VERSION ""

NS_ :

BS_:

BU_: SGW RFHM MPAD IPC GNMM EVCU2 ESL ECM DTCM DMSM BSM BCM AGSM ADCAM

BO_ 2654339199 PDC_INFO_FD_VRM: 12 SGW
 SG_ GenericFailSts_FD08_VRM : 5|1@0+ (1,0) [0|1] "" Vector__XXX
 SG_ EOL_FD08_VRM : 7|1@0+ (1,0) [0|1] "-"  Vector__XXX
 SG_ CurrentFailSts_FD08_VRM : 6|1@0+ (1,0) [0|1] "" Vector__XXX
 SG_ WakeupSource_FD08_VRM : 23|8@0+ (1,0) [0|255] "" Vector__XXX
 SG_ PreviousCanNMState_FD08_VRM : 11|4@0+ (1,0) [0|15] "" Vector__XXX
 SG_ DES_FD08_VRM : 4|2@0+ (1,0) [0|3] "" Vector__XXX
 SG_ CurrentCanNMState_FD08_VRM : 15|4@0+ (1,0) [0|15] "" Vector__XXX
 SG_ StayActiveSource_FD08_VRM : 31|64@0+ (1,0) [0|18446744073709600000] "" Vector__XXX

BO_ 2654339107 PDC_INFO_FD_TBM: 12 SGW
 SG_ GenericFailSts_FD08_TBM : 5|1@0+ (1,0) [0|1] "" BCM
 SG_ EOL_FD08_TBM : 7|1@0+ (1,0) [0|1] "-"  BCM
 SG_ CurrentFailSts_FD08_TBM : 6|1@0+ (1,0) [0|1] "" BCM
 SG_ WakeupSource_FD08_TBM : 23|8@0+ (1,0) [0|255] "" Vector__XXX
 SG_ PreviousCanNMState_FD08_TBM : 11|4@0+ (1,0) [0|15] "" Vector__XXX
 SG_ DES_FD08_TBM : 4|2@0+ (1,0) [0|3] "" Vector__XXX
 SG_ CurrentCanNMState_FD08_TBM : 15|4@0+ (1,0) [0|15] "" Vector__XXX
 SG_ StayActiveSource_FD08_TBM : 31|64@0+ (1,0) [0|18446744073709551615] "" Vector__XXX

BO_ 2654339075 PDC_INFO_FD_IPC: 12 IPC
 SG_ GenericFailSts_FD03_IPC : 5|1@0+ (1,0) [0|1] "" SGW,BCM
 SG_ EOL_FD03_IPC : 7|1@0+ (1,0) [0|1] "-"  SGW,BCM
 SG_ CurrentFailSts_FD03_IPC : 6|1@0+ (1,0) [0|1] "" SGW,BCM
 SG_ WakeupSource_FD03_IPC : 23|8@0+ (1,0) [0|255] "" SGW
 SG_ PreviousCanNMState_FD03_IPC : 11|4@0+ (1,0) [0|15] "" SGW
 SG_ DES_FD03_IPC : 4|2@0+ (1,0) [0|3] "" SGW
 SG_ CurrentCanNMState_FD03_IPC : 15|4@0+ (1,0) [0|15] "" SGW
 SG_ StayActiveSource_FD03_IPC : 31|64@0+ (1,0) [0|18446744073709600000] "" SGW

BO_ 2654339216 PDC_INFO_FD_GNMM: 12 GNMM
 SG_ GenericFailSts_FD03_GNMM : 5|1@0+ (1,0) [0|1] "" SGW,BCM
 SG_ EOL_FD03_GNMM : 7|1@0+ (1,0) [0|1] "-"  SGW,BCM
 SG_ CurrentFailSts_FD03_GNMM : 6|1@0+ (1,0) [0|1] "" SGW,BCM
 SG_ WakeupSource_FD03_GNMM : 23|8@0+ (1,0) [0|255] "" SGW
 SG_ PreviousCanNMState_FD03_GNMM : 11|4@0+ (1,0) [0|15] "" SGW
 SG_ DES_FD03_GNMM : 4|2@0+ (1,0) [0|3] "" SGW
 SG_ CurrentCanNMState_FD03_GNMM : 15|4@0+ (1,0) [0|3] "" SGW
 SG_ StayActiveSource_FD03_GNMM : 31|64@0+ (1,0) [0|18446744073709551615] "" SGW

BO_ 2654339108 PDC_INFO_FD_ETM: 12 SGW
 SG_ GenericFailSts_FD08_ETM : 5|1@0+ (1,0) [0|1] "" BCM
 SG_ EOL_FD08_ETM : 7|1@0+ (1,0) [0|1] "-"  BCM
 SG_ CurrentFailSts_FD08_ETM : 6|1@0+ (1,0) [0|1] "" BCM
 SG_ WakeupSource_FD08_ETM : 23|8@0+ (1,0) [0|255] "" Vector__XXX
 SG_ PreviousCanNMState_FD08_ETM : 11|4@0+ (1,0) [0|15] "" Vector__XXX
 SG_ DES_FD08_ETM : 4|2@0+ (1,0) [0|3] "" Vector__XXX
 SG_ CurrentCanNMState_FD08_ETM : 15|4@0+ (1,0) [0|15] "" Vector__XXX
 SG_ StayActiveSource_FD08_ETM : 31|64@0+ (1,0) [0|18446744073709551615] "" Vector__XXX

BO_ 2654339093 PDC_INFO_FD_ESL: 12 ESL
 SG_ GenericFailSts_FD03_ESL : 5|1@0+ (1,0) [0|1] "" SGW,BCM
 SG_ EOL_FD03_ESL : 7|1@0+ (1,0) [0|1] "-"  SGW,BCM
 SG_ CurrentFailSts_FD03_ESL : 6|1@0+ (1,0) [0|1] "" SGW,BCM
 SG_ WakeupSource_FD03_ESL : 23|8@0+ (1,0) [0|255] "" SGW
 SG_ PreviousCanNMState_FD03_ESL : 11|4@0+ (1,0) [0|15] "" SGW
 SG_ DES_FD03_ESL : 4|2@0+ (1,0) [0|3] "" SGW
 SG_ CurrentCanNMState_FD03_ESL : 15|4@0+ (1,0) [0|15] "" SGW
 SG_ StayActiveSource_FD03_ESL : 31|64@0+ (1,0) [0|18446744073709600000] "" SGW

BO_ 2654339172 PDC_INFO_FD_DTV: 12 SGW
 SG_ GenericFailSts_FD08_DTV : 5|1@0+ (1,0) [0|1] "" BCM
 SG_ EOL_FD08_DTV : 7|1@0+ (1,0) [0|1] "-"  BCM
 SG_ CurrentFailSts_FD08_DTV : 6|1@0+ (1,0) [0|1] "" BCM
 SG_ WakeupSource_FD08_DTV : 23|8@0+ (1,0) [0|255] "" Vector__XXX
 SG_ PreviousCanNMState_FD08_DTV : 11|4@0+ (1,0) [0|15] "" Vector__XXX
 SG_ DES_FD08_DTV : 4|2@0+ (1,0) [0|3] "" Vector__XXX
 SG_ CurrentCanNMState_FD08_DTV : 15|4@0+ (1,0) [0|15] "" Vector__XXX
 SG_ StayActiveSource_FD08_DTV : 31|64@0+ (1,0) [0|18446744073709551615] "" Vector__XXX

BO_ 2654339139 PDC_INFO_FD_DTCM: 12 DTCM
 SG_ GenericFailSts_FD03_DTCM : 5|1@0+ (1,0) [0|1] "" SGW,BCM
 SG_ EOL_FD03_DTCM : 7|1@0+ (1,0) [0|1] "-"  SGW,BCM
 SG_ CurrentFailSts_FD03_DTCM : 6|1@0+ (1,0) [0|1] "" SGW,BCM
 SG_ WakeupSource_FD03_DTCM : 23|8@0+ (1,0) [0|255] "" SGW
 SG_ PreviousCanNMState_FD03_DTCM : 11|4@0+ (1,0) [0|15] "" SGW
 SG_ DES_FD03_DTCM : 4|2@0+ (1,0) [0|3] "" SGW
 SG_ CurrentCanNMState_FD03_DTCM : 15|4@0+ (1,0) [0|15] "" SGW
 SG_ StayActiveSource_FD03_DTCM : 31|64@0+ (1,0) [0|18446744073709600000] "" SGW

BO_ 2654339225 PDC_INFO_FD_DMSM: 12 DMSM
 SG_ GenericFailSts_FD03_DMSM : 5|1@0+ (1,0) [0|1] "" SGW,BCM
 SG_ EOL_FD03_DMSM : 7|1@0+ (1,0) [0|1] "-"  SGW,BCM
 SG_ CurrentFailSts_FD03_DMSM : 6|1@0+ (1,0) [0|1] "" SGW,BCM
 SG_ WakeupSource_FD03_DMSM : 23|8@0+ (1,0) [0|255] "" SGW
 SG_ PreviousCanNMState_FD03_DMSM : 11|4@0+ (1,0) [0|15] "" SGW
 SG_ DES_FD03_DMSM : 4|2@0+ (1,0) [0|3] "" SGW
 SG_ CurrentCanNMState_FD03_DMSM : 15|4@0+ (1,0) [0|15] "" SGW
 SG_ StayActiveSource_FD03_DMSM : 31|64@0+ (1,0) [0|18446744073709600000] "" SGW

BO_ 2654339078 PDC_INFO_FD_BSM: 12 BSM
 SG_ GenericFailSts_FD03_BSM : 5|1@0+ (1,0) [0|1] "" SGW,BCM
 SG_ EOL_FD03_BSM : 7|1@0+ (1,0) [0|1] "-"  SGW,BCM
 SG_ DES_FD03_BSM : 4|2@0+ (1,0) [0|1] "" SGW
 SG_ CurrentFailSts_FD03_BSM : 6|1@0+ (1,0) [0|1] "" SGW,BCM
 SG_ WakeupSource_FD03_BSM : 23|8@0+ (1,0) [0|255] "" SGW
 SG_ PreviousCanNMState_FD03_BSM : 11|4@0+ (1,0) [0|15] "" SGW
 SG_ CurrentCanNMState_FD03_BSM : 15|4@0+ (1,0) [0|15] "" SGW
 SG_ StayActiveSource_FD03_BSM : 31|64@0+ (1,0) [0|18446744073709551615] "" SGW

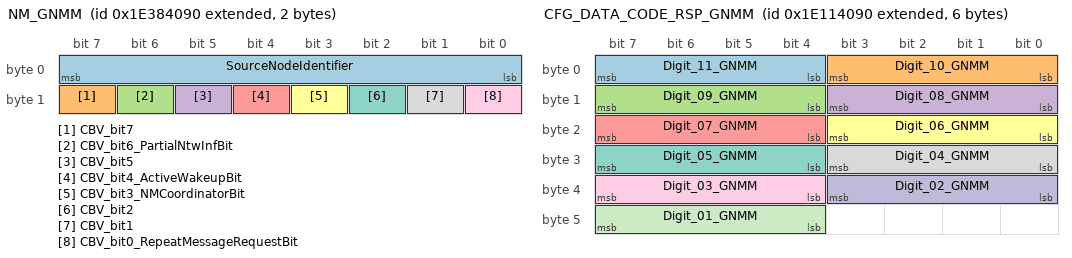
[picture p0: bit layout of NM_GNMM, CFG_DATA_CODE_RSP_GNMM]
BO_ 2654486672 NM_GNMM: 2 GNMM
 SG_ SourceNodeIdentifier : 7|8@0+ (1,0) [0|255] "-"  ADCAM,MPAD,EVCU2,SGW,AGSM,ESL,BCM,BSM,IPC,RFHM,ECM,DTCM
 SG_ CBV_bit7 : 15|1@0+ (1,0) [0|1] "" ADCAM,MPAD,EVCU2,SGW,AGSM,ESL,BCM,BSM,IPC,RFHM,ECM,DTCM
 SG_ CBV_bit6_PartialNtwInfBit : 14|1@0+ (1,0) [0|1] "" ADCAM,MPAD,EVCU2,SGW,AGSM,ESL,BCM,BSM,IPC,RFHM,ECM,DTCM
 SG_ CBV_bit5 : 13|1@0+ (1,0) [0|1] "" ADCAM,MPAD,EVCU2,SGW,AGSM,ESL,BCM,BSM,IPC,RFHM,ECM,DTCM
 SG_ CBV_bit4_ActiveWakeupBit : 12|1@0+ (1,0) [0|1] "" ADCAM,MPAD,EVCU2,SGW,AGSM,ESL,BCM,BSM,IPC,RFHM,ECM,DTCM
 SG_ CBV_bit3_NMCoordinatorBit : 11|1@0+ (1,0) [0|1] "" ADCAM,MPAD,EVCU2,SGW,AGSM,ESL,BCM,BSM,IPC,RFHM,ECM,DTCM
 SG_ CBV_bit2 : 10|1@0+ (1,0) [0|1] "" ADCAM,MPAD,EVCU2,SGW,AGSM,ESL,BCM,BSM,IPC,RFHM,ECM,DTCM
 SG_ CBV_bit1 : 9|1@0+ (1,0) [0|1] "" ADCAM,MPAD,EVCU2,SGW,AGSM,ESL,BCM,BSM,IPC,RFHM,ECM,DTCM
 SG_ CBV_bit0_RepeatMessageRequestBit : 8|1@0+ (1,0) [0|1] "" ADCAM,MPAD,EVCU2,SGW,AGSM,ESL,BCM,BSM,IPC,RFHM,ECM,DTCM

BO_ 754 IBS3_DATA_1_2: 32 BCM
 SG_ VoltBattFailStatus_2 : 102|1@0+ (1,0) [0|1] "" EVCU2
 SG_ RsErrIBS3_2 : 100|1@0+ (1,0) [0|1] "" EVCU2
 SG_ IBS3_Error_Internal_2 : 101|1@0+ (1,0) [0|1] "" EVCU2
 SG_ CurrBattFailStatus_2 : 103|1@0+ (1,0) [0|1] "" EVCU2
 SG_ MessageCounter_IBS3DATA1_2 : 179|4@0+ (1,0) [0|15] ""  EVCU2
 SG_ CRC_IBS3DATA1_2 : 191|8@0+ (1,0) [0|255] ""  EVCU2

BO_ 1460 FOTA_MASTER: 32 SGW
 SG_ Safe_State : 0|1@0+ (1,0) [0|1] "" ADCAM,MPAD
 SG_ FOTA_Status : 7|4@0+ (1,0) [0|15] "" ADCAM,MPAD,BCM,BSM,IPC,ECM
 SG_ FOTA_Purge : 13|1@0+ (1,0) [0|1] "" ADCAM,MPAD
 SG_ FOTA_Installation_Status : 23|2@0+ (1,0) [0|3] "" EVCU2,RFHM
 SG_ FOTA_Install_Type : 21|2@0+ (1,0) [0|3] "" EVCU2,ECM
 SG_ MPAD_Big_ECU_Package : 19|1@0+ (1,0) [0|1] "" MPAD
 SG_ ADCAM_Big_ECU_Package : 8|1@0+ (1,0) [0|1] "" ADCAM
 SG_ MessageCounter_FOTA_MASTER : 179|4@0+ (1,0) [0|15] "-"  ADCAM,MPAD,EVCU2,BCM,BSM,IPC,RFHM
 SG_ CRC_FOTA_MASTER : 191|8@0+ (1,0) [0|255] "-"  ADCAM,MPAD,EVCU2,BCM,BSM,IPC,RFHM
 SG_ MPFC_Big_ECU_Package : 32|1@0+ (1,0) [0|1] "" MPAD

BO_ 1438 DRV_MONITOR1_FD: 32 DMSM
 SG_ MessageCounter_DRV_MONITOR1 : 179|4@0+ (1,0) [0|15] "-"  MPAD,BCM
 SG_ Driver_Presence : 15|1@0+ (1,0) [0|1] "" MPAD,SGW,BCM
 SG_ DMSM_System_Stat : 29|2@0+ (1,0) [0|3] "" MPAD,BCM
 SG_ DM_Zone_Track_Conf : 27|4@0+ (10,0) [0|150] "%"  MPAD,BCM
 SG_ DM_Zone_Track : 35|3@0+ (1,0) [0|7] "" MPAD,BCM
 SG_ DM_Drowsy_State : 37|2@0+ (1,0) [0|3] "" MPAD,SGW,BCM
 SG_ DM_Drowsy_Micro : 7|1@0+ (1,0) [0|1] "" MPAD,BCM
 SG_ DM_Drowsy_Instant : 14|7@0+ (1,0) [0|127] "%"  MPAD,BCM
 SG_ DM_Drowsy_Conf : 23|4@0+ (10,0) [0|150] "%"  MPAD,BCM
 SG_ DM_Distract_State : 39|2@0+ (1,0) [0|3] "" MPAD,SGW,BCM
 SG_ DM_Distract_Instant : 6|7@0+ (1,0) [0|127] "%"  MPAD,BCM
 SG_ DM_Distract_Conf : 19|4@0+ (10,0) [0|150] "%"  MPAD,BCM
 SG_ DM_Camera_Blind : 31|2@0+ (1,0) [0|3] "" MPAD,BCM
 SG_ CRC_DRV_MONITOR1 : 191|8@0+ (1,0) [0|255] "-"  MPAD,BCM
 SG_ DM_Eyes_Tracked : 32|1@0+ (1,0) [0|1] "" MPAD,BCM
 SG_ DM_Steering_Angle_Blockage : 47|1@0+ (1,0) [0|1] "" MPAD,BCM
 SG_ MAC_DRV_MONITOR1 : 215|48@0+ (1,0) [0|0] "-"  MPAD,BCM
 SG_ Cntr_DRV_MONITOR1 : 199|16@0+ (1,0) [0|0] "-"  MPAD,BCM
 SG_ DM_Unresponsive : 42|2@0+ (1,0) [0|3] "-"  MPAD,BCM
 SG_ DM_Drowsy_Level : 46|4@0+ (1,0) [0|15] "-"  MPAD,BCM
 SG_ DM_Distracted_Level : 55|4@0+ (1,0) [0|15] "-"  MPAD,BCM
 SG_ DM_Drowsy_Instant_Seconds : 70|7@0+ (1,0) [0|127] "s"  MPAD
 SG_ DM_Distract_Instant_Seconds : 62|7@0+ (1,0) [0|127] "s"  MPAD

BO_ 2564485428 DIAGNOSTIC_RESPONSE_GNMM: 8 GNMM
 SG_ N_PDU : 7|64@0+ (1,0) [0|0] "" SGW

BO_ 2564486464 DIAGNOSTIC_RESPONSE_FOTA_BCM: 64 BCM
 SG_ N_PDU : 7|64@0+ (1,0) [0|0] "" SGW

BO_ 2564485684 DIAGNOSTIC_RESPONSE_FD_GNMM: 64 GNMM
 SG_ N_PDU : 7|64@0+ (1,0) [0|0] "" SGW

BO_ 2564485783 DIAGNOSTIC_RESPONSE_FD_DMSM: 64 DMSM
 SG_ N_PDU : 7|64@0+ (1,0) [0|0] "" SGW

BO_ 2564485527 DIAGNOSTIC_RESPONSE_DMSM: 8 DMSM
 SG_ N_PDU : 7|64@0+ (1,0) [0|0] "" SGW

BO_ 2564437233 DIAGNOSTIC_REQUEST_GNMM: 8 SGW
 SG_ N_PDU : 7|64@0+ (1,0) [0|0] "" GNMM

BO_ 2564440309 DIAGNOSTIC_REQUEST_FOTA_BCM: 64 SGW
 SG_ N_PDU : 7|64@0+ (1,0) [0|0] "" BCM

BO_ 2564437234 DIAGNOSTIC_REQUEST_FD_GNMM: 64 SGW
 SG_ N_PDU : 7|64@0+ (1,0) [0|0] "" GNMM

BO_ 2564462578 DIAGNOSTIC_REQUEST_FD_DMSM: 64 SGW
 SG_ N_PDU : 7|64@0+ (1,0) [0|0] "" DMSM

BO_ 2564462577 DIAGNOSTIC_REQUEST_DMSM: 8 SGW
 SG_ N_PDU : 7|64@0+ (1,0) [0|0] "" DMSM

BO_ 2651930768 CFG_DATA_CODE_RSP_GNMM: 6 GNMM
 SG_ Digit_11_GNMM : 7|4@0+ (1,0) [0|15] "-"  BCM
 SG_ Digit_10_GNMM : 3|4@0+ (1,0) [0|15] "-"  BCM
 SG_ Digit_09_GNMM : 15|4@0+ (1,0) [0|15] "-"  BCM
 SG_ Digit_08_GNMM : 11|4@0+ (1,0) [0|15] "-"  BCM
 SG_ Digit_07_GNMM : 23|4@0+ (1,0) [0|15] "-"  BCM
 SG_ Digit_06_GNMM : 19|4@0+ (1,0) [0|15] "-"  BCM
 SG_ Digit_05_GNMM : 31|4@0+ (1,0) [0|15] "-"  BCM
 SG_ Digit_04_GNMM : 27|4@0+ (1,0) [0|15] "-"  BCM
 SG_ Digit_03_GNMM : 39|4@0+ (1,0) [0|15] "-"  BCM
 SG_ Digit_02_GNMM : 35|4@0+ (1,0) [0|15] "-"  BCM
 SG_ Digit_01_GNMM : 47|4@0+ (1,0) [0|15] "-"  BCM

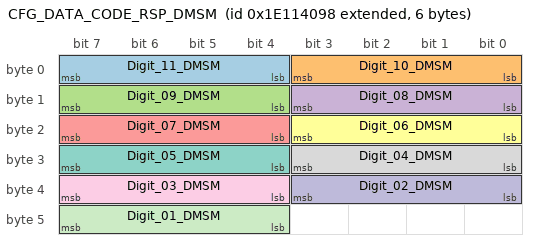
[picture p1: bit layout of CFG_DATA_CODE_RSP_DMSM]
BO_ 2651930776 CFG_DATA_CODE_RSP_DMSM: 6 DMSM
 SG_ Digit_11_DMSM : 7|4@0+ (1,0) [0|15] "-"  BCM
 SG_ Digit_10_DMSM : 3|4@0+ (1,0) [0|15] "-"  BCM
 SG_ Digit_09_DMSM : 15|4@0+ (1,0) [0|15] "-"  BCM
 SG_ Digit_08_DMSM : 11|4@0+ (1,0) [0|15] "-"  BCM
 SG_ Digit_07_DMSM : 23|4@0+ (1,0) [0|15] "-"  BCM
 SG_ Digit_06_DMSM : 19|4@0+ (1,0) [0|15] "-"  BCM
 SG_ Digit_05_DMSM : 31|4@0+ (1,0) [0|15] "-"  BCM
 SG_ Digit_04_DMSM : 27|4@0+ (1,0) [0|15] "-"  BCM
 SG_ Digit_03_DMSM : 39|4@0+ (1,0) [0|15] "-"  BCM
 SG_ Digit_02_DMSM : 35|4@0+ (1,0) [0|15] "-"  BCM
 SG_ Digit_01_DMSM : 47|4@0+ (1,0) [0|15] "-"  BCM

BO_ 524 BRAKE2_FD_2: 32 BCM
 SG_ VehicleStandStillSts_B2 : 47|2@0+ (1,0) [0|2] "" MPAD
 SG_ BSM2_OpStat : 50|3@0+ (1,0) [0|5] "" MPAD,BSM
 SG_ Brake_OpStat_Sec : 53|3@0+ (1,0) [0|5] "" MPAD
 SG_ MessageCounter_BRAKE2_2 : 179|4@0+ (1,0) [0|15] "-"  BSM
 SG_ CRC_BRAKE2_2 : 191|8@0+ (1,0) [0|255] "-"  BSM

BO_ 257 BRAKE2_FD_1: 64 BCM
 SG_ Ft_RrTrqCoupling_ModeRq_B2 : 158|2@0+ (1,0) [0|3] "-"  DTCM
 SG_ Ft_RrAxleCoupling_TrqRq_B2 : 143|8@0+ (12,0) [0|3060] "Nm"  DTCM

CM_ SG_ 2654339199 CurrentCanNMState_FD08_VRM "Indicates that CanNM state the ECU is currently executing";
CM_ SG_ 2654339199 CurrentFailSts_FD08_VRM "Indicates the presence/absence of at least one DTC with DTCStatus = present in the System Memory";
CM_ SG_ 2654339199 DES_FD08_VRM "Indicates whether the ECU?s CAN cell is in either ErrorActive, or ErrorPassive state OR has just now recovered from a BusOff condition";
CM_ SG_ 2654339199 EOL_FD08_VRM "Indicates if the ECU requires configuration data at the assembly plant End Of Line";
CM_ SG_ 2654339199 GenericFailSts_FD08_VRM "Indicates the presence/absent of at least one DTC in the System Memory";
CM_ SG_ 2654339199 PreviousCanNMState_FD08_VRM "Indicates the last CanNM state that the ECU existed in";
CM_ SG_ 2654339199 StayActiveSource_FD08_VRM "Indicates the source that requests the ECU to stay active";
CM_ SG_ 2654339199 WakeupSource_FD08_VRM "Indicates the reason the ECU was most recently awakened";
CM_ SG_ 2654339107 CurrentCanNMState_FD08_TBM "Indicates that CanNM state the ECU is currently executing";
CM_ SG_ 2654339107 CurrentFailSts_FD08_TBM "Indicates the presence/absence of at least one DTC with DTCStatus = present in the System Memory";
CM_ SG_ 2654339107 DES_FD08_TBM "Indicates whether the ECU?s CAN cell is in either ErrorActive, or ErrorPassive state OR has just now recovered from a BusOff condition";
CM_ SG_ 2654339107 EOL_FD08_TBM "Indicates if the ECU requires configuration data at the assembly plant End Of Line";
CM_ SG_ 2654339107 GenericFailSts_FD08_TBM "Indicates the presence/absent of at least one DTC in the System Memory";
CM_ SG_ 2654339107 PreviousCanNMState_FD08_TBM "Indicates the last CanNM state that the ECU existed in";
CM_ SG_ 2654339107 StayActiveSource_FD08_TBM "Indicates the source that requests the ECU to stay active";
CM_ SG_ 2654339107 WakeupSource_FD08_TBM "Indicates the reason the ECU was most recently awakened";
CM_ SG_ 2654339075 CurrentCanNMState_FD03_IPC "Indicates that CanNM state the ECU is currently executing";
CM_ SG_ 2654339075 CurrentFailSts_FD03_IPC "Indicates the presence/absence of at least one DTC with DTCStatus = present in the System Memory";
CM_ SG_ 2654339075 DES_FD03_IPC "Indicates whether the ECU?s CAN cell is in either ErrorActive, or ErrorPassive state OR has just now recovered from a BusOff condition";
CM_ SG_ 2654339075 EOL_FD03_IPC "Indicates if the ECU requires configuration data at the assembly plant End Of Line";
CM_ SG_ 2654339075 GenericFailSts_FD03_IPC "Indicates the presence/absent of at least one DTC in the System Memory";
CM_ SG_ 2654339075 PreviousCanNMState_FD03_IPC "Indicates the last CanNM state that the ECU existed in";
CM_ SG_ 2654339075 StayActiveSource_FD03_IPC "Indicates the source that requests the ECU to stay active";
CM_ SG_ 2654339075 WakeupSource_FD03_IPC "Indicates the reason the ECU was most recently awakened";
CM_ SG_ 2654339216 CurrentCanNMState_FD03_GNMM "Indicates that CanNM state the ECU is currently executing";
CM_ SG_ 2654339216 DES_FD03_GNMM "Indicates whether the ECU?s CAN cell is in either ErrorActive, or ErrorPassive state OR has just now recovered from a BusOff condition";
CM_ SG_ 2654339216 EOL_FD03_GNMM "Indicates if the ECU requires configuration data at the assembly plant End Of Line";
CM_ SG_ 2654339216 GenericFailSts_FD03_GNMM "Indicates the presence/absent of at least one DTC in the System Memory";
CM_ SG_ 2654339216 WakeupSource_FD03_GNMM "Indicates the reason the ECU was most recently awakened";
CM_ SG_ 2654339216 StayActiveSource_FD03_GNMM "Indicates the source that requests the ECU to stay active";
CM_ SG_ 2654339216 PreviousCanNMState_FD03_GNMM "Indicates the last CanNM state that the ECU existed in";
CM_ SG_ 2654339216 CurrentFailSts_FD03_GNMM "Indicates the presence/absence of at least one DTC with DTCStatus = present in the System Memory";
CM_ SG_ 2654339108 PreviousCanNMState_FD08_ETM "Indicates the last CanNM state that the ECU existed in";
CM_ SG_ 2654339108 StayActiveSource_FD08_ETM "Indicates the source that requests the ECU to stay active";
CM_ SG_ 2654339108 WakeupSource_FD08_ETM "Indicates the reason the ECU was most recently awakened";
CM_ SG_ 2654339108 GenericFailSts_FD08_ETM "Indicates the presence/absent of at least one DTC in the System Memory";
CM_ SG_ 2654339108 EOL_FD08_ETM "Indicates if the ECU requires configuration data at the assembly plant End Of Line";
CM_ SG_ 2654339108 DES_FD08_ETM "Indicates whether the ECU?s CAN cell is in either ErrorActive, or ErrorPassive state OR has just now recovered from a BusOff condition";
CM_ SG_ 2654339108 CurrentCanNMState_FD08_ETM "Indicates that CanNM state the ECU is currently executing";
CM_ SG_ 2654339108 CurrentFailSts_FD08_ETM "Indicates the presence/absence of at least one DTC with DTCStatus = present in the System Memory";
CM_ SG_ 2654339093 StayActiveSource_FD03_ESL "Indicates the source that requests the ECU to stay active";
CM_ SG_ 2654339093 GenericFailSts_FD03_ESL "Indicates the presence/absent of at least one DTC in the System Memory";
CM_ SG_ 2654339093 PreviousCanNMState_FD03_ESL "Indicates the last CanNM state that the ECU existed in";
CM_ SG_ 2654339093 WakeupSource_FD03_ESL "Indicates the reason the ECU was most recently awakened";
CM_ SG_ 2654339093 CurrentCanNMState_FD03_ESL "Indicates that CanNM state the ECU is currently executing";
CM_ SG_ 2654339093 CurrentFailSts_FD03_ESL "Indicates the presence/absence of at least one DTC with DTCStatus = present in the System Memory";
CM_ SG_ 2654339093 DES_FD03_ESL "Indicates whether the ECU?s CAN cell is in either ErrorActive, or ErrorPassive state OR has just now recovered from a BusOff condition";
CM_ SG_ 2654339093 EOL_FD03_ESL "Indicates if the ECU requires configuration data at the assembly plant End Of Line";
CM_ SG_ 2654339172 EOL_FD08_DTV "Indicates if the ECU requires configuration data at the assembly plant End Of Line";
CM_ SG_ 2654339172 GenericFailSts_FD08_DTV "Indicates the presence/absent of at least one DTC in the System Memory";
CM_ SG_ 2654339172 PreviousCanNMState_FD08_DTV "Indicates the last CanNM state that the ECU existed in";
CM_ SG_ 2654339172 StayActiveSource_FD08_DTV "Indicates the source that requests the ECU to stay active";
CM_ SG_ 2654339172 WakeupSource_FD08_DTV "Indicates the reason the ECU was most recently awakened";
CM_ SG_ 2654339172 CurrentCanNMState_FD08_DTV "Indicates that CanNM state the ECU is currently executing";
CM_ SG_ 2654339172 CurrentFailSts_FD08_DTV "Indicates the presence/absence of at least one DTC with DTCStatus = present in the System Memory";
CM_ SG_ 2654339172 DES_FD08_DTV "Indicates whether the ECU?s CAN cell is in either ErrorActive, or ErrorPassive state OR has just now recovered from a BusOff condition";
CM_ SG_ 2654339139 StayActiveSource_FD03_DTCM "Indicates the source that requests the ECU to stay active";
CM_ SG_ 2654339139 PreviousCanNMState_FD03_DTCM "Indicates the last CanNM state that the ECU existed in";
CM_ SG_ 2654339139 EOL_FD03_DTCM "Indicates if the ECU requires configuration data at the assembly plant End Of Line";
CM_ SG_ 2654339139 GenericFailSts_FD03_DTCM "Indicates the presence/absent of at least one DTC in the System Memory";
CM_ SG_ 2654339139 CurrentCanNMState_FD03_DTCM "Indicates that CanNM state the ECU is currently executing";
CM_ SG_ 2654339139 CurrentFailSts_FD03_DTCM "Indicates the presence/absence of at least one DTC with DTCStatus = present in the System Memory";
CM_ SG_ 2654339139 DES_FD03_DTCM "Indicates whether the ECU?s CAN cell is in either ErrorActive, or ErrorPassive state OR has just now recovered from a BusOff condition";
CM_ SG_ 2654339139 WakeupSource_FD03_DTCM "Indicates the reason the ECU was most recently awakened";
CM_ SG_ 2654339225 CurrentCanNMState_FD03_DMSM "Indicates that CanNM state the ECU is currently executing";
CM_ SG_ 2654339225 CurrentFailSts_FD03_DMSM "Indicates the presence/absence of at least one DTC with DTCStatus = present in the System Memory";
CM_ SG_ 2654339225 DES_FD03_DMSM "Indicates whether the ECU?s CAN cell is in either ErrorActive, or ErrorPassive state OR has just now recovered from a BusOff condition";
CM_ SG_ 2654339225 EOL_FD03_DMSM "Indicates if the ECU requires configuration data at the assembly plant End Of Line";
CM_ SG_ 2654339225 GenericFailSts_FD03_DMSM "Indicates the presence/absent of at least one DTC in the System Memory";
CM_ SG_ 2654339225 PreviousCanNMState_FD03_DMSM "Indicates the last CanNM state that the ECU existed in";
CM_ SG_ 2654339225 StayActiveSource_FD03_DMSM "Indicates the source that requests the ECU to stay active";
CM_ SG_ 2654339225 WakeupSource_FD03_DMSM "Indicates the reason the ECU was most recently awakened";
CM_ SG_ 2654339078 CurrentCanNMState_FD03_BSM "Indicates that CanNM state the ECU is currently executing";
CM_ SG_ 2654339078 CurrentFailSts_FD03_BSM "Indicates the presence/absence of at least one DTC with DTCStatus = present in the System Memory";
CM_ SG_ 2654339078 DES_FD03_BSM "Indicates whether the ECU?s CAN cell is in either ErrorActive, or ErrorPassive state OR has just now recovered from a BusOff condition";
CM_ SG_ 2654339078 EOL_FD03_BSM "Indicates if the ECU requires configuration data at the assembly plant End Of Line";
CM_ SG_ 2654339078 GenericFailSts_FD03_BSM "Indicates the presence/absent of at least one DTC in the System Memory";
CM_ SG_ 2654339078 PreviousCanNMState_FD03_BSM "Indicates the last CanNM state that the ECU existed in";
CM_ SG_ 2654339078 StayActiveSource_FD03_BSM "Indicates the source that requests the ECU to stay active";
CM_ SG_ 2654339078 WakeupSource_FD03_BSM "Indicates the reason the ECU was most recently awakened";
CM_ SG_ 2654486672 CBV_bit0_RepeatMessageRequestBit "Repeat Message Request Bit";
CM_ SG_ 2654486672 CBV_bit3_NMCoordinatorBit "NM Coordinator Sleep Bit";
CM_ SG_ 2654486672 CBV_bit4_ActiveWakeupBit "Active Wakeup Bit";
CM_ SG_ 2654486672 CBV_bit6_PartialNtwInfBit "Partial Network Information Bit (PNI)";
CM_ SG_ 2654486672 SourceNodeIdentifier "Source Node Identifier";
CM_ SG_ 754 CurrBattFailStatus_2 "Failure Status of Current meas. (internal defect)";
CM_ SG_ 754 CRC_IBS3DATA1_2 "CRC according to SAE J1850 standard at each frame transmission.";
CM_ SG_ 754 VoltBattFailStatus_2 "Failure Status of Voltage meas. (internal defect)";
CM_ SG_ 754 RsErrIBS3_2 "Response Error IBS; Error=[1]";
CM_ SG_ 754 MessageCounter_IBS3DATA1_2 "This signal is a counter used for safety checks strategies. This counter is incremented of 1 (one) unit at each frame transmission.";
CM_ SG_ 754 IBS3_Error_Internal_2 "Error in IBS calibration data; No Error = [0], Error = [1]";
CM_ SG_ 1460 MPAD_Big_ECU_Package "CADM_Big_ECU_Package";
CM_ SG_ 1460 MPFC_Big_ECU_Package "MPFC_Big_ECU_Package";
CM_ SG_ 1460 Safe_State "Safe_State";
CM_ SG_ 1460 ADCAM_Big_ECU_Package "CADM_Big_ECU_Package";
CM_ SG_ 1460 CRC_FOTA_MASTER "CRC according to SAE J1850 standard at each frame transmission.";
CM_ SG_ 1460 FOTA_Status "FOTA_Status";
CM_ SG_ 1460 FOTA_Install_Type "Type of FOTA Installation";
CM_ SG_ 1460 FOTA_Installation_Status "FOTA Installation Status";
CM_ SG_ 1460 FOTA_Purge "Target ECUs to Purge Downloaded FOTA Images";
CM_ SG_ 1460 MessageCounter_FOTA_MASTER "This signal is a counter used for safety checks strategies. This counter is incremented of 1 (one) unit at each frame transmission.";
CM_ SG_ 1438 DM_Drowsy_Micro "Microsleep detected";
CM_ SG_ 1438 DM_Drowsy_Level "Measurement of Drowsiness Level based on Karolinska Sleepiness Scale";
CM_ SG_ 1438 DM_Drowsy_Instant_Seconds "Instantaneous measurement of driver drowsiness level";
CM_ SG_ 1438 DM_Drowsy_Instant "Instantaneous measurement of driver drowsiness level";
CM_ SG_ 1438 DM_Distracted_Level "Measurement Level of distraction of driver";
CM_ SG_ 1438 DM_Drowsy_Conf "Confidence in driver DM_Drowsy_State value";
CM_ SG_ 1438 MAC_DRV_MONITOR1 "-";
CM_ SG_ 1438 MessageCounter_DRV_MONITOR1 "This signal is a counter used for safety checks strategies. This counter is incremented of 1 (one) unit at each frame transmission.";
CM_ SG_ 1438 DM_Unresponsive "State of driver responsiveness";
CM_ SG_ 1438 DM_Steering_Angle_Blockage "Driver monitoring camera blocked by steering wheel";
CM_ SG_ 1438 DM_Eyes_Tracked "DM_Eyes_Tracked";
CM_ SG_ 1438 DM_Drowsy_State "Classification of driver drowsiness after debounce and filtering";
CM_ SG_ 1438 DM_Zone_Track "Estimate of where driver is looking";
CM_ SG_ 1438 DM_Zone_Track_Conf "Confidence in DM_Zone_Track value";
CM_ SG_ 1438 Driver_Presence "Indication of whether driver is detected by the monitoring system";
CM_ SG_ 1438 DMSM_System_Stat "Reported capability of DMSM to provide monitoring information";
CM_ SG_ 1438 Cntr_DRV_MONITOR1 "-";
CM_ SG_ 1438 CRC_DRV_MONITOR1 "CRC according to SAE J1850 standard at each frame transmission.";
CM_ SG_ 1438 DM_Camera_Blind "Degree of driver monitoring camera blindness";
CM_ SG_ 1438 DM_Distract_Conf "Confidence in driver DM_Distract_State value";
CM_ SG_ 1438 DM_Distract_Instant "Instantaneous measurement of driver distraction level";
CM_ SG_ 1438 DM_Distract_Instant_Seconds "Instantaneous measurement of driver distraction level";
CM_ SG_ 1438 DM_Distract_State "Classification of driver distraction after debounce and filtering";
CM_ SG_ 2564485428 N_PDU "This signal is used for diagnostic purposes";
CM_ SG_ 2564486464 N_PDU "This signal is used for diagnostic purposes";
CM_ SG_ 2564485684 N_PDU "This signal is used for diagnostic purposes";
CM_ SG_ 2564485783 N_PDU "This signal is used for diagnostic purposes";
CM_ SG_ 2564485527 N_PDU "This signal is used for diagnostic purposes";
CM_ SG_ 2564437233 N_PDU "This signal is used for diagnostic purposes";
CM_ SG_ 2564440309 N_PDU "This signal is used for diagnostic purposes";
CM_ SG_ 2564437234 N_PDU "This signal is used for diagnostic purposes";
CM_ SG_ 2564462578 N_PDU "This signal is used for diagnostic purposes";
CM_ SG_ 2564462577 N_PDU "This signal is used for diagnostic purposes";
CM_ SG_ 524 VehicleStandStillSts_B2 "VehicleStandStillSts_B2";
CM_ SG_ 524 MessageCounter_BRAKE2_2 "This signal is a counter used for safety checks strategies. This counter is incremented of 1 (one) unit at each frame transmission.";
CM_ SG_ 524 CRC_BRAKE2_2 "CRC according to SAE J1850 standard at each frame transmission.";
CM_ SG_ 524 BSM2_OpStat "Capability of the secondary brake control module to provide deceleration and/or stability control";
CM_ SG_ 524 Brake_OpStat_Sec "Capability of the Braking system to perform deceleration and/or stability control as reported by the secondary actuator.";
CM_ SG_ 257 Ft_RrTrqCoupling_ModeRq_B2 "ESP Requested Center Differential State";
CM_ SG_ 257 Ft_RrAxleCoupling_TrqRq_B2 "Desired Torque for Center Diff";
BA_DEF_ BO_ "CANFD_BRS" ENUM "0","1";
BA_DEF_ BO_ "VFrameFormat" ENUM "StandardCAN","ExtendedCAN","reserved","reserved","reserved","reserved","reserved","reserved","reserved","reserved","reserved","reserved","reserved","reserved","StandardCAN_FD","ExtendedCAN_FD";
BA_DEF_ BO_ "DiagConnection" HEX 0 65535;
BA_DEF_ BO_ "DiagState" ENUM "No","Yes";
BA_DEF_ BO_ "NmAsrMessage" ENUM "No","Yes";
BA_DEF_ BO_ "GenMsgDelayTime" INT 0 65535;
BA_DEF_ BO_ "GenMsgCycleTime" INT 0 65535;
BA_DEF_ BO_ "GenMsgCycleTimeFast" INT 0 65535;
BA_DEF_ BO_ "GenMsgStartDelayTime" INT 0 65535;
BA_DEF_ BO_ "GenMsgILSupport" ENUM "No","Yes";
BA_DEF_ BO_ "GenMsgNrOfRepetition" INT 0 255;
BA_DEF_ BO_ "GenMsgSendType" ENUM "Cyclic","NotUsed","NotUsed","NotUsed","NotUsed","NotUsed","NotUsed","NotUsed","NoMsgSendType";
BA_DEF_ BO_ "NmMessage" ENUM "No","Yes";
BA_DEF_ BO_ "DiagResponse" ENUM "No","Yes";
BA_DEF_ BO_ "Type" ENUM "P","C","PE","COC","PE_Cntrl","E","E_Cntrl","OC","S","BAF","DC","EM","MM","ISO-TP","-";
BA_DEF_ BO_ "DiagRequest" ENUM "No","Yes";
BA_DEF_ SG_ "GenSigTimeoutTime_SGW" INT 0 65535;
BA_DEF_ SG_ "GenSigTimeoutTime_RFHM" INT 0 65535;
BA_DEF_ SG_ "GenSigTimeoutTime_MPAD" INT 0 65535;
BA_DEF_ SG_ "GenSigTimeoutTime_IPC" INT 0 65535;
BA_DEF_ SG_ "GenSigTimeoutTime_GNMM" INT 0 65535;
BA_DEF_ SG_ "GenSigTimeoutTime_EVCU2" INT 0 65535;
BA_DEF_ SG_ "GenSigTimeoutTime_ESL" INT 0 65535;
BA_DEF_ SG_ "GenSigTimeoutTime_ECM" INT 0 65535;
BA_DEF_ SG_ "GenSigTimeoutTime_DTCM" INT 0 65535;
BA_DEF_ SG_ "GenSigTimeoutTime_DMSM" INT 0 65535;
BA_DEF_ SG_ "GenSigTimeoutTime_BSM" INT 0 65535;
BA_DEF_ SG_ "GenSigTimeoutTime_BCM" INT 0 65535;
BA_DEF_ SG_ "GenSigTimeoutTime_AGSM" INT 0 65535;
BA_DEF_ SG_ "GenSigTimeoutTime_ADCAM" INT 0 65535;
BA_DEF_ SG_ "SystemSignalLongSymbol" STRING ;
BA_DEF_ SG_ "GenSigSendType" ENUM "NotUsed","OnWrite","OnWriteWithRepetition","OnChange","OnChangeWithRepetition","IfActive","IfActiveWithRepetition","NoSigSendType";
BA_DEF_ SG_ "GenSigInactiveValue" INT 0 2147483647;
BA_DEF_ SG_ "GenSigStartValue" INT 0 2147483647;
BA_DEF_DEF_ "CANFD_BRS" "0";
BA_DEF_DEF_ "VFrameFormat" "StandardCAN_FD";
BA_DEF_DEF_ "DiagConnection" 0;
BA_DEF_DEF_ "DiagState" "No";
BA_DEF_DEF_ "NmAsrMessage" "No";
BA_DEF_DEF_ "GenMsgDelayTime" 0;
BA_DEF_DEF_ "GenMsgCycleTime" 0;
BA_DEF_DEF_ "GenMsgCycleTimeFast" 0;
BA_DEF_DEF_ "GenMsgStartDelayTime" 0;
BA_DEF_DEF_ "GenMsgILSupport" "No";
BA_DEF_DEF_ "GenMsgNrOfRepetition" 0;
BA_DEF_DEF_ "GenMsgSendType" "NoMsgSendType";
BA_DEF_DEF_ "NmMessage" "No";
BA_DEF_DEF_ "DiagResponse" "No";
BA_DEF_DEF_ "Type" "-";
BA_DEF_DEF_ "DiagRequest" "No";
BA_DEF_DEF_ "GenSigTimeoutTime_SGW" 2500;
BA_DEF_DEF_ "GenSigTimeoutTime_RFHM" 2500;
BA_DEF_DEF_ "GenSigTimeoutTime_MPAD" 2500;
BA_DEF_DEF_ "GenSigTimeoutTime_IPC" 2500;
BA_DEF_DEF_ "GenSigTimeoutTime_GNMM" 2500;
BA_DEF_DEF_ "GenSigTimeoutTime_EVCU2" 2500;
BA_DEF_DEF_ "GenSigTimeoutTime_ESL" 2500;
BA_DEF_DEF_ "GenSigTimeoutTime_ECM" 2500;
BA_DEF_DEF_ "GenSigTimeoutTime_DTCM" 2500;
BA_DEF_DEF_ "GenSigTimeoutTime_DMSM" 2500;
BA_DEF_DEF_ "GenSigTimeoutTime_BSM" 2500;
BA_DEF_DEF_ "GenSigTimeoutTime_BCM" 2500;
BA_DEF_DEF_ "GenSigTimeoutTime_AGSM" 2500;
BA_DEF_DEF_ "GenSigTimeoutTime_ADCAM" 2500;
BA_DEF_DEF_ "SystemSignalLongSymbol" "";
BA_DEF_DEF_ "GenSigSendType" "NoSigSendType";
BA_DEF_DEF_ "GenSigInactiveValue" 0;
BA_DEF_DEF_ "GenSigStartValue" 0;
BA_ "CANFD_BRS" BO_ 2654339199 1;
BA_ "VFrameFormat" BO_ 2654339199 15;
BA_ "GenMsgCycleTime" BO_ 2654339199 1000;
BA_ "GenMsgILSupport" BO_ 2654339199 1;
BA_ "GenMsgSendType" BO_ 2654339199 0;
BA_ "Type" BO_ 2654339199 1;
BA_ "CANFD_BRS" BO_ 2654339107 1;
BA_ "VFrameFormat" BO_ 2654339107 15;
BA_ "GenMsgCycleTime" BO_ 2654339107 1000;
BA_ "GenMsgILSupport" BO_ 2654339107 1;
BA_ "GenMsgSendType" BO_ 2654339107 0;
BA_ "Type" BO_ 2654339107 1;
BA_ "CANFD_BRS" BO_ 2654339075 1;
BA_ "VFrameFormat" BO_ 2654339075 15;
BA_ "GenMsgCycleTime" BO_ 2654339075 1000;
BA_ "GenMsgILSupport" BO_ 2654339075 1;
BA_ "GenMsgSendType" BO_ 2654339075 0;
BA_ "Type" BO_ 2654339075 1;
BA_ "CANFD_BRS" BO_ 2654339216 1;
BA_ "VFrameFormat" BO_ 2654339216 15;
BA_ "GenMsgCycleTime" BO_ 2654339216 1000;
BA_ "GenMsgILSupport" BO_ 2654339216 1;
BA_ "GenMsgSendType" BO_ 2654339216 0;
BA_ "Type" BO_ 2654339216 1;
BA_ "CANFD_BRS" BO_ 2654339108 1;
BA_ "VFrameFormat" BO_ 2654339108 15;
BA_ "GenMsgCycleTime" BO_ 2654339108 1000;
BA_ "GenMsgILSupport" BO_ 2654339108 1;
BA_ "GenMsgSendType" BO_ 2654339108 0;
BA_ "Type" BO_ 2654339108 1;
BA_ "CANFD_BRS" BO_ 2654339093 1;
BA_ "VFrameFormat" BO_ 2654339093 15;
BA_ "GenMsgCycleTime" BO_ 2654339093 1000;
BA_ "GenMsgILSupport" BO_ 2654339093 1;
BA_ "GenMsgSendType" BO_ 2654339093 0;
BA_ "Type" BO_ 2654339093 1;
BA_ "CANFD_BRS" BO_ 2654339172 1;
BA_ "VFrameFormat" BO_ 2654339172 15;
BA_ "GenMsgCycleTime" BO_ 2654339172 1000;
BA_ "GenMsgILSupport" BO_ 2654339172 1;
BA_ "GenMsgSendType" BO_ 2654339172 0;
BA_ "Type" BO_ 2654339172 1;
BA_ "CANFD_BRS" BO_ 2654339139 1;
BA_ "VFrameFormat" BO_ 2654339139 15;
BA_ "GenMsgCycleTime" BO_ 2654339139 1000;
BA_ "GenMsgILSupport" BO_ 2654339139 1;
BA_ "GenMsgSendType" BO_ 2654339139 0;
BA_ "Type" BO_ 2654339139 1;
BA_ "CANFD_BRS" BO_ 2654339225 1;
BA_ "VFrameFormat" BO_ 2654339225 15;
BA_ "GenMsgCycleTime" BO_ 2654339225 1000;
BA_ "GenMsgILSupport" BO_ 2654339225 1;
BA_ "GenMsgSendType" BO_ 2654339225 0;
BA_ "Type" BO_ 2654339225 1;
BA_ "CANFD_BRS" BO_ 2654339078 1;
BA_ "VFrameFormat" BO_ 2654339078 15;
BA_ "GenMsgCycleTime" BO_ 2654339078 1000;
BA_ "GenMsgILSupport" BO_ 2654339078 1;
BA_ "GenMsgSendType" BO_ 2654339078 0;
BA_ "Type" BO_ 2654339078 1;
BA_ "CANFD_BRS" BO_ 2654486672 1;
BA_ "VFrameFormat" BO_ 2654486672 15;
BA_ "NmAsrMessage" BO_ 2654486672 1;
BA_ "NmMessage" BO_ 2654486672 1;
BA_ "Type" BO_ 2654486672 8;
BA_ "CANFD_BRS" BO_ 754 1;
BA_ "GenMsgCycleTime" BO_ 754 50;
BA_ "GenMsgStartDelayTime" BO_ 754 45;
BA_ "GenMsgILSupport" BO_ 754 1;
BA_ "GenMsgSendType" BO_ 754 0;
BA_ "Type" BO_ 754 1;
BA_ "CANFD_BRS" BO_ 1460 1;
BA_ "GenMsgDelayTime" BO_ 1460 20;
BA_ "GenMsgCycleTime" BO_ 1460 1000;
BA_ "GenMsgILSupport" BO_ 1460 1;
BA_ "GenMsgSendType" BO_ 1460 0;
BA_ "Type" BO_ 1460 3;
BA_ "CANFD_BRS" BO_ 1438 1;
BA_ "GenMsgDelayTime" BO_ 1438 20;
BA_ "GenMsgCycleTime" BO_ 1438 1000;
BA_ "GenMsgCycleTimeFast" BO_ 1438 20;
BA_ "GenMsgILSupport" BO_ 1438 1;
BA_ "GenMsgNrOfRepetition" BO_ 1438 2;
BA_ "GenMsgSendType" BO_ 1438 0;
BA_ "Type" BO_ 1438 3;
BA_ "VFrameFormat" BO_ 2564485428 1;
BA_ "DiagConnection" BO_ 2564485428 61748;
BA_ "DiagResponse" BO_ 2564485428 1;
BA_ "Type" BO_ 2564485428 8;
BA_ "CANFD_BRS" BO_ 2564486464 1;
BA_ "VFrameFormat" BO_ 2564486464 15;
BA_ "DiagConnection" BO_ 2564486464 62784;
BA_ "DiagResponse" BO_ 2564486464 1;
BA_ "Type" BO_ 2564486464 8;
BA_ "CANFD_BRS" BO_ 2564485684 1;
BA_ "VFrameFormat" BO_ 2564485684 15;
BA_ "DiagConnection" BO_ 2564485684 62004;
BA_ "DiagResponse" BO_ 2564485684 1;
BA_ "Type" BO_ 2564485684 8;
BA_ "CANFD_BRS" BO_ 2564485783 1;
BA_ "VFrameFormat" BO_ 2564485783 15;
BA_ "DiagConnection" BO_ 2564485783 62103;
BA_ "DiagResponse" BO_ 2564485783 1;
BA_ "Type" BO_ 2564485783 8;
BA_ "VFrameFormat" BO_ 2564485527 1;
BA_ "DiagConnection" BO_ 2564485527 61847;
BA_ "DiagResponse" BO_ 2564485527 1;
BA_ "Type" BO_ 2564485527 8;
BA_ "VFrameFormat" BO_ 2564437233 1;
BA_ "DiagConnection" BO_ 2564437233 61748;
BA_ "Type" BO_ 2564437233 8;
BA_ "DiagRequest" BO_ 2564437233 1;
BA_ "Type" BO_ 2564440309 8;
BA_ "DiagRequest" BO_ 2564440309 1;
BA_ "CANFD_BRS" BO_ 2564440309 1;
BA_ "VFrameFormat" BO_ 2564440309 15;
BA_ "DiagConnection" BO_ 2564440309 62784;
BA_ "CANFD_BRS" BO_ 2564437234 1;
BA_ "VFrameFormat" BO_ 2564437234 15;
BA_ "DiagConnection" BO_ 2564437234 62004;
BA_ "Type" BO_ 2564437234 8;
BA_ "DiagRequest" BO_ 2564437234 1;
BA_ "CANFD_BRS" BO_ 2564462578 1;
BA_ "VFrameFormat" BO_ 2564462578 15;
BA_ "DiagConnection" BO_ 2564462578 62103;
BA_ "Type" BO_ 2564462578 8;
BA_ "DiagRequest" BO_ 2564462578 1;
BA_ "VFrameFormat" BO_ 2564462577 1;
BA_ "DiagConnection" BO_ 2564462577 61847;
BA_ "Type" BO_ 2564462577 8;
BA_ "DiagRequest" BO_ 2564462577 1;
BA_ "CANFD_BRS" BO_ 2651930768 1;
BA_ "VFrameFormat" BO_ 2651930768 15;
BA_ "GenMsgILSupport" BO_ 2651930768 1;
BA_ "Type" BO_ 2651930768 11;
BA_ "CANFD_BRS" BO_ 2651930776 1;
BA_ "VFrameFormat" BO_ 2651930776 15;
BA_ "GenMsgILSupport" BO_ 2651930776 1;
BA_ "Type" BO_ 2651930776 11;
BA_ "CANFD_BRS" BO_ 524 1;
BA_ "GenMsgCycleTime" BO_ 524 20;
BA_ "GenMsgILSupport" BO_ 524 1;
BA_ "GenMsgSendType" BO_ 524 0;
BA_ "Type" BO_ 524 1;
BA_ "CANFD_BRS" BO_ 257 1;
BA_ "GenMsgCycleTime" BO_ 257 10;
BA_ "GenMsgILSupport" BO_ 257 1;
BA_ "GenMsgSendType" BO_ 257 0;
BA_ "Type" BO_ 257 1;
BA_ "GenSigTimeoutTime_SGW" SG_ 2564486464 N_PDU 0;
BA_ "GenSigTimeoutTime_RFHM" SG_ 2564486464 N_PDU 0;
BA_ "GenSigTimeoutTime_MPAD" SG_ 2564486464 N_PDU 0;
BA_ "GenSigTimeoutTime_IPC" SG_ 2564486464 N_PDU 0;
BA_ "GenSigTimeoutTime_GNMM" SG_ 2564486464 N_PDU 0;
BA_ "GenSigTimeoutTime_EVCU2" SG_ 2564486464 N_PDU 0;
BA_ "GenSigTimeoutTime_ESL" SG_ 2564486464 N_PDU 0;
BA_ "GenSigTimeoutTime_ECM" SG_ 2564486464 N_PDU 0;
BA_ "GenSigTimeoutTime_DTCM" SG_ 2564486464 N_PDU 0;
BA_ "GenSigTimeoutTime_DMSM" SG_ 2564486464 N_PDU 0;
BA_ "GenSigTimeoutTime_BSM" SG_ 2564486464 N_PDU 0;
BA_ "GenSigTimeoutTime_BCM" SG_ 2564486464 N_PDU 0;
BA_ "GenSigTimeoutTime_AGSM" SG_ 2564486464 N_PDU 0;
BA_ "GenSigTimeoutTime_ADCAM" SG_ 2564486464 N_PDU 0;
BA_ "GenSigTimeoutTime_RFHM" SG_ 2654339078 CurrentCanNMState_FD03_BSM 0;
BA_ "GenSigTimeoutTime_MPAD" SG_ 2654339078 CurrentCanNMState_FD03_BSM 0;
BA_ "GenSigTimeoutTime_IPC" SG_ 2654339078 CurrentCanNMState_FD03_BSM 0;
BA_ "GenSigTimeoutTime_GNMM" SG_ 2654339078 CurrentCanNMState_FD03_BSM 0;
BA_ "GenSigTimeoutTime_EVCU2" SG_ 2654339078 CurrentCanNMState_FD03_BSM 0;
BA_ "GenSigTimeoutTime_ESL" SG_ 2654339078 CurrentCanNMState_FD03_BSM 0;
BA_ "GenSigTimeoutTime_ECM" SG_ 2654339078 CurrentCanNMState_FD03_BSM 0;
BA_ "GenSigTimeoutTime_DTCM" SG_ 2654339078 CurrentCanNMState_FD03_BSM 0;
BA_ "GenSigTimeoutTime_DMSM" SG_ 2654339078 CurrentCanNMState_FD03_BSM 0;
BA_ "GenSigTimeoutTime_BSM" SG_ 2654339078 CurrentCanNMState_FD03_BSM 0;
BA_ "GenSigTimeoutTime_BCM" SG_ 2654339078 CurrentCanNMState_FD03_BSM 0;
BA_ "GenSigTimeoutTime_AGSM" SG_ 2654339078 CurrentCanNMState_FD03_BSM 0;
BA_ "GenSigTimeoutTime_ADCAM" SG_ 2654339078 CurrentCanNMState_FD03_BSM 0;
BA_ "GenSigTimeoutTime_SGW" SG_ 2654339108 WakeupSource_FD08_ETM 0;
BA_ "GenSigTimeoutTime_RFHM" SG_ 2654339108 WakeupSource_FD08_ETM 0;
BA_ "GenSigTimeoutTime_MPAD" SG_ 2654339108 WakeupSource_FD08_ETM 0;
BA_ "GenSigTimeoutTime_IPC" SG_ 2654339108 WakeupSource_FD08_ETM 0;
BA_ "GenSigTimeoutTime_GNMM" SG_ 2654339108 WakeupSource_FD08_ETM 0;
BA_ "GenSigTimeoutTime_EVCU2" SG_ 2654339108 WakeupSource_FD08_ETM 0;
BA_ "GenSigTimeoutTime_ESL" SG_ 2654339108 WakeupSource_FD08_ETM 0;
BA_ "GenSigTimeoutTime_SGW" SG_ 2564485428 N_PDU 0;
BA_ "GenSigTimeoutTime_RFHM" SG_ 2564485428 N_PDU 0;
BA_ "GenSigTimeoutTime_MPAD" SG_ 2564485428 N_PDU 0;
BA_ "GenSigTimeoutTime_IPC" SG_ 2564485428 N_PDU 0;
BA_ "GenSigTimeoutTime_GNMM" SG_ 2564485428 N_PDU 0;
BA_ "GenSigTimeoutTime_EVCU2" SG_ 2564485428 N_PDU 0;
BA_ "GenSigTimeoutTime_ESL" SG_ 2564485428 N_PDU 0;
BA_ "GenSigTimeoutTime_ECM" SG_ 2564485428 N_PDU 0;
BA_ "GenSigTimeoutTime_DTCM" SG_ 2564485428 N_PDU 0;
BA_ "GenSigTimeoutTime_DMSM" SG_ 2564485428 N_PDU 0;
BA_ "GenSigTimeoutTime_BSM" SG_ 2564485428 N_PDU 0;
BA_ "GenSigTimeoutTime_BCM" SG_ 2564485428 N_PDU 0;
BA_ "GenSigTimeoutTime_AGSM" SG_ 2564485428 N_PDU 0;
BA_ "GenSigTimeoutTime_ADCAM" SG_ 2564485428 N_PDU 0;
BA_ "GenSigTimeoutTime_BCM" SG_ 2564485527 N_PDU 0;
BA_ "GenSigTimeoutTime_AGSM" SG_ 2564485527 N_PDU 0;
BA_ "GenSigTimeoutTime_ADCAM" SG_ 2564485527 N_PDU 0;
BA_ "GenSigTimeoutTime_SGW" SG_ 2564437233 N_PDU 0;
BA_ "GenSigTimeoutTime_RFHM" SG_ 2564437233 N_PDU 0;
BA_ "GenSigTimeoutTime_MPAD" SG_ 2564437233 N_PDU 0;
BA_ "GenSigTimeoutTime_IPC" SG_ 2564437233 N_PDU 0;
BA_ "GenSigTimeoutTime_GNMM" SG_ 2564437233 N_PDU 0;
BA_ "GenSigTimeoutTime_EVCU2" SG_ 2564437233 N_PDU 0;
BA_ "GenSigTimeoutTime_ESL" SG_ 2564437233 N_PDU 0;
BA_ "GenSigTimeoutTime_ECM" SG_ 2564437233 N_PDU 0;
BA_ "GenSigTimeoutTime_DTCM" SG_ 2564437233 N_PDU 0;
BA_ "GenSigTimeoutTime_DMSM" SG_ 2564437233 N_PDU 0;
BA_ "GenSigTimeoutTime_BSM" SG_ 2564437233 N_PDU 0;
BA_ "GenSigTimeoutTime_BCM" SG_ 2564437233 N_PDU 0;
BA_ "GenSigTimeoutTime_AGSM" SG_ 2564437233 N_PDU 0;
BA_ "GenSigTimeoutTime_ADCAM" SG_ 2564437233 N_PDU 0;
BA_ "GenSigTimeoutTime_SGW" SG_ 2564437234 N_PDU 0;
BA_ "GenSigTimeoutTime_RFHM" SG_ 2564437234 N_PDU 0;
BA_ "GenSigTimeoutTime_MPAD" SG_ 2564437234 N_PDU 0;
BA_ "GenSigTimeoutTime_IPC" SG_ 2564437234 N_PDU 0;
BA_ "GenSigTimeoutTime_GNMM" SG_ 2564437234 N_PDU 0;
BA_ "GenSigTimeoutTime_EVCU2" SG_ 2564437234 N_PDU 0;
BA_ "GenSigTimeoutTime_ESL" SG_ 2564437234 N_PDU 0;
BA_ "GenSigTimeoutTime_ECM" SG_ 2564437234 N_PDU 0;
BA_ "GenSigTimeoutTime_DTCM" SG_ 2564437234 N_PDU 0;
BA_ "GenSigTimeoutTime_DMSM" SG_ 2564437234 N_PDU 0;
BA_ "GenSigTimeoutTime_BSM" SG_ 2564437234 N_PDU 0;
BA_ "GenSigTimeoutTime_BCM" SG_ 2564437234 N_PDU 0;
BA_ "GenSigTimeoutTime_AGSM" SG_ 2564437234 N_PDU 0;
BA_ "GenSigTimeoutTime_ADCAM" SG_ 2564437234 N_PDU 0;
BA_ "GenSigTimeoutTime_SGW" SG_ 2564440309 N_PDU 0;
BA_ "GenSigTimeoutTime_RFHM" SG_ 2564440309 N_PDU 0;
BA_ "GenSigTimeoutTime_MPAD" SG_ 2564440309 N_PDU 0;
BA_ "GenSigTimeoutTime_IPC" SG_ 2564440309 N_PDU 0;
BA_ "GenSigTimeoutTime_GNMM" SG_ 2564440309 N_PDU 0;
BA_ "GenSigTimeoutTime_EVCU2" SG_ 2564440309 N_PDU 0;
BA_ "GenSigTimeoutTime_ESL" SG_ 2564440309 N_PDU 0;
BA_ "GenSigTimeoutTime_ECM" SG_ 2564440309 N_PDU 0;
BA_ "GenSigTimeoutTime_DTCM" SG_ 2564440309 N_PDU 0;
BA_ "GenSigTimeoutTime_DMSM" SG_ 2564440309 N_PDU 0;
BA_ "GenSigTimeoutTime_BSM" SG_ 2564440309 N_PDU 0;
BA_ "GenSigTimeoutTime_BCM" SG_ 2564440309 N_PDU 0;
BA_ "GenSigTimeoutTime_AGSM" SG_ 2564440309 N_PDU 0;
BA_ "GenSigTimeoutTime_ADCAM" SG_ 2564440309 N_PDU 0;
BA_ "GenSigTimeoutTime_ECM" SG_ 2654339108 WakeupSource_FD08_ETM 0;
BA_ "GenSigTimeoutTime_DTCM" SG_ 2654339108 WakeupSource_FD08_ETM 0;
BA_ "GenSigTimeoutTime_DMSM" SG_ 2654339108 WakeupSource_FD08_ETM 0;
BA_ "GenSigTimeoutTime_BSM" SG_ 2654339108 WakeupSource_FD08_ETM 0;
BA_ "GenSigTimeoutTime_BCM" SG_ 2654339108 WakeupSource_FD08_ETM 0;
BA_ "GenSigTimeoutTime_AGSM" SG_ 2654339108 WakeupSource_FD08_ETM 0;
BA_ "GenSigTimeoutTime_ADCAM" SG_ 2654339108 WakeupSource_FD08_ETM 0;
BA_ "GenSigTimeoutTime_SGW" SG_ 2654339108 StayActiveSource_FD08_ETM 0;
BA_ "GenSigTimeoutTime_RFHM" SG_ 2654339108 StayActiveSource_FD08_ETM 0;
BA_ "GenSigTimeoutTime_MPAD" SG_ 2654339108 StayActiveSource_FD08_ETM 0;
BA_ "GenSigTimeoutTime_IPC" SG_ 2654339108 StayActiveSource_FD08_ETM 0;
BA_ "GenSigTimeoutTime_GNMM" SG_ 2654339108 StayActiveSource_FD08_ETM 0;
BA_ "GenSigTimeoutTime_EVCU2" SG_ 2654339108 StayActiveSource_FD08_ETM 0;
BA_ "GenSigTimeoutTime_ESL" SG_ 2654339108 StayActiveSource_FD08_ETM 0;
BA_ "GenSigTimeoutTime_ECM" SG_ 2654339108 StayActiveSource_FD08_ETM 0;
BA_ "GenSigTimeoutTime_DTCM" SG_ 2654339108 StayActiveSource_FD08_ETM 0;
BA_ "GenSigTimeoutTime_DMSM" SG_ 2654339108 StayActiveSource_FD08_ETM 0;
BA_ "GenSigTimeoutTime_BSM" SG_ 2654339108 StayActiveSource_FD08_ETM 0;
BA_ "GenSigTimeoutTime_BCM" SG_ 2654339108 StayActiveSource_FD08_ETM 0;
BA_ "GenSigTimeoutTime_AGSM" SG_ 2654339108 StayActiveSource_FD08_ETM 0;
BA_ "GenSigTimeoutTime_ADCAM" SG_ 2654339108 StayActiveSource_FD08_ETM 0;
BA_ "GenSigTimeoutTime_IPC" SG_ 2654486672 CBV_bit6_PartialNtwInfBit 0;
BA_ "GenSigTimeoutTime_GNMM" SG_ 2654486672 CBV_bit6_PartialNtwInfBit 0;
BA_ "GenSigTimeoutTime_EVCU2" SG_ 2654486672 CBV_bit6_PartialNtwInfBit 0;
BA_ "GenSigTimeoutTime_ESL" SG_ 2654486672 CBV_bit6_PartialNtwInfBit 0;
BA_ "GenSigTimeoutTime_ECM" SG_ 2654486672 CBV_bit6_PartialNtwInfBit 0;
BA_ "GenSigTimeoutTime_DTCM" SG_ 2654486672 CBV_bit6_PartialNtwInfBit 0;
BA_ "GenSigTimeoutTime_DMSM" SG_ 2654486672 CBV_bit6_PartialNtwInfBit 0;
BA_ "GenSigTimeoutTime_BSM" SG_ 2654486672 CBV_bit6_PartialNtwInfBit 0;
BA_ "GenSigTimeoutTime_BCM" SG_ 2654486672 CBV_bit6_PartialNtwInfBit 0;
BA_ "GenSigTimeoutTime_AGSM" SG_ 2654486672 CBV_bit6_PartialNtwInfBit 0;
BA_ "GenSigTimeoutTime_ADCAM" SG_ 2654486672 CBV_bit6_PartialNtwInfBit 0;
BA_ "GenSigTimeoutTime_SGW" SG_ 2654486672 CBV_bit5 0;
BA_ "GenSigTimeoutTime_RFHM" SG_ 2654486672 CBV_bit5 0;
BA_ "GenSigTimeoutTime_MPAD" SG_ 2654486672 CBV_bit5 0;
BA_ "GenSigTimeoutTime_IPC" SG_ 2654486672 CBV_bit5 0;
BA_ "GenSigTimeoutTime_GNMM" SG_ 2654486672 CBV_bit5 0;
BA_ "GenSigTimeoutTime_EVCU2" SG_ 2654486672 CBV_bit5 0;
BA_ "GenSigTimeoutTime_ESL" SG_ 2654486672 CBV_bit5 0;
BA_ "GenSigTimeoutTime_ECM" SG_ 2654486672 CBV_bit5 0;
BA_ "GenSigTimeoutTime_DTCM" SG_ 2654486672 CBV_bit5 0;
BA_ "GenSigTimeoutTime_DMSM" SG_ 2654486672 CBV_bit5 0;
BA_ "GenSigTimeoutTime_BSM" SG_ 2654486672 CBV_bit5 0;
BA_ "GenSigTimeoutTime_BCM" SG_ 2654486672 CBV_bit5 0;
BA_ "GenSigTimeoutTime_AGSM" SG_ 2654486672 CBV_bit5 0;
BA_ "GenSigTimeoutTime_ADCAM" SG_ 2654486672 CBV_bit5 0;
BA_ "GenSigTimeoutTime_SGW" SG_ 2654486672 CBV_bit4_ActiveWakeupBit 0;
BA_ "GenSigTimeoutTime_RFHM" SG_ 2654486672 CBV_bit4_ActiveWakeupBit 0;
BA_ "GenSigTimeoutTime_MPAD" SG_ 2654486672 CBV_bit4_ActiveWakeupBit 0;
BA_ "GenSigTimeoutTime_IPC" SG_ 2654486672 CBV_bit4_ActiveWakeupBit 0;
BA_ "GenSigTimeoutTime_GNMM" SG_ 2654486672 CBV_bit4_ActiveWakeupBit 0;
BA_ "GenSigTimeoutTime_EVCU2" SG_ 2654486672 CBV_bit4_ActiveWakeupBit 0;
BA_ "GenSigTimeoutTime_ESL" SG_ 2654486672 CBV_bit4_ActiveWakeupBit 0;
BA_ "GenSigTimeoutTime_ECM" SG_ 2654486672 CBV_bit4_ActiveWakeupBit 0;
BA_ "GenSigTimeoutTime_DTCM" SG_ 2654486672 CBV_bit4_ActiveWakeupBit 0;
BA_ "GenSigTimeoutTime_DMSM" SG_ 2654486672 CBV_bit4_ActiveWakeupBit 0;
BA_ "GenSigTimeoutTime_BSM" SG_ 2654486672 CBV_bit4_ActiveWakeupBit 0;
BA_ "GenSigTimeoutTime_BCM" SG_ 2654486672 CBV_bit4_ActiveWakeupBit 0;
BA_ "GenSigTimeoutTime_AGSM" SG_ 2654486672 CBV_bit4_ActiveWakeupBit 0;
BA_ "GenSigTimeoutTime_ADCAM" SG_ 2654486672 CBV_bit4_ActiveWakeupBit 0;
BA_ "GenSigTimeoutTime_SGW" SG_ 2654486672 CBV_bit3_NMCoordinatorBit 0;
BA_ "GenSigTimeoutTime_RFHM" SG_ 2654486672 CBV_bit3_NMCoordinatorBit 0;
BA_ "GenSigTimeoutTime_MPAD" SG_ 2654486672 CBV_bit3_NMCoordinatorBit 0;
BA_ "GenSigTimeoutTime_IPC" SG_ 2654486672 CBV_bit3_NMCoordinatorBit 0;
BA_ "GenSigTimeoutTime_GNMM" SG_ 2654486672 CBV_bit3_NMCoordinatorBit 0;
BA_ "GenSigTimeoutTime_EVCU2" SG_ 2654486672 CBV_bit3_NMCoordinatorBit 0;
BA_ "GenSigTimeoutTime_ESL" SG_ 2654486672 CBV_bit3_NMCoordinatorBit 0;
BA_ "GenSigTimeoutTime_ECM" SG_ 2654486672 CBV_bit3_NMCoordinatorBit 0;
BA_ "GenSigTimeoutTime_DTCM" SG_ 2654486672 CBV_bit3_NMCoordinatorBit 0;
BA_ "GenSigTimeoutTime_DMSM" SG_ 2654486672 CBV_bit3_NMCoordinatorBit 0;
BA_ "GenSigTimeoutTime_BSM" SG_ 2654486672 CBV_bit3_NMCoordinatorBit 0;
BA_ "GenSigTimeoutTime_BCM" SG_ 2654486672 CBV_bit3_NMCoordinatorBit 0;
BA_ "GenSigTimeoutTime_AGSM" SG_ 2654486672 CBV_bit3_NMCoordinatorBit 0;
BA_ "GenSigTimeoutTime_ADCAM" SG_ 2654486672 CBV_bit3_NMCoordinatorBit 0;
BA_ "GenSigTimeoutTime_SGW" SG_ 2654486672 CBV_bit2 0;
BA_ "GenSigTimeoutTime_RFHM" SG_ 2654486672 CBV_bit2 0;
BA_ "GenSigTimeoutTime_MPAD" SG_ 2654486672 CBV_bit2 0;
BA_ "GenSigTimeoutTime_IPC" SG_ 2654486672 CBV_bit2 0;
BA_ "GenSigTimeoutTime_GNMM" SG_ 2654486672 CBV_bit2 0;
BA_ "GenSigTimeoutTime_EVCU2" SG_ 2654486672 CBV_bit2 0;
BA_ "GenSigTimeoutTime_ESL" SG_ 2654486672 CBV_bit2 0;
BA_ "GenSigTimeoutTime_ECM" SG_ 2654486672 CBV_bit2 0;
BA_ "GenSigTimeoutTime_DTCM" SG_ 2654486672 CBV_bit2 0;
BA_ "GenSigTimeoutTime_DMSM" SG_ 2654486672 CBV_bit2 0;
BA_ "GenSigTimeoutTime_BSM" SG_ 2654486672 CBV_bit2 0;
BA_ "GenSigTimeoutTime_BCM" SG_ 2654486672 CBV_bit2 0;
BA_ "GenSigTimeoutTime_AGSM" SG_ 2654486672 CBV_bit2 0;
BA_ "GenSigTimeoutTime_ADCAM" SG_ 2654486672 CBV_bit2 0;
BA_ "GenSigTimeoutTime_SGW" SG_ 2654339199 GenericFailSts_FD08_VRM 0;
BA_ "GenSigTimeoutTime_RFHM" SG_ 2654339199 GenericFailSts_FD08_VRM 0;
BA_ "GenSigTimeoutTime_MPAD" SG_ 2654339199 GenericFailSts_FD08_VRM 0;
BA_ "GenSigTimeoutTime_IPC" SG_ 2654339199 GenericFailSts_FD08_VRM 0;
BA_ "GenSigTimeoutTime_GNMM" SG_ 2654339199 GenericFailSts_FD08_VRM 0;
BA_ "GenSigTimeoutTime_EVCU2" SG_ 2654339199 GenericFailSts_FD08_VRM 0;
BA_ "GenSigTimeoutTime_ESL" SG_ 2654339199 GenericFailSts_FD08_VRM 0;
BA_ "GenSigTimeoutTime_ECM" SG_ 2654339199 GenericFailSts_FD08_VRM 0;
BA_ "GenSigTimeoutTime_DTCM" SG_ 2654339199 GenericFailSts_FD08_VRM 0;
BA_ "GenSigTimeoutTime_DMSM" SG_ 2654339199 GenericFailSts_FD08_VRM 0;
BA_ "GenSigTimeoutTime_BSM" SG_ 2654339199 GenericFailSts_FD08_VRM 0;
BA_ "GenSigTimeoutTime_BCM" SG_ 2654339199 GenericFailSts_FD08_VRM 0;
BA_ "GenSigTimeoutTime_AGSM" SG_ 2654339199 GenericFailSts_FD08_VRM 0;
BA_ "GenSigTimeoutTime_ADCAM" SG_ 2654339199 GenericFailSts_FD08_VRM 0;
BA_ "GenSigTimeoutTime_SGW" SG_ 2654339199 EOL_FD08_VRM 0;
BA_ "GenSigTimeoutTime_RFHM" SG_ 2654339199 EOL_FD08_VRM 0;
BA_ "GenSigTimeoutTime_MPAD" SG_ 2654339199 EOL_FD08_VRM 0;
BA_ "GenSigTimeoutTime_IPC" SG_ 2654339199 EOL_FD08_VRM 0;
BA_ "GenSigTimeoutTime_GNMM" SG_ 2654339199 EOL_FD08_VRM 0;
BA_ "GenSigTimeoutTime_EVCU2" SG_ 2654339199 EOL_FD08_VRM 0;
BA_ "GenSigTimeoutTime_ESL" SG_ 2654339199 EOL_FD08_VRM 0;
BA_ "GenSigTimeoutTime_ECM" SG_ 2654339199 EOL_FD08_VRM 0;
BA_ "GenSigTimeoutTime_DTCM" SG_ 2654339199 EOL_FD08_VRM 0;
BA_ "GenSigTimeoutTime_DMSM" SG_ 2654339199 EOL_FD08_VRM 0;
BA_ "GenSigTimeoutTime_BSM" SG_ 2654339199 EOL_FD08_VRM 0;
BA_ "GenSigTimeoutTime_BCM" SG_ 2654339199 EOL_FD08_VRM 0;
BA_ "GenSigTimeoutTime_AGSM" SG_ 2654339199 EOL_FD08_VRM 0;
BA_ "GenSigTimeoutTime_ADCAM" SG_ 2654339199 EOL_FD08_VRM 0;
BA_ "GenSigTimeoutTime_SGW" SG_ 2654339199 CurrentFailSts_FD08_VRM 0;
BA_ "GenSigTimeoutTime_RFHM" SG_ 2654339199 CurrentFailSts_FD08_VRM 0;
BA_ "GenSigTimeoutTime_MPAD" SG_ 2654339199 CurrentFailSts_FD08_VRM 0;
BA_ "GenSigTimeoutTime_IPC" SG_ 2654339199 CurrentFailSts_FD08_VRM 0;
BA_ "GenSigTimeoutTime_GNMM" SG_ 2654339199 CurrentFailSts_FD08_VRM 0;
BA_ "GenSigTimeoutTime_EVCU2" SG_ 2654339199 CurrentFailSts_FD08_VRM 0;
BA_ "GenSigTimeoutTime_ESL" SG_ 2654339199 CurrentFailSts_FD08_VRM 0;
BA_ "GenSigTimeoutTime_ECM" SG_ 2654339199 CurrentFailSts_FD08_VRM 0;
BA_ "GenSigTimeoutTime_DTCM" SG_ 2654339199 CurrentFailSts_FD08_VRM 0;
BA_ "GenSigTimeoutTime_DMSM" SG_ 2654339199 CurrentFailSts_FD08_VRM 0;
BA_ "GenSigTimeoutTime_BSM" SG_ 2654339199 CurrentFailSts_FD08_VRM 0;
BA_ "GenSigTimeoutTime_BCM" SG_ 2654339199 CurrentFailSts_FD08_VRM 0;
BA_ "GenSigTimeoutTime_AGSM" SG_ 2654339199 CurrentFailSts_FD08_VRM 0;
BA_ "GenSigTimeoutTime_ADCAM" SG_ 2654339199 CurrentFailSts_FD08_VRM 0;
BA_ "GenSigTimeoutTime_SGW" SG_ 2654339107 GenericFailSts_FD08_TBM 0;
BA_ "GenSigTimeoutTime_RFHM" SG_ 2654339107 GenericFailSts_FD08_TBM 0;
BA_ "GenSigTimeoutTime_MPAD" SG_ 2654339107 GenericFailSts_FD08_TBM 0;
BA_ "GenSigTimeoutTime_IPC" SG_ 2654339107 GenericFailSts_FD08_TBM 0;
BA_ "GenSigTimeoutTime_GNMM" SG_ 2654339107 GenericFailSts_FD08_TBM 0;
BA_ "GenSigTimeoutTime_EVCU2" SG_ 2654339107 GenericFailSts_FD08_TBM 0;
BA_ "GenSigTimeoutTime_ESL" SG_ 2654339107 GenericFailSts_FD08_TBM 0;
BA_ "GenSigTimeoutTime_ECM" SG_ 2654339107 GenericFailSts_FD08_TBM 0;
BA_ "GenSigTimeoutTime_DTCM" SG_ 2654339107 GenericFailSts_FD08_TBM 0;
BA_ "GenSigTimeoutTime_DMSM" SG_ 2654339107 GenericFailSts_FD08_TBM 0;
BA_ "GenSigTimeoutTime_BSM" SG_ 2654339107 GenericFailSts_FD08_TBM 0;
BA_ "GenSigTimeoutTime_AGSM" SG_ 2654339107 GenericFailSts_FD08_TBM 0;
BA_ "GenSigTimeoutTime_ADCAM" SG_ 2654339107 GenericFailSts_FD08_TBM 0;
BA_ "GenSigTimeoutTime_SGW" SG_ 2654339107 EOL_FD08_TBM 0;
BA_ "GenSigTimeoutTime_RFHM" SG_ 2654339107 EOL_FD08_TBM 0;
BA_ "GenSigTimeoutTime_MPAD" SG_ 2654339107 EOL_FD08_TBM 0;
BA_ "GenSigTimeoutTime_IPC" SG_ 2654339107 EOL_FD08_TBM 0;
BA_ "GenSigTimeoutTime_GNMM" SG_ 2654339107 EOL_FD08_TBM 0;
BA_ "GenSigTimeoutTime_EVCU2" SG_ 2654339107 EOL_FD08_TBM 0;
BA_ "GenSigTimeoutTime_ESL" SG_ 2654339107 EOL_FD08_TBM 0;
BA_ "GenSigTimeoutTime_ECM" SG_ 2654339107 EOL_FD08_TBM 0;
BA_ "GenSigTimeoutTime_DTCM" SG_ 2654339107 EOL_FD08_TBM 0;
BA_ "GenSigTimeoutTime_DMSM" SG_ 2654339107 EOL_FD08_TBM 0;
BA_ "GenSigTimeoutTime_BSM" SG_ 2654339107 EOL_FD08_TBM 0;
BA_ "GenSigTimeoutTime_AGSM" SG_ 2654339107 EOL_FD08_TBM 0;
BA_ "GenSigTimeoutTime_ADCAM" SG_ 2654339107 EOL_FD08_TBM 0;
BA_ "GenSigTimeoutTime_SGW" SG_ 2654339107 CurrentFailSts_FD08_TBM 0;
BA_ "GenSigTimeoutTime_RFHM" SG_ 2654339107 CurrentFailSts_FD08_TBM 0;
BA_ "GenSigTimeoutTime_MPAD" SG_ 2654339107 CurrentFailSts_FD08_TBM 0;
BA_ "GenSigTimeoutTime_IPC" SG_ 2654339107 CurrentFailSts_FD08_TBM 0;
BA_ "GenSigTimeoutTime_GNMM" SG_ 2654339107 CurrentFailSts_FD08_TBM 0;
BA_ "GenSigTimeoutTime_EVCU2" SG_ 2654339107 CurrentFailSts_FD08_TBM 0;
BA_ "GenSigTimeoutTime_ESL" SG_ 2654339107 CurrentFailSts_FD08_TBM 0;
BA_ "GenSigTimeoutTime_ECM" SG_ 2654339107 CurrentFailSts_FD08_TBM 0;
BA_ "GenSigTimeoutTime_DTCM" SG_ 2654339107 CurrentFailSts_FD08_TBM 0;
BA_ "GenSigTimeoutTime_DMSM" SG_ 2654339107 CurrentFailSts_FD08_TBM 0;
BA_ "GenSigTimeoutTime_BSM" SG_ 2654339107 CurrentFailSts_FD08_TBM 0;
BA_ "GenSigTimeoutTime_AGSM" SG_ 2654339107 CurrentFailSts_FD08_TBM 0;
BA_ "GenSigTimeoutTime_ADCAM" SG_ 2654339107 CurrentFailSts_FD08_TBM 0;
BA_ "GenSigTimeoutTime_SGW" SG_ 1438 DM_Eyes_Tracked 0;
BA_ "GenSigTimeoutTime_RFHM" SG_ 1438 DM_Eyes_Tracked 0;
BA_ "GenSigTimeoutTime_IPC" SG_ 1438 DM_Eyes_Tracked 0;
BA_ "GenSigTimeoutTime_GNMM" SG_ 1438 DM_Eyes_Tracked 0;
BA_ "GenSigTimeoutTime_EVCU2" SG_ 1438 DM_Eyes_Tracked 0;
BA_ "GenSigTimeoutTime_ESL" SG_ 1438 DM_Eyes_Tracked 0;
BA_ "GenSigTimeoutTime_ECM" SG_ 1438 DM_Eyes_Tracked 0;
BA_ "GenSigTimeoutTime_DTCM" SG_ 1438 DM_Eyes_Tracked 0;
BA_ "GenSigTimeoutTime_DMSM" SG_ 1438 DM_Eyes_Tracked 0;
BA_ "GenSigTimeoutTime_BSM" SG_ 1438 DM_Eyes_Tracked 0;
BA_ "GenSigTimeoutTime_AGSM" SG_ 1438 DM_Eyes_Tracked 0;
BA_ "GenSigTimeoutTime_ADCAM" SG_ 1438 DM_Eyes_Tracked 0;
BA_ "GenSigSendType" SG_ 1438 DM_Eyes_Tracked 3;
BA_ "GenSigTimeoutTime_BSM" SG_ 1438 DM_Zone_Track 0;
BA_ "GenSigTimeoutTime_AGSM" SG_ 1438 DM_Zone_Track 0;
BA_ "GenSigTimeoutTime_ADCAM" SG_ 1438 DM_Zone_Track 0;
BA_ "GenSigSendType" SG_ 1438 DM_Zone_Track 3;
BA_ "GenSigTimeoutTime_RFHM" SG_ 1438 DM_Distract_State 0;
BA_ "GenSigTimeoutTime_IPC" SG_ 1438 DM_Distract_State 0;
BA_ "GenSigTimeoutTime_GNMM" SG_ 1438 DM_Distract_State 0;
BA_ "GenSigTimeoutTime_EVCU2" SG_ 1438 DM_Distract_State 0;
BA_ "GenSigTimeoutTime_ESL" SG_ 1438 DM_Distract_State 0;
BA_ "GenSigTimeoutTime_ECM" SG_ 1438 DM_Distract_State 0;
BA_ "GenSigTimeoutTime_DTCM" SG_ 1438 DM_Distract_State 0;
BA_ "GenSigTimeoutTime_DMSM" SG_ 1438 DM_Distract_State 0;
BA_ "GenSigTimeoutTime_BSM" SG_ 1438 DM_Distract_State 0;
BA_ "GenSigTimeoutTime_AGSM" SG_ 1438 DM_Distract_State 0;
BA_ "GenSigTimeoutTime_ADCAM" SG_ 1438 DM_Distract_State 0;
BA_ "GenSigSendType" SG_ 1438 DM_Distract_State 3;
BA_ "GenSigTimeoutTime_SGW" SG_ 1438 DM_Distract_Instant 0;
BA_ "GenSigTimeoutTime_RFHM" SG_ 1438 DM_Distract_Instant 0;
BA_ "GenSigTimeoutTime_IPC" SG_ 1438 DM_Distract_Instant 0;
BA_ "GenSigTimeoutTime_GNMM" SG_ 1438 DM_Distract_Instant 0;
BA_ "GenSigTimeoutTime_EVCU2" SG_ 1438 DM_Distract_Instant 0;
BA_ "GenSigTimeoutTime_ESL" SG_ 1438 DM_Distract_Instant 0;
BA_ "GenSigTimeoutTime_ECM" SG_ 1438 DM_Distract_Instant 0;
BA_ "GenSigTimeoutTime_DTCM" SG_ 1438 DM_Distract_Instant 0;
BA_ "GenSigTimeoutTime_DMSM" SG_ 1438 DM_Distract_Instant 0;
BA_ "GenSigTimeoutTime_BSM" SG_ 1438 DM_Distract_Instant 0;
BA_ "GenSigTimeoutTime_AGSM" SG_ 1438 DM_Distract_Instant 0;
BA_ "GenSigTimeoutTime_ADCAM" SG_ 1438 DM_Distract_Instant 0;
BA_ "GenSigTimeoutTime_SGW" SG_ 1438 DM_Distract_Conf 0;
BA_ "GenSigTimeoutTime_RFHM" SG_ 1438 DM_Distract_Conf 0;
BA_ "GenSigTimeoutTime_IPC" SG_ 1438 DM_Distract_Conf 0;
BA_ "GenSigTimeoutTime_GNMM" SG_ 1438 DM_Distract_Conf 0;
BA_ "GenSigTimeoutTime_EVCU2" SG_ 1438 DM_Distract_Conf 0;
BA_ "GenSigTimeoutTime_ESL" SG_ 1438 DM_Distract_Conf 0;
BA_ "GenSigTimeoutTime_ECM" SG_ 1438 DM_Distract_Conf 0;
BA_ "GenSigTimeoutTime_DTCM" SG_ 1438 DM_Distract_Conf 0;
BA_ "GenSigTimeoutTime_DMSM" SG_ 1438 DM_Distract_Conf 0;
BA_ "GenSigTimeoutTime_BSM" SG_ 1438 DM_Distract_Conf 0;
BA_ "GenSigTimeoutTime_AGSM" SG_ 1438 DM_Distract_Conf 0;
BA_ "GenSigTimeoutTime_ADCAM" SG_ 1438 DM_Distract_Conf 0;
BA_ "GenSigSendType" SG_ 1438 DM_Distract_Conf 3;
BA_ "GenSigTimeoutTime_SGW" SG_ 1438 DM_Camera_Blind 0;
BA_ "GenSigTimeoutTime_RFHM" SG_ 1438 DM_Camera_Blind 0;
BA_ "GenSigTimeoutTime_IPC" SG_ 1438 DM_Camera_Blind 0;
BA_ "GenSigTimeoutTime_GNMM" SG_ 1438 DM_Camera_Blind 0;
BA_ "GenSigTimeoutTime_EVCU2" SG_ 1438 DM_Camera_Blind 0;
BA_ "GenSigTimeoutTime_ESL" SG_ 1438 DM_Camera_Blind 0;
BA_ "GenSigTimeoutTime_ECM" SG_ 1438 DM_Camera_Blind 0;
BA_ "GenSigTimeoutTime_DTCM" SG_ 1438 DM_Camera_Blind 0;
BA_ "GenSigTimeoutTime_DMSM" SG_ 1438 DM_Camera_Blind 0;
BA_ "GenSigTimeoutTime_BSM" SG_ 1438 DM_Camera_Blind 0;
BA_ "GenSigTimeoutTime_AGSM" SG_ 1438 DM_Camera_Blind 0;
BA_ "GenSigTimeoutTime_ADCAM" SG_ 1438 DM_Camera_Blind 0;
BA_ "GenSigSendType" SG_ 1438 DM_Camera_Blind 3;
BA_ "GenSigTimeoutTime_RFHM" SG_ 1438 DM_Drowsy_State 0;
BA_ "GenSigTimeoutTime_IPC" SG_ 1438 DM_Drowsy_State 0;
BA_ "GenSigTimeoutTime_GNMM" SG_ 1438 DM_Drowsy_State 0;
BA_ "GenSigTimeoutTime_EVCU2" SG_ 1438 DM_Drowsy_State 0;
BA_ "GenSigTimeoutTime_ESL" SG_ 1438 DM_Drowsy_State 0;
BA_ "GenSigTimeoutTime_ECM" SG_ 1438 DM_Drowsy_State 0;
BA_ "GenSigTimeoutTime_DTCM" SG_ 1438 DM_Drowsy_State 0;
BA_ "GenSigTimeoutTime_DMSM" SG_ 1438 DM_Drowsy_State 0;
BA_ "GenSigTimeoutTime_BSM" SG_ 1438 DM_Drowsy_State 0;
BA_ "GenSigTimeoutTime_AGSM" SG_ 1438 DM_Drowsy_State 0;
BA_ "GenSigTimeoutTime_ADCAM" SG_ 1438 DM_Drowsy_State 0;
BA_ "GenSigSendType" SG_ 1438 DM_Drowsy_State 3;
BA_ "GenSigTimeoutTime_SGW" SG_ 1438 DM_Drowsy_Micro 0;
BA_ "GenSigTimeoutTime_RFHM" SG_ 1438 DM_Drowsy_Micro 0;
BA_ "GenSigTimeoutTime_IPC" SG_ 1438 DM_Drowsy_Micro 0;
BA_ "GenSigTimeoutTime_GNMM" SG_ 1438 DM_Drowsy_Micro 0;
BA_ "GenSigTimeoutTime_EVCU2" SG_ 1438 DM_Drowsy_Micro 0;
BA_ "GenSigTimeoutTime_ESL" SG_ 1438 DM_Drowsy_Micro 0;
BA_ "GenSigTimeoutTime_ECM" SG_ 1438 DM_Drowsy_Micro 0;
BA_ "GenSigTimeoutTime_DTCM" SG_ 1438 DM_Drowsy_Micro 0;
BA_ "GenSigTimeoutTime_DMSM" SG_ 1438 DM_Drowsy_Micro 0;
BA_ "GenSigTimeoutTime_BSM" SG_ 1438 DM_Drowsy_Micro 0;
BA_ "GenSigTimeoutTime_AGSM" SG_ 1438 DM_Drowsy_Micro 0;
BA_ "GenSigTimeoutTime_ADCAM" SG_ 1438 DM_Drowsy_Micro 0;
BA_ "GenSigSendType" SG_ 1438 DM_Drowsy_Micro 3;
BA_ "GenSigTimeoutTime_SGW" SG_ 1438 DM_Drowsy_Conf 0;
BA_ "GenSigTimeoutTime_RFHM" SG_ 1438 DM_Drowsy_Conf 0;
BA_ "GenSigTimeoutTime_IPC" SG_ 1438 DM_Drowsy_Conf 0;
BA_ "GenSigTimeoutTime_GNMM" SG_ 1438 DM_Drowsy_Conf 0;
BA_ "GenSigTimeoutTime_EVCU2" SG_ 1438 DM_Drowsy_Conf 0;
BA_ "GenSigTimeoutTime_ESL" SG_ 1438 DM_Drowsy_Conf 0;
BA_ "GenSigTimeoutTime_ECM" SG_ 1438 DM_Drowsy_Conf 0;
BA_ "GenSigTimeoutTime_DTCM" SG_ 1438 DM_Drowsy_Conf 0;
BA_ "GenSigTimeoutTime_DMSM" SG_ 1438 DM_Drowsy_Conf 0;
BA_ "GenSigTimeoutTime_BSM" SG_ 1438 DM_Drowsy_Conf 0;
BA_ "GenSigTimeoutTime_AGSM" SG_ 1438 DM_Drowsy_Conf 0;
BA_ "GenSigTimeoutTime_ADCAM" SG_ 1438 DM_Drowsy_Conf 0;
BA_ "GenSigSendType" SG_ 1438 DM_Drowsy_Conf 3;
BA_ "GenSigTimeoutTime_SGW" SG_ 1438 DM_Drowsy_Instant 0;
BA_ "GenSigTimeoutTime_RFHM" SG_ 1438 DM_Drowsy_Instant 0;
BA_ "GenSigTimeoutTime_IPC" SG_ 1438 DM_Drowsy_Instant 0;
BA_ "GenSigTimeoutTime_GNMM" SG_ 1438 DM_Drowsy_Instant 0;
BA_ "GenSigTimeoutTime_EVCU2" SG_ 1438 DM_Drowsy_Instant 0;
BA_ "GenSigTimeoutTime_ESL" SG_ 1438 DM_Drowsy_Instant 0;
BA_ "GenSigTimeoutTime_ECM" SG_ 1438 DM_Drowsy_Instant 0;
BA_ "GenSigTimeoutTime_DTCM" SG_ 1438 DM_Drowsy_Instant 0;
BA_ "GenSigTimeoutTime_DMSM" SG_ 1438 DM_Drowsy_Instant 0;
BA_ "GenSigTimeoutTime_BSM" SG_ 1438 DM_Drowsy_Instant 0;
BA_ "GenSigTimeoutTime_AGSM" SG_ 1438 DM_Drowsy_Instant 0;
BA_ "GenSigTimeoutTime_ADCAM" SG_ 1438 DM_Drowsy_Instant 0;
BA_ "GenSigTimeoutTime_SGW" SG_ 1438 CRC_DRV_MONITOR1 0;
BA_ "GenSigTimeoutTime_RFHM" SG_ 1438 CRC_DRV_MONITOR1 0;
BA_ "GenSigTimeoutTime_IPC" SG_ 1438 CRC_DRV_MONITOR1 0;
BA_ "GenSigTimeoutTime_GNMM" SG_ 1438 CRC_DRV_MONITOR1 0;
BA_ "GenSigTimeoutTime_EVCU2" SG_ 1438 CRC_DRV_MONITOR1 0;
BA_ "GenSigTimeoutTime_ESL" SG_ 1438 CRC_DRV_MONITOR1 0;
BA_ "GenSigTimeoutTime_ECM" SG_ 1438 CRC_DRV_MONITOR1 0;
BA_ "GenSigTimeoutTime_DTCM" SG_ 1438 CRC_DRV_MONITOR1 0;
BA_ "GenSigTimeoutTime_DMSM" SG_ 1438 CRC_DRV_MONITOR1 0;
BA_ "GenSigTimeoutTime_BSM" SG_ 1438 CRC_DRV_MONITOR1 0;
BA_ "GenSigTimeoutTime_AGSM" SG_ 1438 CRC_DRV_MONITOR1 0;
BA_ "GenSigTimeoutTime_SGW" SG_ 2654339172 GenericFailSts_FD08_DTV 0;
BA_ "GenSigTimeoutTime_RFHM" SG_ 2654339172 GenericFailSts_FD08_DTV 0;
BA_ "GenSigTimeoutTime_MPAD" SG_ 2654339172 GenericFailSts_FD08_DTV 0;
BA_ "GenSigTimeoutTime_IPC" SG_ 2654339172 GenericFailSts_FD08_DTV 0;
BA_ "GenSigTimeoutTime_GNMM" SG_ 2654339172 GenericFailSts_FD08_DTV 0;
BA_ "GenSigTimeoutTime_EVCU2" SG_ 2654339172 GenericFailSts_FD08_DTV 0;
BA_ "GenSigTimeoutTime_ESL" SG_ 2654339172 GenericFailSts_FD08_DTV 0;
BA_ "GenSigTimeoutTime_ECM" SG_ 2654339172 GenericFailSts_FD08_DTV 0;
BA_ "GenSigTimeoutTime_DTCM" SG_ 2654339172 GenericFailSts_FD08_DTV 0;
BA_ "GenSigTimeoutTime_DMSM" SG_ 2654339172 GenericFailSts_FD08_DTV 0;
BA_ "GenSigTimeoutTime_BSM" SG_ 2654339172 GenericFailSts_FD08_DTV 0;
BA_ "GenSigTimeoutTime_AGSM" SG_ 2654339172 GenericFailSts_FD08_DTV 0;
BA_ "GenSigTimeoutTime_ADCAM" SG_ 2654339172 GenericFailSts_FD08_DTV 0;
BA_ "GenSigTimeoutTime_SGW" SG_ 2654339172 EOL_FD08_DTV 0;
BA_ "GenSigTimeoutTime_RFHM" SG_ 2654339172 EOL_FD08_DTV 0;
BA_ "GenSigTimeoutTime_MPAD" SG_ 2654339172 EOL_FD08_DTV 0;
BA_ "GenSigTimeoutTime_IPC" SG_ 2654339172 EOL_FD08_DTV 0;
BA_ "GenSigTimeoutTime_GNMM" SG_ 2654339172 EOL_FD08_DTV 0;
BA_ "GenSigTimeoutTime_EVCU2" SG_ 2654339172 EOL_FD08_DTV 0;
BA_ "GenSigTimeoutTime_ESL" SG_ 2654339172 EOL_FD08_DTV 0;
BA_ "GenSigTimeoutTime_ECM" SG_ 2654339172 EOL_FD08_DTV 0;
BA_ "GenSigTimeoutTime_DTCM" SG_ 2654339172 EOL_FD08_DTV 0;
BA_ "GenSigTimeoutTime_DMSM" SG_ 2654339172 EOL_FD08_DTV 0;
BA_ "GenSigTimeoutTime_BSM" SG_ 2654339172 EOL_FD08_DTV 0;
BA_ "GenSigTimeoutTime_AGSM" SG_ 2654339172 EOL_FD08_DTV 0;
BA_ "GenSigTimeoutTime_ADCAM" SG_ 2654339172 EOL_FD08_DTV 0;
BA_ "GenSigTimeoutTime_DTCM" SG_ 2654339172 CurrentFailSts_FD08_DTV 0;
BA_ "GenSigTimeoutTime_DMSM" SG_ 2654339172 CurrentFailSts_FD08_DTV 0;
BA_ "GenSigTimeoutTime_BSM" SG_ 2654339172 CurrentFailSts_FD08_DTV 0;
BA_ "GenSigTimeoutTime_AGSM" SG_ 2654339172 CurrentFailSts_FD08_DTV 0;
BA_ "GenSigTimeoutTime_ADCAM" SG_ 2654339172 CurrentFailSts_FD08_DTV 0;
BA_ "GenSigTimeoutTime_SGW" SG_ 2654339172 CurrentFailSts_FD08_DTV 0;
BA_ "GenSigTimeoutTime_RFHM" SG_ 2654339172 CurrentFailSts_FD08_DTV 0;
BA_ "GenSigTimeoutTime_MPAD" SG_ 2654339172 CurrentFailSts_FD08_DTV 0;
BA_ "GenSigTimeoutTime_IPC" SG_ 2654339172 CurrentFailSts_FD08_DTV 0;
BA_ "GenSigTimeoutTime_GNMM" SG_ 2654339172 CurrentFailSts_FD08_DTV 0;
BA_ "GenSigTimeoutTime_EVCU2" SG_ 2654339172 CurrentFailSts_FD08_DTV 0;
BA_ "GenSigTimeoutTime_ESL" SG_ 2654339172 CurrentFailSts_FD08_DTV 0;
BA_ "GenSigTimeoutTime_ECM" SG_ 2654339172 CurrentFailSts_FD08_DTV 0;
BA_ "GenSigTimeoutTime_SGW" SG_ 2654339108 GenericFailSts_FD08_ETM 0;
BA_ "GenSigTimeoutTime_RFHM" SG_ 2654339108 GenericFailSts_FD08_ETM 0;
BA_ "GenSigTimeoutTime_MPAD" SG_ 2654339108 GenericFailSts_FD08_ETM 0;
BA_ "GenSigTimeoutTime_IPC" SG_ 2654339108 GenericFailSts_FD08_ETM 0;
BA_ "GenSigTimeoutTime_GNMM" SG_ 2654339108 GenericFailSts_FD08_ETM 0;
BA_ "GenSigTimeoutTime_EVCU2" SG_ 2654339108 GenericFailSts_FD08_ETM 0;
BA_ "GenSigTimeoutTime_ESL" SG_ 2654339108 GenericFailSts_FD08_ETM 0;
BA_ "GenSigTimeoutTime_ECM" SG_ 2654339108 GenericFailSts_FD08_ETM 0;
BA_ "GenSigTimeoutTime_DTCM" SG_ 2654339108 GenericFailSts_FD08_ETM 0;
BA_ "GenSigTimeoutTime_DMSM" SG_ 2654339108 GenericFailSts_FD08_ETM 0;
BA_ "GenSigTimeoutTime_BSM" SG_ 2654339108 GenericFailSts_FD08_ETM 0;
BA_ "GenSigTimeoutTime_AGSM" SG_ 2654339108 GenericFailSts_FD08_ETM 0;
BA_ "GenSigTimeoutTime_ADCAM" SG_ 2654339108 GenericFailSts_FD08_ETM 0;
BA_ "GenSigTimeoutTime_SGW" SG_ 2654339108 EOL_FD08_ETM 0;
BA_ "GenSigTimeoutTime_RFHM" SG_ 2654339108 EOL_FD08_ETM 0;
BA_ "GenSigTimeoutTime_MPAD" SG_ 2654339108 EOL_FD08_ETM 0;
BA_ "GenSigTimeoutTime_IPC" SG_ 2654339108 EOL_FD08_ETM 0;
BA_ "GenSigTimeoutTime_GNMM" SG_ 2654339108 EOL_FD08_ETM 0;
BA_ "GenSigTimeoutTime_EVCU2" SG_ 2654339108 EOL_FD08_ETM 0;
BA_ "GenSigTimeoutTime_ESL" SG_ 2654339108 EOL_FD08_ETM 0;
BA_ "GenSigTimeoutTime_ECM" SG_ 2654339108 EOL_FD08_ETM 0;
BA_ "GenSigTimeoutTime_DTCM" SG_ 2654339108 EOL_FD08_ETM 0;
BA_ "GenSigTimeoutTime_ECM" SG_ 2654339075 CurrentFailSts_FD03_IPC 0;
BA_ "GenSigTimeoutTime_SGW" SG_ 2564462577 N_PDU 0;
BA_ "GenSigTimeoutTime_RFHM" SG_ 2564462577 N_PDU 0;
BA_ "GenSigTimeoutTime_MPAD" SG_ 2564462577 N_PDU 0;
BA_ "GenSigTimeoutTime_IPC" SG_ 2564462577 N_PDU 0;
BA_ "GenSigTimeoutTime_GNMM" SG_ 2564462577 N_PDU 0;
BA_ "GenSigTimeoutTime_EVCU2" SG_ 2564462577 N_PDU 0;
BA_ "GenSigTimeoutTime_ESL" SG_ 2564462577 N_PDU 0;
BA_ "GenSigTimeoutTime_ECM" SG_ 2564462577 N_PDU 0;
BA_ "GenSigTimeoutTime_DTCM" SG_ 2564462577 N_PDU 0;
BA_ "GenSigTimeoutTime_DMSM" SG_ 2564462577 N_PDU 0;
BA_ "GenSigTimeoutTime_BSM" SG_ 2564462577 N_PDU 0;
BA_ "GenSigTimeoutTime_BCM" SG_ 2564462577 N_PDU 0;
BA_ "GenSigTimeoutTime_AGSM" SG_ 2564462577 N_PDU 0;
BA_ "GenSigTimeoutTime_ADCAM" SG_ 2564462577 N_PDU 0;
BA_ "GenSigTimeoutTime_SGW" SG_ 2564462578 N_PDU 0;
BA_ "GenSigTimeoutTime_RFHM" SG_ 2564462578 N_PDU 0;
BA_ "GenSigTimeoutTime_MPAD" SG_ 2564462578 N_PDU 0;
BA_ "GenSigTimeoutTime_IPC" SG_ 2564462578 N_PDU 0;
BA_ "GenSigTimeoutTime_GNMM" SG_ 2564462578 N_PDU 0;
BA_ "GenSigTimeoutTime_EVCU2" SG_ 2564462578 N_PDU 0;
BA_ "GenSigTimeoutTime_ESL" SG_ 2564462578 N_PDU 0;
BA_ "GenSigTimeoutTime_ECM" SG_ 2564462578 N_PDU 0;
BA_ "GenSigTimeoutTime_DTCM" SG_ 2564462578 N_PDU 0;
BA_ "GenSigTimeoutTime_DMSM" SG_ 2564462578 N_PDU 0;
BA_ "GenSigTimeoutTime_BSM" SG_ 2564462578 N_PDU 0;
BA_ "GenSigTimeoutTime_BCM" SG_ 2564462578 N_PDU 0;
BA_ "GenSigTimeoutTime_AGSM" SG_ 2564462578 N_PDU 0;
BA_ "GenSigTimeoutTime_ADCAM" SG_ 2564462578 N_PDU 0;
BA_ "GenSigTimeoutTime_SGW" SG_ 2651930776 Digit_05_DMSM 0;
BA_ "GenSigTimeoutTime_RFHM" SG_ 2651930776 Digit_05_DMSM 0;
BA_ "GenSigTimeoutTime_MPAD" SG_ 2651930776 Digit_05_DMSM 0;
BA_ "GenSigTimeoutTime_IPC" SG_ 2651930776 Digit_05_DMSM 0;
BA_ "GenSigTimeoutTime_GNMM" SG_ 2651930776 Digit_05_DMSM 0;
BA_ "GenSigTimeoutTime_EVCU2" SG_ 2651930776 Digit_05_DMSM 0;
BA_ "GenSigTimeoutTime_ESL" SG_ 2651930776 Digit_05_DMSM 0;
BA_ "GenSigTimeoutTime_ECM" SG_ 2651930776 Digit_05_DMSM 0;
BA_ "GenSigTimeoutTime_DTCM" SG_ 2651930776 Digit_05_DMSM 0;
BA_ "GenSigTimeoutTime_DMSM" SG_ 2651930776 Digit_05_DMSM 0;
BA_ "GenSigTimeoutTime_BSM" SG_ 2651930776 Digit_05_DMSM 0;
BA_ "GenSigTimeoutTime_AGSM" SG_ 2651930776 Digit_05_DMSM 0;
BA_ "GenSigTimeoutTime_ADCAM" SG_ 2651930776 Digit_05_DMSM 0;
BA_ "GenSigTimeoutTime_SGW" SG_ 2651930776 Digit_06_DMSM 0;
BA_ "GenSigTimeoutTime_RFHM" SG_ 2651930776 Digit_06_DMSM 0;
BA_ "GenSigTimeoutTime_MPAD" SG_ 2651930776 Digit_06_DMSM 0;
BA_ "GenSigTimeoutTime_IPC" SG_ 2651930776 Digit_06_DMSM 0;
BA_ "GenSigTimeoutTime_GNMM" SG_ 2651930776 Digit_06_DMSM 0;
BA_ "GenSigTimeoutTime_EVCU2" SG_ 2651930776 Digit_06_DMSM 0;
BA_ "GenSigTimeoutTime_ESL" SG_ 2651930776 Digit_06_DMSM 0;
BA_ "GenSigTimeoutTime_ECM" SG_ 2651930776 Digit_06_DMSM 0;
BA_ "GenSigTimeoutTime_DTCM" SG_ 2651930776 Digit_06_DMSM 0;
BA_ "GenSigTimeoutTime_DMSM" SG_ 2651930776 Digit_06_DMSM 0;
BA_ "GenSigTimeoutTime_BSM" SG_ 2651930776 Digit_06_DMSM 0;
BA_ "GenSigTimeoutTime_AGSM" SG_ 2651930776 Digit_06_DMSM 0;
BA_ "GenSigTimeoutTime_ADCAM" SG_ 2651930776 Digit_06_DMSM 0;
BA_ "GenSigTimeoutTime_SGW" SG_ 2651930776 Digit_07_DMSM 0;
BA_ "GenSigTimeoutTime_RFHM" SG_ 2651930776 Digit_07_DMSM 0;
BA_ "GenSigTimeoutTime_MPAD" SG_ 2651930776 Digit_07_DMSM 0;
BA_ "GenSigTimeoutTime_IPC" SG_ 2651930776 Digit_07_DMSM 0;
BA_ "GenSigTimeoutTime_GNMM" SG_ 2651930776 Digit_07_DMSM 0;
BA_ "GenSigTimeoutTime_EVCU2" SG_ 2651930776 Digit_07_DMSM 0;
BA_ "GenSigTimeoutTime_ESL" SG_ 2651930776 Digit_07_DMSM 0;
BA_ "GenSigTimeoutTime_ECM" SG_ 2651930776 Digit_07_DMSM 0;
BA_ "GenSigTimeoutTime_DTCM" SG_ 2651930776 Digit_07_DMSM 0;
BA_ "GenSigTimeoutTime_DMSM" SG_ 2651930776 Digit_07_DMSM 0;
BA_ "GenSigTimeoutTime_BSM" SG_ 2651930776 Digit_07_DMSM 0;
BA_ "GenSigTimeoutTime_AGSM" SG_ 2651930776 Digit_07_DMSM 0;
BA_ "GenSigTimeoutTime_ADCAM" SG_ 2651930776 Digit_07_DMSM 0;
BA_ "GenSigTimeoutTime_SGW" SG_ 2651930776 Digit_08_DMSM 0;
BA_ "GenSigTimeoutTime_RFHM" SG_ 2651930776 Digit_08_DMSM 0;
BA_ "GenSigTimeoutTime_MPAD" SG_ 2651930776 Digit_08_DMSM 0;
BA_ "GenSigTimeoutTime_IPC" SG_ 2651930776 Digit_08_DMSM 0;
BA_ "GenSigTimeoutTime_GNMM" SG_ 2651930776 Digit_08_DMSM 0;
BA_ "GenSigTimeoutTime_EVCU2" SG_ 2651930776 Digit_08_DMSM 0;
BA_ "GenSigTimeoutTime_ESL" SG_ 2651930776 Digit_08_DMSM 0;
BA_ "GenSigTimeoutTime_ECM" SG_ 2651930776 Digit_08_DMSM 0;
BA_ "GenSigTimeoutTime_DTCM" SG_ 2651930776 Digit_08_DMSM 0;
BA_ "GenSigTimeoutTime_DMSM" SG_ 2651930776 Digit_08_DMSM 0;
BA_ "GenSigTimeoutTime_BSM" SG_ 2651930776 Digit_08_DMSM 0;
BA_ "GenSigTimeoutTime_AGSM" SG_ 2651930776 Digit_08_DMSM 0;
BA_ "GenSigTimeoutTime_ADCAM" SG_ 2651930776 Digit_08_DMSM 0;
BA_ "GenSigTimeoutTime_SGW" SG_ 2651930776 Digit_09_DMSM 0;
BA_ "GenSigTimeoutTime_RFHM" SG_ 2651930776 Digit_09_DMSM 0;
BA_ "GenSigTimeoutTime_MPAD" SG_ 2651930776 Digit_09_DMSM 0;
BA_ "GenSigTimeoutTime_IPC" SG_ 2651930776 Digit_09_DMSM 0;
BA_ "GenSigTimeoutTime_GNMM" SG_ 2651930776 Digit_09_DMSM 0;
BA_ "GenSigTimeoutTime_EVCU2" SG_ 2651930776 Digit_09_DMSM 0;
BA_ "GenSigTimeoutTime_ESL" SG_ 2651930776 Digit_09_DMSM 0;
BA_ "GenSigTimeoutTime_ECM" SG_ 2651930776 Digit_09_DMSM 0;
BA_ "GenSigTimeoutTime_DTCM" SG_ 2651930776 Digit_09_DMSM 0;
BA_ "GenSigTimeoutTime_DMSM" SG_ 2651930776 Digit_09_DMSM 0;
BA_ "GenSigTimeoutTime_BSM" SG_ 2651930776 Digit_09_DMSM 0;
BA_ "GenSigTimeoutTime_AGSM" SG_ 2651930776 Digit_09_DMSM 0;
BA_ "GenSigTimeoutTime_ADCAM" SG_ 2651930776 Digit_09_DMSM 0;
BA_ "GenSigTimeoutTime_SGW" SG_ 2651930776 Digit_10_DMSM 0;
BA_ "GenSigTimeoutTime_RFHM" SG_ 2651930776 Digit_10_DMSM 0;
BA_ "GenSigTimeoutTime_MPAD" SG_ 2651930776 Digit_10_DMSM 0;
BA_ "GenSigTimeoutTime_IPC" SG_ 2651930776 Digit_10_DMSM 0;
BA_ "GenSigTimeoutTime_GNMM" SG_ 2651930776 Digit_10_DMSM 0;
BA_ "GenSigTimeoutTime_EVCU2" SG_ 2651930776 Digit_10_DMSM 0;
BA_ "GenSigTimeoutTime_ESL" SG_ 2651930776 Digit_10_DMSM 0;
BA_ "GenSigTimeoutTime_ECM" SG_ 2651930776 Digit_10_DMSM 0;
BA_ "GenSigTimeoutTime_DTCM" SG_ 2651930776 Digit_10_DMSM 0;
BA_ "GenSigTimeoutTime_DMSM" SG_ 2651930776 Digit_10_DMSM 0;
BA_ "GenSigTimeoutTime_BSM" SG_ 2651930776 Digit_10_DMSM 0;
BA_ "GenSigTimeoutTime_AGSM" SG_ 2651930776 Digit_10_DMSM 0;
BA_ "GenSigTimeoutTime_ADCAM" SG_ 2651930776 Digit_10_DMSM 0;
BA_ "GenSigTimeoutTime_SGW" SG_ 2651930776 Digit_11_DMSM 0;
BA_ "GenSigTimeoutTime_RFHM" SG_ 2651930776 Digit_11_DMSM 0;
BA_ "GenSigTimeoutTime_MPAD" SG_ 2651930776 Digit_11_DMSM 0;
BA_ "GenSigTimeoutTime_IPC" SG_ 2651930776 Digit_11_DMSM 0;
BA_ "GenSigTimeoutTime_GNMM" SG_ 2651930776 Digit_11_DMSM 0;
BA_ "GenSigTimeoutTime_EVCU2" SG_ 2651930776 Digit_11_DMSM 0;
BA_ "GenSigTimeoutTime_ESL" SG_ 2651930776 Digit_11_DMSM 0;
BA_ "GenSigTimeoutTime_ECM" SG_ 2651930776 Digit_11_DMSM 0;
BA_ "GenSigTimeoutTime_DTCM" SG_ 2651930776 Digit_11_DMSM 0;
BA_ "GenSigTimeoutTime_DMSM" SG_ 2651930776 Digit_11_DMSM 0;
BA_ "GenSigTimeoutTime_BSM" SG_ 2651930776 Digit_11_DMSM 0;
BA_ "GenSigTimeoutTime_AGSM" SG_ 2651930776 Digit_11_DMSM 0;
BA_ "GenSigTimeoutTime_ADCAM" SG_ 2651930776 Digit_11_DMSM 0;
BA_ "GenSigTimeoutTime_SGW" SG_ 2651930776 Digit_01_DMSM 0;
BA_ "GenSigTimeoutTime_RFHM" SG_ 2651930776 Digit_01_DMSM 0;
BA_ "GenSigTimeoutTime_MPAD" SG_ 2651930776 Digit_01_DMSM 0;
BA_ "GenSigTimeoutTime_IPC" SG_ 2651930776 Digit_01_DMSM 0;
BA_ "GenSigTimeoutTime_GNMM" SG_ 2651930776 Digit_01_DMSM 0;
BA_ "GenSigTimeoutTime_EVCU2" SG_ 2651930776 Digit_01_DMSM 0;
BA_ "GenSigTimeoutTime_ESL" SG_ 2651930776 Digit_01_DMSM 0;
BA_ "GenSigTimeoutTime_ECM" SG_ 2651930776 Digit_01_DMSM 0;
BA_ "GenSigTimeoutTime_DTCM" SG_ 2651930776 Digit_01_DMSM 0;
BA_ "GenSigTimeoutTime_DMSM" SG_ 2651930776 Digit_01_DMSM 0;
BA_ "GenSigTimeoutTime_BSM" SG_ 2651930776 Digit_01_DMSM 0;
BA_ "GenSigTimeoutTime_AGSM" SG_ 2651930776 Digit_01_DMSM 0;
BA_ "GenSigTimeoutTime_ADCAM" SG_ 2651930776 Digit_01_DMSM 0;
BA_ "GenSigSendType" SG_ 2651930776 Digit_01_DMSM 1;
BA_ "GenSigTimeoutTime_GNMM" SG_ 2651930776 Digit_02_DMSM 0;
BA_ "GenSigTimeoutTime_EVCU2" SG_ 2651930776 Digit_02_DMSM 0;
BA_ "GenSigTimeoutTime_ESL" SG_ 2651930776 Digit_02_DMSM 0;
BA_ "GenSigTimeoutTime_ECM" SG_ 2651930776 Digit_02_DMSM 0;
BA_ "GenSigTimeoutTime_DTCM" SG_ 2651930776 Digit_02_DMSM 0;
BA_ "GenSigTimeoutTime_DMSM" SG_ 2651930776 Digit_02_DMSM 0;
BA_ "GenSigTimeoutTime_BSM" SG_ 2651930776 Digit_02_DMSM 0;
BA_ "GenSigTimeoutTime_AGSM" SG_ 2651930776 Digit_02_DMSM 0;
BA_ "GenSigTimeoutTime_ADCAM" SG_ 2651930776 Digit_02_DMSM 0;
BA_ "GenSigTimeoutTime_SGW" SG_ 2651930776 Digit_02_DMSM 0;
BA_ "GenSigTimeoutTime_RFHM" SG_ 2651930776 Digit_02_DMSM 0;
BA_ "GenSigTimeoutTime_MPAD" SG_ 2651930776 Digit_02_DMSM 0;
BA_ "GenSigTimeoutTime_IPC" SG_ 2651930776 Digit_02_DMSM 0;
BA_ "GenSigTimeoutTime_SGW" SG_ 2651930776 Digit_03_DMSM 0;
BA_ "GenSigTimeoutTime_RFHM" SG_ 2651930776 Digit_03_DMSM 0;
BA_ "GenSigTimeoutTime_MPAD" SG_ 2651930776 Digit_03_DMSM 0;
BA_ "GenSigTimeoutTime_IPC" SG_ 2651930776 Digit_03_DMSM 0;
BA_ "GenSigTimeoutTime_GNMM" SG_ 2651930776 Digit_03_DMSM 0;
BA_ "GenSigTimeoutTime_EVCU2" SG_ 2651930776 Digit_03_DMSM 0;
BA_ "GenSigTimeoutTime_ESL" SG_ 2651930776 Digit_03_DMSM 0;
BA_ "GenSigTimeoutTime_ECM" SG_ 2651930776 Digit_03_DMSM 0;
BA_ "GenSigTimeoutTime_DTCM" SG_ 2651930776 Digit_03_DMSM 0;
BA_ "GenSigTimeoutTime_DMSM" SG_ 2651930776 Digit_03_DMSM 0;
BA_ "GenSigTimeoutTime_BSM" SG_ 2651930776 Digit_03_DMSM 0;
BA_ "GenSigTimeoutTime_AGSM" SG_ 2651930776 Digit_03_DMSM 0;
BA_ "GenSigTimeoutTime_ADCAM" SG_ 2651930776 Digit_03_DMSM 0;
BA_ "GenSigTimeoutTime_SGW" SG_ 2651930776 Digit_04_DMSM 0;
BA_ "GenSigTimeoutTime_RFHM" SG_ 2651930776 Digit_04_DMSM 0;
BA_ "GenSigTimeoutTime_MPAD" SG_ 2651930776 Digit_04_DMSM 0;
BA_ "GenSigTimeoutTime_IPC" SG_ 2651930776 Digit_04_DMSM 0;
BA_ "GenSigTimeoutTime_GNMM" SG_ 2651930776 Digit_04_DMSM 0;
BA_ "GenSigTimeoutTime_EVCU2" SG_ 2651930776 Digit_04_DMSM 0;
BA_ "GenSigTimeoutTime_ESL" SG_ 2651930776 Digit_04_DMSM 0;
BA_ "GenSigTimeoutTime_ECM" SG_ 2651930776 Digit_04_DMSM 0;
BA_ "GenSigTimeoutTime_DTCM" SG_ 2651930776 Digit_04_DMSM 0;
BA_ "GenSigTimeoutTime_DMSM" SG_ 2651930776 Digit_04_DMSM 0;
BA_ "GenSigTimeoutTime_BSM" SG_ 2651930776 Digit_04_DMSM 0;
BA_ "GenSigTimeoutTime_AGSM" SG_ 2651930776 Digit_04_DMSM 0;
BA_ "GenSigTimeoutTime_ADCAM" SG_ 2651930776 Digit_04_DMSM 0;
BA_ "GenSigTimeoutTime_RFHM" SG_ 2654339093 PreviousCanNMState_FD03_ESL 0;
BA_ "GenSigTimeoutTime_MPAD" SG_ 2654339093 PreviousCanNMState_FD03_ESL 0;
BA_ "GenSigTimeoutTime_IPC" SG_ 2654339093 PreviousCanNMState_FD03_ESL 0;
BA_ "GenSigTimeoutTime_GNMM" SG_ 2654339093 PreviousCanNMState_FD03_ESL 0;
BA_ "GenSigTimeoutTime_EVCU2" SG_ 2654339093 PreviousCanNMState_FD03_ESL 0;
BA_ "GenSigTimeoutTime_ESL" SG_ 2654339093 PreviousCanNMState_FD03_ESL 0;
BA_ "GenSigTimeoutTime_ECM" SG_ 2654339093 PreviousCanNMState_FD03_ESL 0;
BA_ "GenSigTimeoutTime_DTCM" SG_ 2654339093 PreviousCanNMState_FD03_ESL 0;
BA_ "GenSigTimeoutTime_DMSM" SG_ 2654339093 PreviousCanNMState_FD03_ESL 0;
BA_ "GenSigTimeoutTime_BSM" SG_ 2654339093 PreviousCanNMState_FD03_ESL 0;
BA_ "GenSigTimeoutTime_BCM" SG_ 2654339093 PreviousCanNMState_FD03_ESL 0;
BA_ "GenSigTimeoutTime_AGSM" SG_ 2654339093 PreviousCanNMState_FD03_ESL 0;
BA_ "GenSigTimeoutTime_ADCAM" SG_ 2654339093 PreviousCanNMState_FD03_ESL 0;
BA_ "GenSigTimeoutTime_RFHM" SG_ 2654339093 DES_FD03_ESL 0;
BA_ "GenSigTimeoutTime_MPAD" SG_ 2654339093 DES_FD03_ESL 0;
BA_ "GenSigTimeoutTime_IPC" SG_ 2654339093 DES_FD03_ESL 0;
BA_ "GenSigTimeoutTime_GNMM" SG_ 2654339093 DES_FD03_ESL 0;
BA_ "GenSigTimeoutTime_EVCU2" SG_ 2654339093 DES_FD03_ESL 0;
BA_ "GenSigTimeoutTime_ESL" SG_ 2654339093 DES_FD03_ESL 0;
BA_ "GenSigTimeoutTime_ECM" SG_ 2654339093 DES_FD03_ESL 0;
BA_ "GenSigTimeoutTime_DTCM" SG_ 2654339093 DES_FD03_ESL 0;
BA_ "GenSigTimeoutTime_DMSM" SG_ 2654339093 DES_FD03_ESL 0;
BA_ "GenSigTimeoutTime_BSM" SG_ 2654339093 DES_FD03_ESL 0;
BA_ "GenSigTimeoutTime_BCM" SG_ 2654339093 DES_FD03_ESL 0;
BA_ "GenSigTimeoutTime_AGSM" SG_ 2654339093 DES_FD03_ESL 0;
BA_ "GenSigTimeoutTime_ADCAM" SG_ 2654339093 DES_FD03_ESL 0;
BA_ "GenSigTimeoutTime_RFHM" SG_ 2654339093 CurrentCanNMState_FD03_ESL 0;
BA_ "GenSigTimeoutTime_MPAD" SG_ 2654339093 CurrentCanNMState_FD03_ESL 0;
BA_ "GenSigTimeoutTime_IPC" SG_ 2654339093 CurrentCanNMState_FD03_ESL 0;
BA_ "GenSigTimeoutTime_GNMM" SG_ 2654339093 CurrentCanNMState_FD03_ESL 0;
BA_ "GenSigTimeoutTime_EVCU2" SG_ 2654339093 CurrentCanNMState_FD03_ESL 0;
BA_ "GenSigTimeoutTime_ESL" SG_ 2654339093 CurrentCanNMState_FD03_ESL 0;
BA_ "GenSigTimeoutTime_ECM" SG_ 2654339093 CurrentCanNMState_FD03_ESL 0;
BA_ "GenSigTimeoutTime_DTCM" SG_ 2654339093 CurrentCanNMState_FD03_ESL 0;
BA_ "GenSigTimeoutTime_DMSM" SG_ 2654339093 CurrentCanNMState_FD03_ESL 0;
BA_ "GenSigTimeoutTime_BSM" SG_ 2654339093 CurrentCanNMState_FD03_ESL 0;
BA_ "GenSigTimeoutTime_BCM" SG_ 2654339093 CurrentCanNMState_FD03_ESL 0;
BA_ "GenSigTimeoutTime_AGSM" SG_ 2654339093 CurrentCanNMState_FD03_ESL 0;
BA_ "GenSigTimeoutTime_ADCAM" SG_ 2654339093 CurrentCanNMState_FD03_ESL 0;
BA_ "GenSigTimeoutTime_RFHM" SG_ 2654339093 StayActiveSource_FD03_ESL 0;
BA_ "GenSigTimeoutTime_MPAD" SG_ 2654339093 StayActiveSource_FD03_ESL 0;
BA_ "GenSigTimeoutTime_IPC" SG_ 2654339093 StayActiveSource_FD03_ESL 0;
BA_ "GenSigTimeoutTime_GNMM" SG_ 2654339093 StayActiveSource_FD03_ESL 0;
BA_ "GenSigTimeoutTime_EVCU2" SG_ 2654339093 StayActiveSource_FD03_ESL 0;
BA_ "GenSigTimeoutTime_ESL" SG_ 2654339093 StayActiveSource_FD03_ESL 0;
BA_ "GenSigTimeoutTime_ECM" SG_ 2654339093 StayActiveSource_FD03_ESL 0;
BA_ "GenSigTimeoutTime_DTCM" SG_ 2654339093 StayActiveSource_FD03_ESL 0;
BA_ "GenSigTimeoutTime_DMSM" SG_ 2654339093 StayActiveSource_FD03_ESL 0;
BA_ "GenSigTimeoutTime_BSM" SG_ 2654339093 StayActiveSource_FD03_ESL 0;
BA_ "GenSigTimeoutTime_BCM" SG_ 2654339093 StayActiveSource_FD03_ESL 0;
BA_ "GenSigTimeoutTime_AGSM" SG_ 2654339093 StayActiveSource_FD03_ESL 0;
BA_ "GenSigTimeoutTime_ADCAM" SG_ 2654339093 StayActiveSource_FD03_ESL 0;
BA_ "GenSigTimeoutTime_ADCAM" SG_ 1438 CRC_DRV_MONITOR1 0;
BA_ "GenSigTimeoutTime_SGW" SG_ 1438 DM_Steering_Angle_Blockage 0;
BA_ "GenSigTimeoutTime_RFHM" SG_ 1438 DM_Steering_Angle_Blockage 0;
BA_ "GenSigTimeoutTime_IPC" SG_ 1438 DM_Steering_Angle_Blockage 0;
BA_ "GenSigTimeoutTime_GNMM" SG_ 1438 DM_Steering_Angle_Blockage 0;
BA_ "GenSigTimeoutTime_EVCU2" SG_ 1438 DM_Steering_Angle_Blockage 0;
BA_ "GenSigTimeoutTime_ESL" SG_ 1438 DM_Steering_Angle_Blockage 0;
BA_ "GenSigTimeoutTime_ECM" SG_ 1438 DM_Steering_Angle_Blockage 0;
BA_ "GenSigTimeoutTime_DTCM" SG_ 1438 DM_Steering_Angle_Blockage 0;
BA_ "GenSigTimeoutTime_DMSM" SG_ 1438 DM_Steering_Angle_Blockage 0;
BA_ "GenSigTimeoutTime_BSM" SG_ 1438 DM_Steering_Angle_Blockage 0;
BA_ "GenSigTimeoutTime_AGSM" SG_ 1438 DM_Steering_Angle_Blockage 0;
BA_ "GenSigTimeoutTime_ADCAM" SG_ 1438 DM_Steering_Angle_Blockage 0;
BA_ "GenSigSendType" SG_ 1438 DM_Steering_Angle_Blockage 3;
BA_ "GenSigTimeoutTime_SGW" SG_ 1438 DM_Drowsy_Level 0;
BA_ "GenSigTimeoutTime_RFHM" SG_ 1438 DM_Drowsy_Level 0;
BA_ "GenSigTimeoutTime_IPC" SG_ 1438 DM_Drowsy_Level 0;
BA_ "GenSigTimeoutTime_GNMM" SG_ 1438 DM_Drowsy_Level 0;
BA_ "GenSigTimeoutTime_EVCU2" SG_ 1438 DM_Drowsy_Level 0;
BA_ "GenSigTimeoutTime_ESL" SG_ 1438 DM_Drowsy_Level 0;
BA_ "GenSigTimeoutTime_ECM" SG_ 1438 DM_Drowsy_Level 0;
BA_ "GenSigTimeoutTime_DTCM" SG_ 1438 DM_Drowsy_Level 0;
BA_ "GenSigTimeoutTime_DMSM" SG_ 1438 DM_Drowsy_Level 0;
BA_ "GenSigTimeoutTime_BSM" SG_ 1438 DM_Drowsy_Level 0;
BA_ "GenSigTimeoutTime_AGSM" SG_ 1438 DM_Drowsy_Level 0;
BA_ "GenSigTimeoutTime_ADCAM" SG_ 1438 DM_Drowsy_Level 0;
BA_ "GenSigSendType" SG_ 1438 DM_Drowsy_Level 3;
BA_ "GenSigTimeoutTime_SGW" SG_ 1438 DM_Unresponsive 0;
BA_ "GenSigTimeoutTime_RFHM" SG_ 1438 DM_Unresponsive 0;
BA_ "GenSigTimeoutTime_IPC" SG_ 1438 DM_Unresponsive 0;
BA_ "GenSigTimeoutTime_GNMM" SG_ 1438 DM_Unresponsive 0;
BA_ "GenSigTimeoutTime_EVCU2" SG_ 1438 DM_Unresponsive 0;
BA_ "GenSigTimeoutTime_ESL" SG_ 1438 DM_Unresponsive 0;
BA_ "GenSigTimeoutTime_ECM" SG_ 1438 DM_Unresponsive 0;
BA_ "GenSigTimeoutTime_DTCM" SG_ 1438 DM_Unresponsive 0;
BA_ "GenSigTimeoutTime_DMSM" SG_ 1438 DM_Unresponsive 0;
BA_ "GenSigTimeoutTime_BSM" SG_ 1438 DM_Unresponsive 0;
BA_ "GenSigTimeoutTime_AGSM" SG_ 1438 DM_Unresponsive 0;
BA_ "GenSigTimeoutTime_ADCAM" SG_ 1438 DM_Unresponsive 0;
BA_ "GenSigSendType" SG_ 1438 DM_Unresponsive 3;
BA_ "GenSigTimeoutTime_SGW" SG_ 1438 DM_Distract_Instant_Seconds 0;
BA_ "GenSigTimeoutTime_RFHM" SG_ 1438 DM_Distract_Instant_Seconds 0;
BA_ "GenSigTimeoutTime_IPC" SG_ 1438 DM_Distract_Instant_Seconds 0;
BA_ "GenSigTimeoutTime_GNMM" SG_ 1438 DM_Distract_Instant_Seconds 0;
BA_ "GenSigTimeoutTime_EVCU2" SG_ 1438 DM_Distract_Instant_Seconds 0;
BA_ "GenSigTimeoutTime_ESL" SG_ 1438 DM_Distract_Instant_Seconds 0;
BA_ "GenSigTimeoutTime_ECM" SG_ 1438 DM_Distract_Instant_Seconds 0;
BA_ "GenSigTimeoutTime_DTCM" SG_ 1438 DM_Distract_Instant_Seconds 0;
BA_ "GenSigTimeoutTime_DMSM" SG_ 1438 DM_Distract_Instant_Seconds 0;
BA_ "GenSigTimeoutTime_BSM" SG_ 1438 DM_Distract_Instant_Seconds 0;
BA_ "GenSigTimeoutTime_BCM" SG_ 1438 DM_Distract_Instant_Seconds 0;
BA_ "GenSigTimeoutTime_AGSM" SG_ 1438 DM_Distract_Instant_Seconds 0;
BA_ "GenSigTimeoutTime_ADCAM" SG_ 1438 DM_Distract_Instant_Seconds 0;
BA_ "GenSigTimeoutTime_AGSM" SG_ 1438 Cntr_DRV_MONITOR1 0;
BA_ "GenSigTimeoutTime_ADCAM" SG_ 1438 Cntr_DRV_MONITOR1 0;
BA_ "GenSigTimeoutTime_SGW" SG_ 1438 Cntr_DRV_MONITOR1 0;
BA_ "GenSigTimeoutTime_RFHM" SG_ 1438 Cntr_DRV_MONITOR1 0;
BA_ "GenSigTimeoutTime_IPC" SG_ 1438 Cntr_DRV_MONITOR1 0;
BA_ "GenSigTimeoutTime_GNMM" SG_ 1438 Cntr_DRV_MONITOR1 0;
BA_ "GenSigTimeoutTime_EVCU2" SG_ 1438 Cntr_DRV_MONITOR1 0;
BA_ "GenSigTimeoutTime_ESL" SG_ 1438 Cntr_DRV_MONITOR1 0;
BA_ "GenSigTimeoutTime_ECM" SG_ 1438 Cntr_DRV_MONITOR1 0;
BA_ "GenSigTimeoutTime_DTCM" SG_ 1438 Cntr_DRV_MONITOR1 0;
BA_ "GenSigTimeoutTime_DMSM" SG_ 1438 Cntr_DRV_MONITOR1 0;
BA_ "GenSigTimeoutTime_BSM" SG_ 1438 Cntr_DRV_MONITOR1 0;
BA_ "GenSigTimeoutTime_SGW" SG_ 1438 DM_Distracted_Level 0;
BA_ "GenSigTimeoutTime_RFHM" SG_ 1438 DM_Distracted_Level 0;
BA_ "GenSigTimeoutTime_IPC" SG_ 1438 DM_Distracted_Level 0;
BA_ "GenSigTimeoutTime_GNMM" SG_ 1438 DM_Distracted_Level 0;
BA_ "GenSigTimeoutTime_EVCU2" SG_ 1438 DM_Distracted_Level 0;
BA_ "GenSigTimeoutTime_ESL" SG_ 1438 DM_Distracted_Level 0;
BA_ "GenSigTimeoutTime_ECM" SG_ 1438 DM_Distracted_Level 0;
BA_ "GenSigTimeoutTime_DTCM" SG_ 1438 DM_Distracted_Level 0;
BA_ "GenSigTimeoutTime_DMSM" SG_ 1438 DM_Distracted_Level 0;
BA_ "GenSigTimeoutTime_BSM" SG_ 1438 DM_Distracted_Level 0;
BA_ "GenSigTimeoutTime_AGSM" SG_ 1438 DM_Distracted_Level 0;
BA_ "GenSigTimeoutTime_ADCAM" SG_ 1438 DM_Distracted_Level 0;
BA_ "GenSigSendType" SG_ 1438 DM_Distracted_Level 3;
BA_ "GenSigTimeoutTime_SGW" SG_ 1438 DM_Drowsy_Instant_Seconds 0;
BA_ "GenSigTimeoutTime_RFHM" SG_ 1438 DM_Drowsy_Instant_Seconds 0;
BA_ "GenSigTimeoutTime_IPC" SG_ 1438 DM_Drowsy_Instant_Seconds 0;
BA_ "GenSigTimeoutTime_GNMM" SG_ 1438 DM_Drowsy_Instant_Seconds 0;
BA_ "GenSigTimeoutTime_EVCU2" SG_ 1438 DM_Drowsy_Instant_Seconds 0;
BA_ "GenSigTimeoutTime_ESL" SG_ 1438 DM_Drowsy_Instant_Seconds 0;
BA_ "GenSigTimeoutTime_ECM" SG_ 1438 DM_Drowsy_Instant_Seconds 0;
BA_ "GenSigTimeoutTime_DTCM" SG_ 1438 DM_Drowsy_Instant_Seconds 0;
BA_ "GenSigTimeoutTime_DMSM" SG_ 1438 DM_Drowsy_Instant_Seconds 0;
BA_ "GenSigTimeoutTime_BSM" SG_ 1438 DM_Drowsy_Instant_Seconds 0;
BA_ "GenSigTimeoutTime_BCM" SG_ 1438 DM_Drowsy_Instant_Seconds 0;
BA_ "GenSigTimeoutTime_AGSM" SG_ 1438 DM_Drowsy_Instant_Seconds 0;
BA_ "GenSigTimeoutTime_ADCAM" SG_ 1438 DM_Drowsy_Instant_Seconds 0;
BA_ "GenSigTimeoutTime_SGW" SG_ 2564485783 N_PDU 0;
BA_ "GenSigTimeoutTime_RFHM" SG_ 2564485783 N_PDU 0;
BA_ "GenSigTimeoutTime_MPAD" SG_ 2564485783 N_PDU 0;
BA_ "GenSigTimeoutTime_IPC" SG_ 2564485783 N_PDU 0;
BA_ "GenSigTimeoutTime_GNMM" SG_ 2564485783 N_PDU 0;
BA_ "GenSigTimeoutTime_EVCU2" SG_ 2564485783 N_PDU 0;
BA_ "GenSigTimeoutTime_ESL" SG_ 2564485783 N_PDU 0;
BA_ "GenSigTimeoutTime_ECM" SG_ 2564485783 N_PDU 0;
BA_ "GenSigTimeoutTime_DTCM" SG_ 2564485783 N_PDU 0;
BA_ "GenSigTimeoutTime_DMSM" SG_ 2564485783 N_PDU 0;
BA_ "GenSigTimeoutTime_BSM" SG_ 2564485783 N_PDU 0;
BA_ "GenSigTimeoutTime_BCM" SG_ 2564485783 N_PDU 0;
BA_ "GenSigTimeoutTime_AGSM" SG_ 2564485783 N_PDU 0;
BA_ "GenSigTimeoutTime_ADCAM" SG_ 2564485783 N_PDU 0;
BA_ "GenSigTimeoutTime_SGW" SG_ 2564485684 N_PDU 0;
BA_ "GenSigTimeoutTime_RFHM" SG_ 2564485684 N_PDU 0;
BA_ "GenSigTimeoutTime_MPAD" SG_ 2564485684 N_PDU 0;
BA_ "GenSigTimeoutTime_IPC" SG_ 2564485684 N_PDU 0;
BA_ "GenSigTimeoutTime_GNMM" SG_ 2564485684 N_PDU 0;
BA_ "GenSigTimeoutTime_EVCU2" SG_ 2564485684 N_PDU 0;
BA_ "GenSigTimeoutTime_ESL" SG_ 2564485684 N_PDU 0;
BA_ "GenSigTimeoutTime_ECM" SG_ 2564485684 N_PDU 0;
BA_ "GenSigTimeoutTime_DTCM" SG_ 2564485684 N_PDU 0;
BA_ "GenSigTimeoutTime_DMSM" SG_ 2564485684 N_PDU 0;
BA_ "GenSigTimeoutTime_BSM" SG_ 2564485684 N_PDU 0;
BA_ "GenSigTimeoutTime_BCM" SG_ 2564485684 N_PDU 0;
BA_ "GenSigTimeoutTime_AGSM" SG_ 2564485684 N_PDU 0;
BA_ "GenSigTimeoutTime_ADCAM" SG_ 2564485684 N_PDU 0;
BA_ "GenSigTimeoutTime_RFHM" SG_ 2654339093 EOL_FD03_ESL 0;
BA_ "GenSigTimeoutTime_MPAD" SG_ 2654339093 EOL_FD03_ESL 0;
BA_ "GenSigTimeoutTime_IPC" SG_ 2654339093 EOL_FD03_ESL 0;
BA_ "GenSigTimeoutTime_GNMM" SG_ 2654339093 EOL_FD03_ESL 0;
BA_ "GenSigTimeoutTime_EVCU2" SG_ 2654339093 EOL_FD03_ESL 0;
BA_ "GenSigTimeoutTime_ESL" SG_ 2654339093 EOL_FD03_ESL 0;
BA_ "GenSigTimeoutTime_ECM" SG_ 2654339093 EOL_FD03_ESL 0;
BA_ "GenSigTimeoutTime_DTCM" SG_ 2654339093 EOL_FD03_ESL 0;
BA_ "GenSigTimeoutTime_DMSM" SG_ 2654339093 EOL_FD03_ESL 0;
BA_ "GenSigTimeoutTime_BSM" SG_ 2654339093 EOL_FD03_ESL 0;
BA_ "GenSigTimeoutTime_AGSM" SG_ 2654339093 EOL_FD03_ESL 0;
BA_ "GenSigTimeoutTime_ADCAM" SG_ 2654339093 EOL_FD03_ESL 0;
BA_ "GenSigTimeoutTime_RFHM" SG_ 2654339093 CurrentFailSts_FD03_ESL 0;
BA_ "GenSigTimeoutTime_MPAD" SG_ 2654339093 CurrentFailSts_FD03_ESL 0;
BA_ "GenSigTimeoutTime_IPC" SG_ 2654339093 CurrentFailSts_FD03_ESL 0;
BA_ "GenSigTimeoutTime_GNMM" SG_ 2654339093 CurrentFailSts_FD03_ESL 0;
BA_ "GenSigTimeoutTime_EVCU2" SG_ 2654339093 CurrentFailSts_FD03_ESL 0;
BA_ "GenSigTimeoutTime_ESL" SG_ 2654339093 CurrentFailSts_FD03_ESL 0;
BA_ "GenSigTimeoutTime_ECM" SG_ 2654339093 CurrentFailSts_FD03_ESL 0;
BA_ "GenSigTimeoutTime_DTCM" SG_ 2654339093 CurrentFailSts_FD03_ESL 0;
BA_ "GenSigTimeoutTime_DMSM" SG_ 2654339093 CurrentFailSts_FD03_ESL 0;
BA_ "GenSigTimeoutTime_BSM" SG_ 2654339093 CurrentFailSts_FD03_ESL 0;
BA_ "GenSigTimeoutTime_AGSM" SG_ 2654339093 CurrentFailSts_FD03_ESL 0;
BA_ "GenSigTimeoutTime_ADCAM" SG_ 2654339093 CurrentFailSts_FD03_ESL 0;
BA_ "GenSigTimeoutTime_RFHM" SG_ 2654339093 GenericFailSts_FD03_ESL 0;
BA_ "GenSigTimeoutTime_MPAD" SG_ 2654339093 GenericFailSts_FD03_ESL 0;
BA_ "GenSigTimeoutTime_IPC" SG_ 2654339093 GenericFailSts_FD03_ESL 0;
BA_ "GenSigTimeoutTime_GNMM" SG_ 2654339093 GenericFailSts_FD03_ESL 0;
BA_ "GenSigTimeoutTime_EVCU2" SG_ 2654339093 GenericFailSts_FD03_ESL 0;
BA_ "GenSigTimeoutTime_ESL" SG_ 2654339093 GenericFailSts_FD03_ESL 0;
BA_ "GenSigTimeoutTime_ECM" SG_ 2654339093 GenericFailSts_FD03_ESL 0;
BA_ "GenSigTimeoutTime_DTCM" SG_ 2654339093 GenericFailSts_FD03_ESL 0;
BA_ "GenSigTimeoutTime_DMSM" SG_ 2654339093 GenericFailSts_FD03_ESL 0;
BA_ "GenSigTimeoutTime_BSM" SG_ 2654339093 GenericFailSts_FD03_ESL 0;
BA_ "GenSigTimeoutTime_AGSM" SG_ 2654339093 GenericFailSts_FD03_ESL 0;
BA_ "GenSigTimeoutTime_ADCAM" SG_ 2654339093 GenericFailSts_FD03_ESL 0;
BA_ "GenSigTimeoutTime_RFHM" SG_ 2654339075 GenericFailSts_FD03_IPC 0;
BA_ "GenSigTimeoutTime_MPAD" SG_ 2654339075 GenericFailSts_FD03_IPC 0;
BA_ "GenSigTimeoutTime_IPC" SG_ 2654339075 GenericFailSts_FD03_IPC 0;
BA_ "GenSigTimeoutTime_GNMM" SG_ 2654339075 GenericFailSts_FD03_IPC 0;
BA_ "GenSigTimeoutTime_EVCU2" SG_ 2654339075 GenericFailSts_FD03_IPC 0;
BA_ "GenSigTimeoutTime_ESL" SG_ 2654339075 GenericFailSts_FD03_IPC 0;
BA_ "GenSigTimeoutTime_ECM" SG_ 2654339075 GenericFailSts_FD03_IPC 0;
BA_ "GenSigTimeoutTime_DTCM" SG_ 2654339075 GenericFailSts_FD03_IPC 0;
BA_ "GenSigTimeoutTime_DMSM" SG_ 2654339075 GenericFailSts_FD03_IPC 0;
BA_ "GenSigTimeoutTime_BSM" SG_ 2654339075 GenericFailSts_FD03_IPC 0;
BA_ "GenSigTimeoutTime_AGSM" SG_ 2654339075 GenericFailSts_FD03_IPC 0;
BA_ "GenSigTimeoutTime_ADCAM" SG_ 2654339075 GenericFailSts_FD03_IPC 0;
BA_ "GenSigTimeoutTime_RFHM" SG_ 2654339075 EOL_FD03_IPC 0;
BA_ "GenSigTimeoutTime_MPAD" SG_ 2654339075 EOL_FD03_IPC 0;
BA_ "GenSigTimeoutTime_IPC" SG_ 2654339075 EOL_FD03_IPC 0;
BA_ "GenSigTimeoutTime_GNMM" SG_ 2654339075 EOL_FD03_IPC 0;
BA_ "GenSigTimeoutTime_EVCU2" SG_ 2654339075 EOL_FD03_IPC 0;
BA_ "GenSigTimeoutTime_ESL" SG_ 2654339075 EOL_FD03_IPC 0;
BA_ "GenSigTimeoutTime_ECM" SG_ 2654339075 EOL_FD03_IPC 0;
BA_ "GenSigTimeoutTime_DTCM" SG_ 2654339075 EOL_FD03_IPC 0;
BA_ "GenSigTimeoutTime_DMSM" SG_ 2654339075 EOL_FD03_IPC 0;
BA_ "GenSigTimeoutTime_BSM" SG_ 2654339075 EOL_FD03_IPC 0;
BA_ "GenSigTimeoutTime_AGSM" SG_ 2654339075 EOL_FD03_IPC 0;
BA_ "GenSigTimeoutTime_ADCAM" SG_ 2654339075 EOL_FD03_IPC 0;
BA_ "GenSigTimeoutTime_RFHM" SG_ 2654339075 CurrentFailSts_FD03_IPC 0;
BA_ "GenSigTimeoutTime_MPAD" SG_ 2654339075 CurrentFailSts_FD03_IPC 0;
BA_ "GenSigTimeoutTime_IPC" SG_ 2654339075 CurrentFailSts_FD03_IPC 0;
BA_ "GenSigTimeoutTime_GNMM" SG_ 2654339075 CurrentFailSts_FD03_IPC 0;
BA_ "GenSigTimeoutTime_EVCU2" SG_ 2654339075 CurrentFailSts_FD03_IPC 0;
BA_ "GenSigTimeoutTime_ESL" SG_ 2654339075 CurrentFailSts_FD03_IPC 0;
BA_ "GenSigTimeoutTime_ECM" SG_ 2654339078 DES_FD03_BSM 0;
BA_ "GenSigTimeoutTime_DTCM" SG_ 2654339078 DES_FD03_BSM 0;
BA_ "GenSigTimeoutTime_DMSM" SG_ 2654339078 DES_FD03_BSM 0;
BA_ "GenSigTimeoutTime_BSM" SG_ 2654339078 DES_FD03_BSM 0;
BA_ "GenSigTimeoutTime_BCM" SG_ 2654339078 DES_FD03_BSM 0;
BA_ "GenSigTimeoutTime_AGSM" SG_ 2654339078 DES_FD03_BSM 0;
BA_ "GenSigTimeoutTime_ADCAM" SG_ 2654339078 DES_FD03_BSM 0;
BA_ "GenSigTimeoutTime_RFHM" SG_ 2654339078 CurrentFailSts_FD03_BSM 0;
BA_ "GenSigTimeoutTime_MPAD" SG_ 2654339078 CurrentFailSts_FD03_BSM 0;
BA_ "GenSigTimeoutTime_IPC" SG_ 2654339078 CurrentFailSts_FD03_BSM 0;
BA_ "GenSigTimeoutTime_GNMM" SG_ 2654339078 CurrentFailSts_FD03_BSM 0;
BA_ "GenSigTimeoutTime_EVCU2" SG_ 2654339078 CurrentFailSts_FD03_BSM 0;
BA_ "GenSigTimeoutTime_ESL" SG_ 2654339078 CurrentFailSts_FD03_BSM 0;
BA_ "GenSigTimeoutTime_ECM" SG_ 2654339078 CurrentFailSts_FD03_BSM 0;
BA_ "GenSigTimeoutTime_DTCM" SG_ 2654339078 CurrentFailSts_FD03_BSM 0;
BA_ "GenSigTimeoutTime_DMSM" SG_ 2654339078 CurrentFailSts_FD03_BSM 0;
BA_ "GenSigTimeoutTime_BSM" SG_ 2654339078 CurrentFailSts_FD03_BSM 0;
BA_ "GenSigTimeoutTime_AGSM" SG_ 2654339078 CurrentFailSts_FD03_BSM 0;
BA_ "GenSigTimeoutTime_ADCAM" SG_ 2654339078 CurrentFailSts_FD03_BSM 0;
BA_ "GenSigTimeoutTime_RFHM" SG_ 2654339139 WakeupSource_FD03_DTCM 0;
BA_ "GenSigTimeoutTime_MPAD" SG_ 2654339139 WakeupSource_FD03_DTCM 0;
BA_ "GenSigTimeoutTime_IPC" SG_ 2654339139 WakeupSource_FD03_DTCM 0;
BA_ "GenSigTimeoutTime_GNMM" SG_ 2654339139 WakeupSource_FD03_DTCM 0;
BA_ "GenSigTimeoutTime_EVCU2" SG_ 2654339139 WakeupSource_FD03_DTCM 0;
BA_ "GenSigTimeoutTime_ESL" SG_ 2654339139 WakeupSource_FD03_DTCM 0;
BA_ "GenSigTimeoutTime_ECM" SG_ 2654339139 WakeupSource_FD03_DTCM 0;
BA_ "GenSigTimeoutTime_DTCM" SG_ 2654339139 WakeupSource_FD03_DTCM 0;
BA_ "GenSigTimeoutTime_DMSM" SG_ 2654339139 WakeupSource_FD03_DTCM 0;
BA_ "GenSigTimeoutTime_BSM" SG_ 2654339139 WakeupSource_FD03_DTCM 0;
BA_ "GenSigTimeoutTime_BCM" SG_ 2654339139 WakeupSource_FD03_DTCM 0;
BA_ "GenSigTimeoutTime_AGSM" SG_ 2654339139 WakeupSource_FD03_DTCM 0;
BA_ "GenSigTimeoutTime_ADCAM" SG_ 2654339139 WakeupSource_FD03_DTCM 0;
BA_ "GenSigTimeoutTime_SGW" SG_ 2654339172 CurrentCanNMState_FD08_DTV 0;
BA_ "GenSigTimeoutTime_RFHM" SG_ 2654339172 CurrentCanNMState_FD08_DTV 0;
BA_ "GenSigTimeoutTime_MPAD" SG_ 2654339172 CurrentCanNMState_FD08_DTV 0;
BA_ "GenSigTimeoutTime_IPC" SG_ 2654339172 CurrentCanNMState_FD08_DTV 0;
BA_ "GenSigTimeoutTime_GNMM" SG_ 2654339172 CurrentCanNMState_FD08_DTV 0;
BA_ "GenSigTimeoutTime_EVCU2" SG_ 2654339172 CurrentCanNMState_FD08_DTV 0;
BA_ "GenSigTimeoutTime_ESL" SG_ 2654339172 CurrentCanNMState_FD08_DTV 0;
BA_ "GenSigTimeoutTime_ECM" SG_ 2654339172 CurrentCanNMState_FD08_DTV 0;
BA_ "GenSigTimeoutTime_DTCM" SG_ 2654339172 CurrentCanNMState_FD08_DTV 0;
BA_ "GenSigTimeoutTime_DMSM" SG_ 2654339172 CurrentCanNMState_FD08_DTV 0;
BA_ "GenSigTimeoutTime_BSM" SG_ 2654339172 CurrentCanNMState_FD08_DTV 0;
BA_ "GenSigTimeoutTime_BCM" SG_ 2654339172 CurrentCanNMState_FD08_DTV 0;
BA_ "GenSigTimeoutTime_AGSM" SG_ 2654339172 CurrentCanNMState_FD08_DTV 0;
BA_ "GenSigTimeoutTime_ADCAM" SG_ 2654339172 CurrentCanNMState_FD08_DTV 0;
BA_ "GenSigTimeoutTime_SGW" SG_ 2654339172 PreviousCanNMState_FD08_DTV 0;
BA_ "GenSigTimeoutTime_RFHM" SG_ 2654339172 PreviousCanNMState_FD08_DTV 0;
BA_ "GenSigTimeoutTime_MPAD" SG_ 2654339172 PreviousCanNMState_FD08_DTV 0;
BA_ "GenSigTimeoutTime_IPC" SG_ 2654339172 PreviousCanNMState_FD08_DTV 0;
BA_ "GenSigTimeoutTime_GNMM" SG_ 2654339172 PreviousCanNMState_FD08_DTV 0;
BA_ "GenSigTimeoutTime_EVCU2" SG_ 2654339172 PreviousCanNMState_FD08_DTV 0;
BA_ "GenSigTimeoutTime_ESL" SG_ 2654339172 PreviousCanNMState_FD08_DTV 0;
BA_ "GenSigTimeoutTime_ECM" SG_ 2654339172 PreviousCanNMState_FD08_DTV 0;
BA_ "GenSigTimeoutTime_DTCM" SG_ 2654339172 PreviousCanNMState_FD08_DTV 0;
BA_ "GenSigTimeoutTime_DMSM" SG_ 2654339172 PreviousCanNMState_FD08_DTV 0;
BA_ "GenSigTimeoutTime_BSM" SG_ 2654339172 PreviousCanNMState_FD08_DTV 0;
BA_ "GenSigTimeoutTime_BCM" SG_ 2654339172 PreviousCanNMState_FD08_DTV 0;
BA_ "GenSigTimeoutTime_AGSM" SG_ 2654339172 PreviousCanNMState_FD08_DTV 0;
BA_ "GenSigTimeoutTime_ADCAM" SG_ 2654339172 PreviousCanNMState_FD08_DTV 0;
BA_ "GenSigTimeoutTime_SGW" SG_ 2654339172 DES_FD08_DTV 0;
BA_ "GenSigTimeoutTime_RFHM" SG_ 2654339172 DES_FD08_DTV 0;
BA_ "GenSigTimeoutTime_MPAD" SG_ 2654339172 DES_FD08_DTV 0;
BA_ "GenSigTimeoutTime_IPC" SG_ 2654339172 DES_FD08_DTV 0;
BA_ "GenSigTimeoutTime_GNMM" SG_ 2654339172 DES_FD08_DTV 0;
BA_ "GenSigTimeoutTime_EVCU2" SG_ 2654339172 DES_FD08_DTV 0;
BA_ "GenSigTimeoutTime_ESL" SG_ 2654339172 DES_FD08_DTV 0;
BA_ "GenSigTimeoutTime_ECM" SG_ 2654339172 DES_FD08_DTV 0;
BA_ "GenSigTimeoutTime_DTCM" SG_ 2654339172 DES_FD08_DTV 0;
BA_ "GenSigTimeoutTime_DMSM" SG_ 2654339172 DES_FD08_DTV 0;
BA_ "GenSigTimeoutTime_BSM" SG_ 2654339172 DES_FD08_DTV 0;
BA_ "GenSigTimeoutTime_BCM" SG_ 2654339172 DES_FD08_DTV 0;
BA_ "GenSigTimeoutTime_AGSM" SG_ 2654339172 DES_FD08_DTV 0;
BA_ "GenSigTimeoutTime_ADCAM" SG_ 2654339172 DES_FD08_DTV 0;
BA_ "GenSigTimeoutTime_SGW" SG_ 2654339172 WakeupSource_FD08_DTV 0;
BA_ "GenSigTimeoutTime_RFHM" SG_ 2654339172 WakeupSource_FD08_DTV 0;
BA_ "GenSigTimeoutTime_MPAD" SG_ 2654339172 WakeupSource_FD08_DTV 0;
BA_ "GenSigTimeoutTime_IPC" SG_ 2654339172 WakeupSource_FD08_DTV 0;
BA_ "GenSigTimeoutTime_GNMM" SG_ 2654339172 WakeupSource_FD08_DTV 0;
BA_ "GenSigTimeoutTime_EVCU2" SG_ 2654339172 WakeupSource_FD08_DTV 0;
BA_ "GenSigTimeoutTime_ESL" SG_ 2654339172 WakeupSource_FD08_DTV 0;
BA_ "GenSigTimeoutTime_ECM" SG_ 2654339172 WakeupSource_FD08_DTV 0;
BA_ "GenSigTimeoutTime_DTCM" SG_ 2654339172 WakeupSource_FD08_DTV 0;
BA_ "GenSigTimeoutTime_DMSM" SG_ 2654339172 WakeupSource_FD08_DTV 0;
BA_ "GenSigTimeoutTime_BSM" SG_ 2654339172 WakeupSource_FD08_DTV 0;
BA_ "GenSigTimeoutTime_BCM" SG_ 2654339172 WakeupSource_FD08_DTV 0;
BA_ "GenSigTimeoutTime_AGSM" SG_ 2654339172 WakeupSource_FD08_DTV 0;
BA_ "GenSigTimeoutTime_ADCAM" SG_ 2654339172 WakeupSource_FD08_DTV 0;
BA_ "GenSigTimeoutTime_SGW" SG_ 2654339172 StayActiveSource_FD08_DTV 0;
BA_ "GenSigTimeoutTime_RFHM" SG_ 2654339172 StayActiveSource_FD08_DTV 0;
BA_ "GenSigTimeoutTime_MPAD" SG_ 2654339172 StayActiveSource_FD08_DTV 0;
BA_ "GenSigTimeoutTime_IPC" SG_ 2654339172 StayActiveSource_FD08_DTV 0;
BA_ "GenSigTimeoutTime_GNMM" SG_ 2654339172 StayActiveSource_FD08_DTV 0;
BA_ "GenSigTimeoutTime_EVCU2" SG_ 2654339172 StayActiveSource_FD08_DTV 0;
BA_ "GenSigTimeoutTime_ESL" SG_ 2654339172 StayActiveSource_FD08_DTV 0;
BA_ "GenSigTimeoutTime_ECM" SG_ 2654339172 StayActiveSource_FD08_DTV 0;
BA_ "GenSigTimeoutTime_DTCM" SG_ 2654339172 StayActiveSource_FD08_DTV 0;
BA_ "GenSigTimeoutTime_DMSM" SG_ 2654339172 StayActiveSource_FD08_DTV 0;
BA_ "GenSigTimeoutTime_BSM" SG_ 2654339172 StayActiveSource_FD08_DTV 0;
BA_ "GenSigTimeoutTime_BCM" SG_ 2654339172 StayActiveSource_FD08_DTV 0;
BA_ "GenSigTimeoutTime_AGSM" SG_ 2654339172 StayActiveSource_FD08_DTV 0;
BA_ "GenSigTimeoutTime_ADCAM" SG_ 2654339172 StayActiveSource_FD08_DTV 0;
BA_ "GenSigTimeoutTime_SGW" SG_ 2654339108 PreviousCanNMState_FD08_ETM 0;
BA_ "GenSigTimeoutTime_RFHM" SG_ 2654339108 PreviousCanNMState_FD08_ETM 0;
BA_ "GenSigTimeoutTime_MPAD" SG_ 2654339108 PreviousCanNMState_FD08_ETM 0;
BA_ "GenSigTimeoutTime_IPC" SG_ 2654339108 PreviousCanNMState_FD08_ETM 0;
BA_ "GenSigTimeoutTime_GNMM" SG_ 2654339108 PreviousCanNMState_FD08_ETM 0;
BA_ "GenSigTimeoutTime_EVCU2" SG_ 2654339108 PreviousCanNMState_FD08_ETM 0;
BA_ "GenSigTimeoutTime_ESL" SG_ 2654339108 PreviousCanNMState_FD08_ETM 0;
BA_ "GenSigTimeoutTime_ECM" SG_ 2654339108 PreviousCanNMState_FD08_ETM 0;
BA_ "GenSigTimeoutTime_DTCM" SG_ 2654339108 PreviousCanNMState_FD08_ETM 0;
BA_ "GenSigTimeoutTime_DMSM" SG_ 2654339108 PreviousCanNMState_FD08_ETM 0;
BA_ "GenSigTimeoutTime_BSM" SG_ 2654339108 PreviousCanNMState_FD08_ETM 0;
BA_ "GenSigTimeoutTime_BCM" SG_ 2654339108 PreviousCanNMState_FD08_ETM 0;
BA_ "GenSigTimeoutTime_AGSM" SG_ 2654339108 PreviousCanNMState_FD08_ETM 0;
BA_ "GenSigTimeoutTime_ADCAM" SG_ 2654339108 PreviousCanNMState_FD08_ETM 0;
BA_ "GenSigTimeoutTime_SGW" SG_ 2564485527 N_PDU 0;
BA_ "GenSigTimeoutTime_RFHM" SG_ 2564485527 N_PDU 0;
BA_ "GenSigTimeoutTime_MPAD" SG_ 2564485527 N_PDU 0;
BA_ "GenSigTimeoutTime_IPC" SG_ 2564485527 N_PDU 0;
BA_ "GenSigTimeoutTime_GNMM" SG_ 2564485527 N_PDU 0;
BA_ "GenSigTimeoutTime_EVCU2" SG_ 2564485527 N_PDU 0;
BA_ "GenSigTimeoutTime_ESL" SG_ 2564485527 N_PDU 0;
BA_ "GenSigTimeoutTime_ECM" SG_ 2564485527 N_PDU 0;
BA_ "GenSigTimeoutTime_DTCM" SG_ 2564485527 N_PDU 0;
BA_ "GenSigTimeoutTime_DMSM" SG_ 2564485527 N_PDU 0;
BA_ "GenSigTimeoutTime_BSM" SG_ 2564485527 N_PDU 0;
BA_ "GenSigTimeoutTime_SGW" SG_ 754 RsErrIBS3_2 0;
BA_ "GenSigTimeoutTime_RFHM" SG_ 754 RsErrIBS3_2 0;
BA_ "GenSigTimeoutTime_MPAD" SG_ 754 RsErrIBS3_2 0;
BA_ "GenSigTimeoutTime_IPC" SG_ 754 RsErrIBS3_2 0;
BA_ "GenSigTimeoutTime_GNMM" SG_ 754 RsErrIBS3_2 0;
BA_ "GenSigTimeoutTime_ESL" SG_ 754 RsErrIBS3_2 0;
BA_ "GenSigTimeoutTime_ECM" SG_ 754 RsErrIBS3_2 0;
BA_ "GenSigTimeoutTime_DTCM" SG_ 754 RsErrIBS3_2 0;
BA_ "GenSigTimeoutTime_DMSM" SG_ 754 RsErrIBS3_2 0;
BA_ "GenSigTimeoutTime_BSM" SG_ 754 RsErrIBS3_2 0;
BA_ "GenSigTimeoutTime_BCM" SG_ 754 RsErrIBS3_2 0;
BA_ "GenSigTimeoutTime_AGSM" SG_ 754 RsErrIBS3_2 0;
BA_ "GenSigTimeoutTime_ADCAM" SG_ 754 RsErrIBS3_2 0;
BA_ "GenSigTimeoutTime_SGW" SG_ 754 VoltBattFailStatus_2 0;
BA_ "GenSigTimeoutTime_RFHM" SG_ 754 VoltBattFailStatus_2 0;
BA_ "GenSigTimeoutTime_MPAD" SG_ 754 VoltBattFailStatus_2 0;
BA_ "GenSigTimeoutTime_IPC" SG_ 754 VoltBattFailStatus_2 0;
BA_ "GenSigTimeoutTime_GNMM" SG_ 754 VoltBattFailStatus_2 0;
BA_ "GenSigTimeoutTime_ESL" SG_ 754 VoltBattFailStatus_2 0;
BA_ "GenSigTimeoutTime_ECM" SG_ 754 VoltBattFailStatus_2 0;
BA_ "GenSigTimeoutTime_DTCM" SG_ 754 VoltBattFailStatus_2 0;
BA_ "GenSigTimeoutTime_DMSM" SG_ 754 VoltBattFailStatus_2 0;
BA_ "GenSigTimeoutTime_BSM" SG_ 754 VoltBattFailStatus_2 0;
BA_ "GenSigTimeoutTime_BCM" SG_ 754 VoltBattFailStatus_2 0;
BA_ "GenSigTimeoutTime_AGSM" SG_ 754 VoltBattFailStatus_2 0;
BA_ "GenSigTimeoutTime_ADCAM" SG_ 754 VoltBattFailStatus_2 0;
BA_ "GenSigTimeoutTime_SGW" SG_ 754 CurrBattFailStatus_2 0;
BA_ "GenSigTimeoutTime_RFHM" SG_ 754 CurrBattFailStatus_2 0;
BA_ "GenSigTimeoutTime_MPAD" SG_ 754 CurrBattFailStatus_2 0;
BA_ "GenSigTimeoutTime_IPC" SG_ 754 CurrBattFailStatus_2 0;
BA_ "GenSigTimeoutTime_GNMM" SG_ 754 CurrBattFailStatus_2 0;
BA_ "GenSigTimeoutTime_ESL" SG_ 754 CurrBattFailStatus_2 0;
BA_ "GenSigTimeoutTime_ECM" SG_ 754 CurrBattFailStatus_2 0;
BA_ "GenSigTimeoutTime_DTCM" SG_ 754 CurrBattFailStatus_2 0;
BA_ "GenSigTimeoutTime_DMSM" SG_ 754 CurrBattFailStatus_2 0;
BA_ "GenSigTimeoutTime_BSM" SG_ 754 CurrBattFailStatus_2 0;
BA_ "GenSigTimeoutTime_BCM" SG_ 754 CurrBattFailStatus_2 0;
BA_ "GenSigTimeoutTime_AGSM" SG_ 754 CurrBattFailStatus_2 0;
BA_ "GenSigTimeoutTime_ADCAM" SG_ 754 CurrBattFailStatus_2 0;
BA_ "GenSigTimeoutTime_RFHM" SG_ 754 IBS3_Error_Internal_2 0;
BA_ "GenSigTimeoutTime_MPAD" SG_ 754 IBS3_Error_Internal_2 0;
BA_ "GenSigTimeoutTime_IPC" SG_ 754 IBS3_Error_Internal_2 0;
BA_ "GenSigTimeoutTime_GNMM" SG_ 754 IBS3_Error_Internal_2 0;
BA_ "GenSigTimeoutTime_ESL" SG_ 754 IBS3_Error_Internal_2 0;
BA_ "GenSigTimeoutTime_ECM" SG_ 754 IBS3_Error_Internal_2 0;
BA_ "GenSigTimeoutTime_DTCM" SG_ 754 IBS3_Error_Internal_2 0;
BA_ "GenSigTimeoutTime_DMSM" SG_ 754 IBS3_Error_Internal_2 0;
BA_ "GenSigTimeoutTime_BSM" SG_ 754 IBS3_Error_Internal_2 0;
BA_ "GenSigTimeoutTime_BCM" SG_ 754 IBS3_Error_Internal_2 0;
BA_ "GenSigTimeoutTime_AGSM" SG_ 754 IBS3_Error_Internal_2 0;
BA_ "GenSigTimeoutTime_ADCAM" SG_ 754 IBS3_Error_Internal_2 0;
BA_ "GenSigTimeoutTime_SGW" SG_ 754 IBS3_Error_Internal_2 0;
BA_ "GenSigTimeoutTime_SGW" SG_ 754 CRC_IBS3DATA1_2 0;
BA_ "GenSigTimeoutTime_RFHM" SG_ 754 CRC_IBS3DATA1_2 0;
BA_ "GenSigTimeoutTime_MPAD" SG_ 754 CRC_IBS3DATA1_2 0;
BA_ "GenSigTimeoutTime_IPC" SG_ 754 CRC_IBS3DATA1_2 0;
BA_ "GenSigTimeoutTime_GNMM" SG_ 754 CRC_IBS3DATA1_2 0;
BA_ "GenSigTimeoutTime_EVCU2" SG_ 754 CRC_IBS3DATA1_2 0;
BA_ "GenSigTimeoutTime_ESL" SG_ 754 CRC_IBS3DATA1_2 0;
BA_ "GenSigTimeoutTime_ECM" SG_ 754 CRC_IBS3DATA1_2 0;
BA_ "GenSigTimeoutTime_DTCM" SG_ 754 CRC_IBS3DATA1_2 0;
BA_ "GenSigTimeoutTime_SGW" SG_ 754 MessageCounter_IBS3DATA1_2 0;
BA_ "GenSigTimeoutTime_RFHM" SG_ 754 MessageCounter_IBS3DATA1_2 0;
BA_ "GenSigTimeoutTime_MPAD" SG_ 754 MessageCounter_IBS3DATA1_2 0;
BA_ "GenSigTimeoutTime_IPC" SG_ 754 MessageCounter_IBS3DATA1_2 0;
BA_ "GenSigTimeoutTime_GNMM" SG_ 754 MessageCounter_IBS3DATA1_2 0;
BA_ "GenSigTimeoutTime_EVCU2" SG_ 754 MessageCounter_IBS3DATA1_2 0;
BA_ "GenSigTimeoutTime_ESL" SG_ 754 MessageCounter_IBS3DATA1_2 0;
BA_ "GenSigTimeoutTime_ECM" SG_ 754 MessageCounter_IBS3DATA1_2 0;
BA_ "GenSigTimeoutTime_DTCM" SG_ 754 MessageCounter_IBS3DATA1_2 0;
BA_ "GenSigTimeoutTime_DMSM" SG_ 754 MessageCounter_IBS3DATA1_2 0;
BA_ "GenSigTimeoutTime_BSM" SG_ 754 MessageCounter_IBS3DATA1_2 0;
BA_ "GenSigTimeoutTime_BCM" SG_ 754 MessageCounter_IBS3DATA1_2 0;
BA_ "GenSigTimeoutTime_AGSM" SG_ 754 MessageCounter_IBS3DATA1_2 0;
BA_ "GenSigTimeoutTime_ADCAM" SG_ 754 MessageCounter_IBS3DATA1_2 0;
BA_ "GenSigTimeoutTime_DMSM" SG_ 754 CRC_IBS3DATA1_2 0;
BA_ "GenSigTimeoutTime_BSM" SG_ 754 CRC_IBS3DATA1_2 0;
BA_ "GenSigTimeoutTime_BCM" SG_ 754 CRC_IBS3DATA1_2 0;
BA_ "GenSigTimeoutTime_AGSM" SG_ 754 CRC_IBS3DATA1_2 0;
BA_ "GenSigTimeoutTime_ADCAM" SG_ 754 CRC_IBS3DATA1_2 0;
BA_ "GenSigTimeoutTime_RFHM" SG_ 2654339075 CurrentCanNMState_FD03_IPC 0;
BA_ "GenSigTimeoutTime_MPAD" SG_ 2654339075 CurrentCanNMState_FD03_IPC 0;
BA_ "GenSigTimeoutTime_IPC" SG_ 2654339075 CurrentCanNMState_FD03_IPC 0;
BA_ "GenSigTimeoutTime_GNMM" SG_ 2654339075 CurrentCanNMState_FD03_IPC 0;
BA_ "GenSigTimeoutTime_EVCU2" SG_ 2654339075 CurrentCanNMState_FD03_IPC 0;
BA_ "GenSigTimeoutTime_ESL" SG_ 2654339075 CurrentCanNMState_FD03_IPC 0;
BA_ "GenSigTimeoutTime_ECM" SG_ 2654339075 CurrentCanNMState_FD03_IPC 0;
BA_ "GenSigTimeoutTime_DTCM" SG_ 2654339075 CurrentCanNMState_FD03_IPC 0;
BA_ "GenSigTimeoutTime_DMSM" SG_ 2654339075 CurrentCanNMState_FD03_IPC 0;
BA_ "GenSigTimeoutTime_BSM" SG_ 2654339075 CurrentCanNMState_FD03_IPC 0;
BA_ "GenSigTimeoutTime_BCM" SG_ 2654339075 CurrentCanNMState_FD03_IPC 0;
BA_ "GenSigTimeoutTime_AGSM" SG_ 2654339075 CurrentCanNMState_FD03_IPC 0;
BA_ "GenSigTimeoutTime_ADCAM" SG_ 2654339075 CurrentCanNMState_FD03_IPC 0;
BA_ "GenSigTimeoutTime_DTCM" SG_ 2654339075 CurrentFailSts_FD03_IPC 0;
BA_ "GenSigTimeoutTime_DMSM" SG_ 2654339075 CurrentFailSts_FD03_IPC 0;
BA_ "GenSigTimeoutTime_BSM" SG_ 2654339075 CurrentFailSts_FD03_IPC 0;
BA_ "GenSigTimeoutTime_AGSM" SG_ 2654339075 CurrentFailSts_FD03_IPC 0;
BA_ "GenSigTimeoutTime_ADCAM" SG_ 2654339075 CurrentFailSts_FD03_IPC 0;
BA_ "GenSigTimeoutTime_SGW" SG_ 2651930768 Digit_10_GNMM 0;
BA_ "GenSigTimeoutTime_RFHM" SG_ 2651930768 Digit_10_GNMM 0;
BA_ "GenSigTimeoutTime_MPAD" SG_ 2651930768 Digit_10_GNMM 0;
BA_ "GenSigTimeoutTime_IPC" SG_ 2651930768 Digit_10_GNMM 0;
BA_ "GenSigTimeoutTime_GNMM" SG_ 2651930768 Digit_10_GNMM 0;
BA_ "GenSigTimeoutTime_EVCU2" SG_ 2651930768 Digit_10_GNMM 0;
BA_ "GenSigTimeoutTime_ESL" SG_ 2651930768 Digit_10_GNMM 0;
BA_ "GenSigTimeoutTime_ECM" SG_ 2651930768 Digit_10_GNMM 0;
BA_ "GenSigTimeoutTime_DTCM" SG_ 2651930768 Digit_10_GNMM 0;
BA_ "GenSigTimeoutTime_DMSM" SG_ 2651930768 Digit_10_GNMM 0;
BA_ "GenSigTimeoutTime_BSM" SG_ 2651930768 Digit_10_GNMM 0;
BA_ "GenSigTimeoutTime_AGSM" SG_ 2651930768 Digit_10_GNMM 0;
BA_ "GenSigTimeoutTime_ADCAM" SG_ 2651930768 Digit_10_GNMM 0;
BA_ "GenSigTimeoutTime_SGW" SG_ 2651930768 Digit_11_GNMM 0;
BA_ "GenSigTimeoutTime_RFHM" SG_ 2651930768 Digit_11_GNMM 0;
BA_ "GenSigTimeoutTime_MPAD" SG_ 2651930768 Digit_11_GNMM 0;
BA_ "GenSigTimeoutTime_IPC" SG_ 2651930768 Digit_11_GNMM 0;
BA_ "GenSigTimeoutTime_GNMM" SG_ 2651930768 Digit_11_GNMM 0;
BA_ "GenSigTimeoutTime_EVCU2" SG_ 2651930768 Digit_11_GNMM 0;
BA_ "GenSigTimeoutTime_ESL" SG_ 2651930768 Digit_11_GNMM 0;
BA_ "GenSigTimeoutTime_ECM" SG_ 2651930768 Digit_11_GNMM 0;
BA_ "GenSigTimeoutTime_DTCM" SG_ 2651930768 Digit_11_GNMM 0;
BA_ "GenSigTimeoutTime_DMSM" SG_ 2651930768 Digit_11_GNMM 0;
BA_ "GenSigTimeoutTime_BSM" SG_ 2651930768 Digit_11_GNMM 0;
BA_ "GenSigTimeoutTime_AGSM" SG_ 2651930768 Digit_11_GNMM 0;
BA_ "GenSigTimeoutTime_ADCAM" SG_ 2651930768 Digit_11_GNMM 0;
BA_ "GenSigTimeoutTime_SGW" SG_ 2651930768 Digit_01_GNMM 0;
BA_ "GenSigTimeoutTime_RFHM" SG_ 2651930768 Digit_01_GNMM 0;
BA_ "GenSigTimeoutTime_MPAD" SG_ 2651930768 Digit_01_GNMM 0;
BA_ "GenSigTimeoutTime_IPC" SG_ 2651930768 Digit_01_GNMM 0;
BA_ "GenSigTimeoutTime_GNMM" SG_ 2651930768 Digit_01_GNMM 0;
BA_ "GenSigTimeoutTime_EVCU2" SG_ 2651930768 Digit_01_GNMM 0;
BA_ "GenSigTimeoutTime_ESL" SG_ 2651930768 Digit_01_GNMM 0;
BA_ "GenSigTimeoutTime_ECM" SG_ 2651930768 Digit_01_GNMM 0;
BA_ "GenSigTimeoutTime_DTCM" SG_ 2651930768 Digit_01_GNMM 0;
BA_ "GenSigTimeoutTime_DMSM" SG_ 2651930768 Digit_01_GNMM 0;
BA_ "GenSigTimeoutTime_BSM" SG_ 2651930768 Digit_01_GNMM 0;
BA_ "GenSigTimeoutTime_AGSM" SG_ 2651930768 Digit_01_GNMM 0;
BA_ "GenSigTimeoutTime_ADCAM" SG_ 2651930768 Digit_01_GNMM 0;
BA_ "GenSigSendType" SG_ 2651930768 Digit_01_GNMM 1;
BA_ "GenSigTimeoutTime_SGW" SG_ 2651930768 Digit_02_GNMM 0;
BA_ "GenSigTimeoutTime_RFHM" SG_ 2651930768 Digit_02_GNMM 0;
BA_ "GenSigTimeoutTime_MPAD" SG_ 2651930768 Digit_02_GNMM 0;
BA_ "GenSigTimeoutTime_IPC" SG_ 2651930768 Digit_02_GNMM 0;
BA_ "GenSigTimeoutTime_GNMM" SG_ 2651930768 Digit_02_GNMM 0;
BA_ "GenSigTimeoutTime_EVCU2" SG_ 2651930768 Digit_02_GNMM 0;
BA_ "GenSigTimeoutTime_ESL" SG_ 2651930768 Digit_02_GNMM 0;
BA_ "GenSigTimeoutTime_ECM" SG_ 2651930768 Digit_02_GNMM 0;
BA_ "GenSigTimeoutTime_DTCM" SG_ 2651930768 Digit_02_GNMM 0;
BA_ "GenSigTimeoutTime_DMSM" SG_ 2651930768 Digit_02_GNMM 0;
BA_ "GenSigTimeoutTime_BSM" SG_ 2651930768 Digit_02_GNMM 0;
BA_ "GenSigTimeoutTime_AGSM" SG_ 2651930768 Digit_02_GNMM 0;
BA_ "GenSigTimeoutTime_ADCAM" SG_ 2651930768 Digit_02_GNMM 0;
BA_ "GenSigTimeoutTime_SGW" SG_ 2651930768 Digit_03_GNMM 0;
BA_ "GenSigTimeoutTime_RFHM" SG_ 2651930768 Digit_03_GNMM 0;
BA_ "GenSigTimeoutTime_MPAD" SG_ 2651930768 Digit_03_GNMM 0;
BA_ "GenSigTimeoutTime_IPC" SG_ 2651930768 Digit_03_GNMM 0;
BA_ "GenSigTimeoutTime_GNMM" SG_ 2651930768 Digit_03_GNMM 0;
BA_ "GenSigTimeoutTime_EVCU2" SG_ 2651930768 Digit_03_GNMM 0;
BA_ "GenSigTimeoutTime_ESL" SG_ 2651930768 Digit_03_GNMM 0;
BA_ "GenSigTimeoutTime_ECM" SG_ 2651930768 Digit_03_GNMM 0;
BA_ "GenSigTimeoutTime_DTCM" SG_ 2651930768 Digit_03_GNMM 0;
BA_ "GenSigTimeoutTime_DMSM" SG_ 2651930768 Digit_03_GNMM 0;
BA_ "GenSigTimeoutTime_BSM" SG_ 2651930768 Digit_03_GNMM 0;
BA_ "GenSigTimeoutTime_AGSM" SG_ 2651930768 Digit_03_GNMM 0;
BA_ "GenSigTimeoutTime_ADCAM" SG_ 2651930768 Digit_03_GNMM 0;
BA_ "GenSigTimeoutTime_SGW" SG_ 2651930768 Digit_04_GNMM 0;
BA_ "GenSigTimeoutTime_RFHM" SG_ 2651930768 Digit_04_GNMM 0;
BA_ "GenSigTimeoutTime_MPAD" SG_ 2651930768 Digit_04_GNMM 0;
BA_ "GenSigTimeoutTime_IPC" SG_ 2651930768 Digit_04_GNMM 0;
BA_ "GenSigTimeoutTime_GNMM" SG_ 2651930768 Digit_04_GNMM 0;
BA_ "GenSigTimeoutTime_EVCU2" SG_ 2651930768 Digit_04_GNMM 0;
BA_ "GenSigTimeoutTime_ESL" SG_ 2651930768 Digit_04_GNMM 0;
BA_ "GenSigTimeoutTime_ECM" SG_ 2651930768 Digit_04_GNMM 0;
BA_ "GenSigTimeoutTime_DTCM" SG_ 2651930768 Digit_04_GNMM 0;
BA_ "GenSigTimeoutTime_DMSM" SG_ 2651930768 Digit_04_GNMM 0;
BA_ "GenSigTimeoutTime_BSM" SG_ 2651930768 Digit_04_GNMM 0;
BA_ "GenSigTimeoutTime_AGSM" SG_ 2651930768 Digit_04_GNMM 0;
BA_ "GenSigTimeoutTime_ADCAM" SG_ 2651930768 Digit_04_GNMM 0;
BA_ "GenSigTimeoutTime_SGW" SG_ 2651930768 Digit_05_GNMM 0;
BA_ "GenSigTimeoutTime_RFHM" SG_ 2651930768 Digit_05_GNMM 0;
BA_ "GenSigTimeoutTime_MPAD" SG_ 2651930768 Digit_05_GNMM 0;
BA_ "GenSigTimeoutTime_IPC" SG_ 2651930768 Digit_05_GNMM 0;
BA_ "GenSigTimeoutTime_GNMM" SG_ 2651930768 Digit_05_GNMM 0;
BA_ "GenSigTimeoutTime_EVCU2" SG_ 2651930768 Digit_05_GNMM 0;
BA_ "GenSigTimeoutTime_ESL" SG_ 2651930768 Digit_05_GNMM 0;
BA_ "GenSigTimeoutTime_ECM" SG_ 2651930768 Digit_05_GNMM 0;
BA_ "GenSigTimeoutTime_DTCM" SG_ 2651930768 Digit_05_GNMM 0;
BA_ "GenSigTimeoutTime_DMSM" SG_ 2651930768 Digit_05_GNMM 0;
BA_ "GenSigTimeoutTime_BSM" SG_ 2651930768 Digit_05_GNMM 0;
BA_ "GenSigTimeoutTime_AGSM" SG_ 2651930768 Digit_05_GNMM 0;
BA_ "GenSigTimeoutTime_ADCAM" SG_ 2651930768 Digit_05_GNMM 0;
BA_ "GenSigTimeoutTime_SGW" SG_ 2651930768 Digit_06_GNMM 0;
BA_ "GenSigTimeoutTime_RFHM" SG_ 2651930768 Digit_06_GNMM 0;
BA_ "GenSigTimeoutTime_MPAD" SG_ 2651930768 Digit_06_GNMM 0;
BA_ "GenSigTimeoutTime_IPC" SG_ 2651930768 Digit_06_GNMM 0;
BA_ "GenSigTimeoutTime_GNMM" SG_ 2651930768 Digit_06_GNMM 0;
BA_ "GenSigTimeoutTime_EVCU2" SG_ 2651930768 Digit_06_GNMM 0;
BA_ "GenSigTimeoutTime_ESL" SG_ 2651930768 Digit_06_GNMM 0;
BA_ "GenSigTimeoutTime_ECM" SG_ 2651930768 Digit_06_GNMM 0;
BA_ "GenSigTimeoutTime_DTCM" SG_ 2651930768 Digit_06_GNMM 0;
BA_ "GenSigTimeoutTime_DMSM" SG_ 2651930768 Digit_06_GNMM 0;
BA_ "GenSigTimeoutTime_BSM" SG_ 2651930768 Digit_06_GNMM 0;
BA_ "GenSigTimeoutTime_AGSM" SG_ 2651930768 Digit_06_GNMM 0;
BA_ "GenSigTimeoutTime_ADCAM" SG_ 2651930768 Digit_06_GNMM 0;
BA_ "GenSigTimeoutTime_SGW" SG_ 2651930768 Digit_07_GNMM 0;
BA_ "GenSigTimeoutTime_RFHM" SG_ 2651930768 Digit_07_GNMM 0;
BA_ "GenSigTimeoutTime_MPAD" SG_ 2651930768 Digit_07_GNMM 0;
BA_ "GenSigTimeoutTime_IPC" SG_ 2651930768 Digit_07_GNMM 0;
BA_ "GenSigTimeoutTime_GNMM" SG_ 2651930768 Digit_07_GNMM 0;
BA_ "GenSigTimeoutTime_EVCU2" SG_ 2651930768 Digit_07_GNMM 0;
BA_ "GenSigTimeoutTime_ESL" SG_ 2651930768 Digit_07_GNMM 0;
BA_ "GenSigTimeoutTime_ECM" SG_ 2651930768 Digit_07_GNMM 0;
BA_ "GenSigTimeoutTime_DTCM" SG_ 2651930768 Digit_07_GNMM 0;
BA_ "GenSigTimeoutTime_DMSM" SG_ 2651930768 Digit_07_GNMM 0;
BA_ "GenSigTimeoutTime_BSM" SG_ 2651930768 Digit_07_GNMM 0;
BA_ "GenSigTimeoutTime_AGSM" SG_ 2651930768 Digit_07_GNMM 0;
BA_ "GenSigTimeoutTime_ADCAM" SG_ 2651930768 Digit_07_GNMM 0;
BA_ "GenSigTimeoutTime_SGW" SG_ 2651930768 Digit_08_GNMM 0;
BA_ "GenSigTimeoutTime_RFHM" SG_ 2651930768 Digit_08_GNMM 0;
BA_ "GenSigTimeoutTime_MPAD" SG_ 2651930768 Digit_08_GNMM 0;
BA_ "GenSigTimeoutTime_IPC" SG_ 2651930768 Digit_08_GNMM 0;
BA_ "GenSigTimeoutTime_GNMM" SG_ 2651930768 Digit_08_GNMM 0;
BA_ "GenSigTimeoutTime_EVCU2" SG_ 2651930768 Digit_08_GNMM 0;
BA_ "GenSigTimeoutTime_ESL" SG_ 2651930768 Digit_08_GNMM 0;
BA_ "GenSigTimeoutTime_ECM" SG_ 2651930768 Digit_08_GNMM 0;
BA_ "GenSigTimeoutTime_DTCM" SG_ 2651930768 Digit_08_GNMM 0;
BA_ "GenSigTimeoutTime_DMSM" SG_ 2651930768 Digit_08_GNMM 0;
BA_ "GenSigTimeoutTime_BSM" SG_ 2651930768 Digit_08_GNMM 0;
BA_ "GenSigTimeoutTime_AGSM" SG_ 2651930768 Digit_08_GNMM 0;
BA_ "GenSigTimeoutTime_ADCAM" SG_ 2651930768 Digit_08_GNMM 0;
BA_ "GenSigTimeoutTime_SGW" SG_ 2651930768 Digit_09_GNMM 0;
BA_ "GenSigTimeoutTime_RFHM" SG_ 2651930768 Digit_09_GNMM 0;
BA_ "GenSigTimeoutTime_MPAD" SG_ 2651930768 Digit_09_GNMM 0;
BA_ "GenSigTimeoutTime_IPC" SG_ 2651930768 Digit_09_GNMM 0;
BA_ "GenSigTimeoutTime_GNMM" SG_ 2651930768 Digit_09_GNMM 0;
BA_ "GenSigTimeoutTime_EVCU2" SG_ 2651930768 Digit_09_GNMM 0;
BA_ "GenSigTimeoutTime_ESL" SG_ 2651930768 Digit_09_GNMM 0;
BA_ "GenSigTimeoutTime_ECM" SG_ 2651930768 Digit_09_GNMM 0;
BA_ "GenSigTimeoutTime_DTCM" SG_ 2651930768 Digit_09_GNMM 0;
BA_ "GenSigTimeoutTime_DMSM" SG_ 2651930768 Digit_09_GNMM 0;
BA_ "GenSigTimeoutTime_BSM" SG_ 2651930768 Digit_09_GNMM 0;
BA_ "GenSigTimeoutTime_AGSM" SG_ 2651930768 Digit_09_GNMM 0;
BA_ "GenSigTimeoutTime_ADCAM" SG_ 2651930768 Digit_09_GNMM 0;
BA_ "GenSigTimeoutTime_RFHM" SG_ 2654339216 CurrentCanNMState_FD03_GNMM 0;
BA_ "GenSigTimeoutTime_MPAD" SG_ 2654339216 CurrentCanNMState_FD03_GNMM 0;
BA_ "GenSigTimeoutTime_IPC" SG_ 2654339216 CurrentCanNMState_FD03_GNMM 0;
BA_ "GenSigTimeoutTime_GNMM" SG_ 2654339216 CurrentCanNMState_FD03_GNMM 0;
BA_ "GenSigTimeoutTime_EVCU2" SG_ 2654339216 CurrentCanNMState_FD03_GNMM 0;
BA_ "GenSigTimeoutTime_ESL" SG_ 2654339216 CurrentCanNMState_FD03_GNMM 0;
BA_ "GenSigTimeoutTime_ECM" SG_ 2654339216 CurrentCanNMState_FD03_GNMM 0;
BA_ "GenSigTimeoutTime_DTCM" SG_ 2654339216 CurrentCanNMState_FD03_GNMM 0;
BA_ "GenSigTimeoutTime_DMSM" SG_ 2654339216 CurrentCanNMState_FD03_GNMM 0;
BA_ "GenSigTimeoutTime_BSM" SG_ 2654339216 CurrentCanNMState_FD03_GNMM 0;
BA_ "GenSigTimeoutTime_BCM" SG_ 2654339216 CurrentCanNMState_FD03_GNMM 0;
BA_ "GenSigTimeoutTime_AGSM" SG_ 2654339216 CurrentCanNMState_FD03_GNMM 0;
BA_ "GenSigTimeoutTime_ADCAM" SG_ 2654339216 CurrentCanNMState_FD03_GNMM 0;
BA_ "GenSigTimeoutTime_SGW" SG_ 2654339108 CurrentCanNMState_FD08_ETM 0;
BA_ "GenSigTimeoutTime_RFHM" SG_ 2654339108 CurrentCanNMState_FD08_ETM 0;
BA_ "GenSigTimeoutTime_MPAD" SG_ 2654339108 CurrentCanNMState_FD08_ETM 0;
BA_ "GenSigTimeoutTime_IPC" SG_ 2654339108 CurrentCanNMState_FD08_ETM 0;
BA_ "GenSigTimeoutTime_GNMM" SG_ 2654339108 CurrentCanNMState_FD08_ETM 0;
BA_ "GenSigTimeoutTime_EVCU2" SG_ 2654339108 CurrentCanNMState_FD08_ETM 0;
BA_ "GenSigTimeoutTime_ESL" SG_ 2654339108 CurrentCanNMState_FD08_ETM 0;
BA_ "GenSigTimeoutTime_ECM" SG_ 2654339108 CurrentCanNMState_FD08_ETM 0;
BA_ "GenSigTimeoutTime_DTCM" SG_ 2654339108 CurrentCanNMState_FD08_ETM 0;
BA_ "GenSigTimeoutTime_DMSM" SG_ 2654339108 CurrentCanNMState_FD08_ETM 0;
BA_ "GenSigTimeoutTime_BSM" SG_ 2654339108 CurrentCanNMState_FD08_ETM 0;
BA_ "GenSigTimeoutTime_BCM" SG_ 2654339108 CurrentCanNMState_FD08_ETM 0;
BA_ "GenSigTimeoutTime_AGSM" SG_ 2654339108 CurrentCanNMState_FD08_ETM 0;
BA_ "GenSigTimeoutTime_ADCAM" SG_ 2654339108 CurrentCanNMState_FD08_ETM 0;
BA_ "GenSigTimeoutTime_RFHM" SG_ 2654339093 WakeupSource_FD03_ESL 0;
BA_ "GenSigTimeoutTime_MPAD" SG_ 2654339093 WakeupSource_FD03_ESL 0;
BA_ "GenSigTimeoutTime_IPC" SG_ 2654339093 WakeupSource_FD03_ESL 0;
BA_ "GenSigTimeoutTime_GNMM" SG_ 2654339093 WakeupSource_FD03_ESL 0;
BA_ "GenSigTimeoutTime_EVCU2" SG_ 2654339093 WakeupSource_FD03_ESL 0;
BA_ "GenSigTimeoutTime_ESL" SG_ 2654339093 WakeupSource_FD03_ESL 0;
BA_ "GenSigTimeoutTime_ECM" SG_ 2654339093 WakeupSource_FD03_ESL 0;
BA_ "GenSigTimeoutTime_DTCM" SG_ 2654339093 WakeupSource_FD03_ESL 0;
BA_ "GenSigTimeoutTime_DMSM" SG_ 2654339093 WakeupSource_FD03_ESL 0;
BA_ "GenSigTimeoutTime_BSM" SG_ 2654339093 WakeupSource_FD03_ESL 0;
BA_ "GenSigTimeoutTime_BCM" SG_ 2654339093 WakeupSource_FD03_ESL 0;
BA_ "GenSigTimeoutTime_AGSM" SG_ 2654339093 WakeupSource_FD03_ESL 0;
BA_ "GenSigTimeoutTime_RFHM" SG_ 2654339216 CurrentFailSts_FD03_GNMM 0;
BA_ "GenSigTimeoutTime_MPAD" SG_ 2654339216 CurrentFailSts_FD03_GNMM 0;
BA_ "GenSigTimeoutTime_IPC" SG_ 2654339216 CurrentFailSts_FD03_GNMM 0;
BA_ "GenSigTimeoutTime_GNMM" SG_ 2654339216 CurrentFailSts_FD03_GNMM 0;
BA_ "GenSigTimeoutTime_EVCU2" SG_ 2654339216 CurrentFailSts_FD03_GNMM 0;
BA_ "GenSigTimeoutTime_ESL" SG_ 2654339216 CurrentFailSts_FD03_GNMM 0;
BA_ "GenSigTimeoutTime_ECM" SG_ 2654339216 CurrentFailSts_FD03_GNMM 0;
BA_ "GenSigTimeoutTime_DTCM" SG_ 2654339216 CurrentFailSts_FD03_GNMM 0;
BA_ "GenSigTimeoutTime_DMSM" SG_ 2654339216 CurrentFailSts_FD03_GNMM 0;
BA_ "GenSigTimeoutTime_BSM" SG_ 2654339216 CurrentFailSts_FD03_GNMM 0;
BA_ "GenSigTimeoutTime_AGSM" SG_ 2654339216 CurrentFailSts_FD03_GNMM 0;
BA_ "GenSigTimeoutTime_ADCAM" SG_ 2654339216 CurrentFailSts_FD03_GNMM 0;
BA_ "GenSigTimeoutTime_DTCM" SG_ 2654339216 DES_FD03_GNMM 0;
BA_ "GenSigTimeoutTime_DMSM" SG_ 2654339216 DES_FD03_GNMM 0;
BA_ "GenSigTimeoutTime_BSM" SG_ 2654339216 DES_FD03_GNMM 0;
BA_ "GenSigTimeoutTime_BCM" SG_ 2654339216 DES_FD03_GNMM 0;
BA_ "GenSigTimeoutTime_AGSM" SG_ 2654339216 DES_FD03_GNMM 0;
BA_ "GenSigTimeoutTime_ADCAM" SG_ 2654339216 DES_FD03_GNMM 0;
BA_ "GenSigTimeoutTime_DMSM" SG_ 2654339108 EOL_FD08_ETM 0;
BA_ "GenSigTimeoutTime_BSM" SG_ 2654339108 EOL_FD08_ETM 0;
BA_ "GenSigTimeoutTime_AGSM" SG_ 2654339108 EOL_FD08_ETM 0;
BA_ "GenSigTimeoutTime_ADCAM" SG_ 2654339108 EOL_FD08_ETM 0;
BA_ "GenSigTimeoutTime_RFHM" SG_ 2654339108 CurrentFailSts_FD08_ETM 0;
BA_ "GenSigTimeoutTime_MPAD" SG_ 2654339108 CurrentFailSts_FD08_ETM 0;
BA_ "GenSigTimeoutTime_IPC" SG_ 2654339108 CurrentFailSts_FD08_ETM 0;
BA_ "GenSigTimeoutTime_GNMM" SG_ 2654339108 CurrentFailSts_FD08_ETM 0;
BA_ "GenSigTimeoutTime_EVCU2" SG_ 2654339108 CurrentFailSts_FD08_ETM 0;
BA_ "GenSigTimeoutTime_ESL" SG_ 2654339108 CurrentFailSts_FD08_ETM 0;
BA_ "GenSigTimeoutTime_ECM" SG_ 2654339108 CurrentFailSts_FD08_ETM 0;
BA_ "GenSigTimeoutTime_DTCM" SG_ 2654339108 CurrentFailSts_FD08_ETM 0;
BA_ "GenSigTimeoutTime_DMSM" SG_ 2654339108 CurrentFailSts_FD08_ETM 0;
BA_ "GenSigTimeoutTime_BSM" SG_ 2654339108 CurrentFailSts_FD08_ETM 0;
BA_ "GenSigTimeoutTime_AGSM" SG_ 2654339108 CurrentFailSts_FD08_ETM 0;
BA_ "GenSigTimeoutTime_ADCAM" SG_ 2654339108 CurrentFailSts_FD08_ETM 0;
BA_ "GenSigTimeoutTime_SGW" SG_ 524 CRC_BRAKE2_2 0;
BA_ "GenSigTimeoutTime_RFHM" SG_ 524 CRC_BRAKE2_2 0;
BA_ "GenSigTimeoutTime_MPAD" SG_ 524 CRC_BRAKE2_2 0;
BA_ "GenSigTimeoutTime_IPC" SG_ 524 CRC_BRAKE2_2 0;
BA_ "GenSigTimeoutTime_GNMM" SG_ 524 CRC_BRAKE2_2 0;
BA_ "GenSigTimeoutTime_EVCU2" SG_ 524 CRC_BRAKE2_2 0;
BA_ "GenSigTimeoutTime_ESL" SG_ 524 CRC_BRAKE2_2 0;
BA_ "GenSigTimeoutTime_ECM" SG_ 524 CRC_BRAKE2_2 0;
BA_ "GenSigTimeoutTime_DTCM" SG_ 524 CRC_BRAKE2_2 0;
BA_ "GenSigTimeoutTime_DMSM" SG_ 524 CRC_BRAKE2_2 0;
BA_ "GenSigTimeoutTime_BCM" SG_ 524 CRC_BRAKE2_2 0;
BA_ "GenSigTimeoutTime_AGSM" SG_ 524 CRC_BRAKE2_2 0;
BA_ "GenSigTimeoutTime_ADCAM" SG_ 524 CRC_BRAKE2_2 0;
BA_ "GenSigTimeoutTime_SGW" SG_ 524 MessageCounter_BRAKE2_2 0;
BA_ "GenSigTimeoutTime_RFHM" SG_ 524 MessageCounter_BRAKE2_2 0;
BA_ "GenSigTimeoutTime_MPAD" SG_ 524 MessageCounter_BRAKE2_2 0;
BA_ "GenSigTimeoutTime_IPC" SG_ 524 MessageCounter_BRAKE2_2 0;
BA_ "GenSigTimeoutTime_GNMM" SG_ 524 MessageCounter_BRAKE2_2 0;
BA_ "GenSigTimeoutTime_EVCU2" SG_ 524 MessageCounter_BRAKE2_2 0;
BA_ "GenSigTimeoutTime_ESL" SG_ 524 MessageCounter_BRAKE2_2 0;
BA_ "GenSigTimeoutTime_ECM" SG_ 524 MessageCounter_BRAKE2_2 0;
BA_ "GenSigTimeoutTime_DTCM" SG_ 524 MessageCounter_BRAKE2_2 0;
BA_ "GenSigTimeoutTime_DMSM" SG_ 524 MessageCounter_BRAKE2_2 0;
BA_ "GenSigTimeoutTime_BCM" SG_ 524 MessageCounter_BRAKE2_2 0;
BA_ "GenSigTimeoutTime_AGSM" SG_ 524 MessageCounter_BRAKE2_2 0;
BA_ "GenSigTimeoutTime_ADCAM" SG_ 524 MessageCounter_BRAKE2_2 0;
BA_ "GenSigTimeoutTime_SGW" SG_ 524 Brake_OpStat_Sec 0;
BA_ "GenSigTimeoutTime_RFHM" SG_ 524 Brake_OpStat_Sec 0;
BA_ "GenSigTimeoutTime_IPC" SG_ 524 Brake_OpStat_Sec 0;
BA_ "GenSigTimeoutTime_GNMM" SG_ 524 Brake_OpStat_Sec 0;
BA_ "GenSigTimeoutTime_EVCU2" SG_ 524 Brake_OpStat_Sec 0;
BA_ "GenSigTimeoutTime_ESL" SG_ 524 Brake_OpStat_Sec 0;
BA_ "GenSigTimeoutTime_ECM" SG_ 524 Brake_OpStat_Sec 0;
BA_ "GenSigTimeoutTime_DTCM" SG_ 524 Brake_OpStat_Sec 0;
BA_ "GenSigTimeoutTime_DMSM" SG_ 524 Brake_OpStat_Sec 0;
BA_ "GenSigTimeoutTime_BSM" SG_ 524 Brake_OpStat_Sec 0;
BA_ "GenSigTimeoutTime_BCM" SG_ 524 Brake_OpStat_Sec 0;
BA_ "GenSigTimeoutTime_AGSM" SG_ 524 Brake_OpStat_Sec 0;
BA_ "GenSigTimeoutTime_ADCAM" SG_ 524 Brake_OpStat_Sec 0;
BA_ "GenSigTimeoutTime_SGW" SG_ 524 BSM2_OpStat 0;
BA_ "GenSigTimeoutTime_RFHM" SG_ 524 BSM2_OpStat 0;
BA_ "GenSigTimeoutTime_IPC" SG_ 524 BSM2_OpStat 0;
BA_ "GenSigTimeoutTime_GNMM" SG_ 524 BSM2_OpStat 0;
BA_ "GenSigTimeoutTime_EVCU2" SG_ 524 BSM2_OpStat 0;
BA_ "GenSigTimeoutTime_ESL" SG_ 524 BSM2_OpStat 0;
BA_ "GenSigTimeoutTime_ECM" SG_ 524 BSM2_OpStat 0;
BA_ "GenSigTimeoutTime_DTCM" SG_ 524 BSM2_OpStat 0;
BA_ "GenSigTimeoutTime_DMSM" SG_ 524 BSM2_OpStat 0;
BA_ "GenSigTimeoutTime_BCM" SG_ 524 BSM2_OpStat 0;
BA_ "GenSigTimeoutTime_AGSM" SG_ 524 BSM2_OpStat 0;
BA_ "GenSigTimeoutTime_ADCAM" SG_ 524 BSM2_OpStat 0;
BA_ "GenSigTimeoutTime_SGW" SG_ 524 VehicleStandStillSts_B2 0;
BA_ "GenSigTimeoutTime_RFHM" SG_ 524 VehicleStandStillSts_B2 0;
BA_ "GenSigTimeoutTime_IPC" SG_ 524 VehicleStandStillSts_B2 0;
BA_ "GenSigTimeoutTime_GNMM" SG_ 524 VehicleStandStillSts_B2 0;
BA_ "GenSigTimeoutTime_EVCU2" SG_ 524 VehicleStandStillSts_B2 0;
BA_ "GenSigTimeoutTime_ESL" SG_ 524 VehicleStandStillSts_B2 0;
BA_ "GenSigTimeoutTime_ECM" SG_ 524 VehicleStandStillSts_B2 0;
BA_ "GenSigTimeoutTime_DTCM" SG_ 524 VehicleStandStillSts_B2 0;
BA_ "GenSigTimeoutTime_DMSM" SG_ 524 VehicleStandStillSts_B2 0;
BA_ "GenSigTimeoutTime_BSM" SG_ 524 VehicleStandStillSts_B2 0;
BA_ "GenSigTimeoutTime_BCM" SG_ 524 VehicleStandStillSts_B2 0;
BA_ "GenSigTimeoutTime_AGSM" SG_ 524 VehicleStandStillSts_B2 0;
BA_ "GenSigTimeoutTime_ADCAM" SG_ 524 VehicleStandStillSts_B2 0;
BA_ "GenSigStartValue" SG_ 524 VehicleStandStillSts_B2 1;
BA_ "GenSigTimeoutTime_SGW" SG_ 257 Ft_RrAxleCoupling_TrqRq_B2 0;
BA_ "GenSigTimeoutTime_RFHM" SG_ 257 Ft_RrAxleCoupling_TrqRq_B2 0;
BA_ "GenSigTimeoutTime_MPAD" SG_ 257 Ft_RrAxleCoupling_TrqRq_B2 0;
BA_ "GenSigTimeoutTime_IPC" SG_ 257 Ft_RrAxleCoupling_TrqRq_B2 0;
BA_ "GenSigTimeoutTime_GNMM" SG_ 257 Ft_RrAxleCoupling_TrqRq_B2 0;
BA_ "GenSigTimeoutTime_EVCU2" SG_ 257 Ft_RrAxleCoupling_TrqRq_B2 0;
BA_ "GenSigTimeoutTime_ESL" SG_ 257 Ft_RrAxleCoupling_TrqRq_B2 0;
BA_ "GenSigTimeoutTime_ECM" SG_ 257 Ft_RrAxleCoupling_TrqRq_B2 0;
BA_ "GenSigTimeoutTime_DMSM" SG_ 257 Ft_RrAxleCoupling_TrqRq_B2 0;
BA_ "GenSigTimeoutTime_BSM" SG_ 257 Ft_RrAxleCoupling_TrqRq_B2 0;
BA_ "GenSigTimeoutTime_BCM" SG_ 257 Ft_RrAxleCoupling_TrqRq_B2 0;
BA_ "GenSigTimeoutTime_AGSM" SG_ 257 Ft_RrAxleCoupling_TrqRq_B2 0;
BA_ "GenSigTimeoutTime_ADCAM" SG_ 257 Ft_RrAxleCoupling_TrqRq_B2 0;
BA_ "GenSigStartValue" SG_ 257 Ft_RrAxleCoupling_TrqRq_B2 254;
BA_ "GenSigTimeoutTime_SGW" SG_ 257 Ft_RrTrqCoupling_ModeRq_B2 0;
BA_ "GenSigTimeoutTime_RFHM" SG_ 257 Ft_RrTrqCoupling_ModeRq_B2 0;
BA_ "GenSigTimeoutTime_MPAD" SG_ 257 Ft_RrTrqCoupling_ModeRq_B2 0;
BA_ "GenSigTimeoutTime_IPC" SG_ 257 Ft_RrTrqCoupling_ModeRq_B2 0;
BA_ "GenSigTimeoutTime_GNMM" SG_ 257 Ft_RrTrqCoupling_ModeRq_B2 0;
BA_ "GenSigTimeoutTime_EVCU2" SG_ 257 Ft_RrTrqCoupling_ModeRq_B2 0;
BA_ "GenSigTimeoutTime_ESL" SG_ 257 Ft_RrTrqCoupling_ModeRq_B2 0;
BA_ "GenSigTimeoutTime_ECM" SG_ 257 Ft_RrTrqCoupling_ModeRq_B2 0;
BA_ "GenSigTimeoutTime_DMSM" SG_ 257 Ft_RrTrqCoupling_ModeRq_B2 0;
BA_ "GenSigTimeoutTime_BSM" SG_ 257 Ft_RrTrqCoupling_ModeRq_B2 0;
BA_ "GenSigTimeoutTime_BCM" SG_ 257 Ft_RrTrqCoupling_ModeRq_B2 0;
BA_ "GenSigTimeoutTime_AGSM" SG_ 257 Ft_RrTrqCoupling_ModeRq_B2 0;
BA_ "GenSigTimeoutTime_ADCAM" SG_ 257 Ft_RrTrqCoupling_ModeRq_B2 0;
BA_ "GenSigTimeoutTime_SGW" SG_ 2654339199 StayActiveSource_FD08_VRM 0;
BA_ "GenSigTimeoutTime_RFHM" SG_ 2654339199 StayActiveSource_FD08_VRM 0;
BA_ "GenSigTimeoutTime_MPAD" SG_ 2654339199 StayActiveSource_FD08_VRM 0;
BA_ "GenSigTimeoutTime_IPC" SG_ 2654339199 StayActiveSource_FD08_VRM 0;
BA_ "GenSigTimeoutTime_GNMM" SG_ 2654339199 StayActiveSource_FD08_VRM 0;
BA_ "GenSigTimeoutTime_EVCU2" SG_ 2654339199 StayActiveSource_FD08_VRM 0;
BA_ "GenSigTimeoutTime_ESL" SG_ 2654339199 StayActiveSource_FD08_VRM 0;
BA_ "GenSigTimeoutTime_ECM" SG_ 2654339199 StayActiveSource_FD08_VRM 0;
BA_ "GenSigTimeoutTime_DTCM" SG_ 2654339199 StayActiveSource_FD08_VRM 0;
BA_ "GenSigTimeoutTime_DMSM" SG_ 2654339199 StayActiveSource_FD08_VRM 0;
BA_ "GenSigTimeoutTime_BSM" SG_ 2654339199 StayActiveSource_FD08_VRM 0;
BA_ "GenSigTimeoutTime_BCM" SG_ 2654339199 StayActiveSource_FD08_VRM 0;
BA_ "GenSigTimeoutTime_AGSM" SG_ 2654339199 StayActiveSource_FD08_VRM 0;
BA_ "GenSigTimeoutTime_ADCAM" SG_ 2654339199 StayActiveSource_FD08_VRM 0;
BA_ "GenSigTimeoutTime_SGW" SG_ 2654339199 WakeupSource_FD08_VRM 0;
BA_ "GenSigTimeoutTime_RFHM" SG_ 2654339199 WakeupSource_FD08_VRM 0;
BA_ "GenSigTimeoutTime_MPAD" SG_ 2654339199 WakeupSource_FD08_VRM 0;
BA_ "GenSigTimeoutTime_IPC" SG_ 2654339199 WakeupSource_FD08_VRM 0;
BA_ "GenSigTimeoutTime_GNMM" SG_ 2654339199 WakeupSource_FD08_VRM 0;
BA_ "GenSigTimeoutTime_EVCU2" SG_ 2654339199 WakeupSource_FD08_VRM 0;
BA_ "GenSigTimeoutTime_ESL" SG_ 2654339199 WakeupSource_FD08_VRM 0;
BA_ "GenSigTimeoutTime_ECM" SG_ 2654339199 WakeupSource_FD08_VRM 0;
BA_ "GenSigTimeoutTime_DTCM" SG_ 2654339199 WakeupSource_FD08_VRM 0;
BA_ "GenSigTimeoutTime_DMSM" SG_ 2654339199 WakeupSource_FD08_VRM 0;
BA_ "GenSigTimeoutTime_BSM" SG_ 2654339199 WakeupSource_FD08_VRM 0;
BA_ "GenSigTimeoutTime_BCM" SG_ 2654339199 WakeupSource_FD08_VRM 0;
BA_ "GenSigTimeoutTime_AGSM" SG_ 2654339199 WakeupSource_FD08_VRM 0;
BA_ "GenSigTimeoutTime_ADCAM" SG_ 2654339199 WakeupSource_FD08_VRM 0;
BA_ "GenSigTimeoutTime_SGW" SG_ 2654339199 PreviousCanNMState_FD08_VRM 0;
BA_ "GenSigTimeoutTime_RFHM" SG_ 2654339199 PreviousCanNMState_FD08_VRM 0;
BA_ "GenSigTimeoutTime_MPAD" SG_ 2654339199 PreviousCanNMState_FD08_VRM 0;
BA_ "GenSigTimeoutTime_IPC" SG_ 2654339199 PreviousCanNMState_FD08_VRM 0;
BA_ "GenSigTimeoutTime_GNMM" SG_ 2654339199 PreviousCanNMState_FD08_VRM 0;
BA_ "GenSigTimeoutTime_EVCU2" SG_ 2654339199 PreviousCanNMState_FD08_VRM 0;
BA_ "GenSigTimeoutTime_ESL" SG_ 2654339199 PreviousCanNMState_FD08_VRM 0;
BA_ "GenSigTimeoutTime_ECM" SG_ 2654339199 PreviousCanNMState_FD08_VRM 0;
BA_ "GenSigTimeoutTime_DTCM" SG_ 2654339199 PreviousCanNMState_FD08_VRM 0;
BA_ "GenSigTimeoutTime_DMSM" SG_ 2654339199 PreviousCanNMState_FD08_VRM 0;
BA_ "GenSigTimeoutTime_BSM" SG_ 2654339199 PreviousCanNMState_FD08_VRM 0;
BA_ "GenSigTimeoutTime_BCM" SG_ 2654339199 PreviousCanNMState_FD08_VRM 0;
BA_ "GenSigTimeoutTime_AGSM" SG_ 2654339199 PreviousCanNMState_FD08_VRM 0;
BA_ "GenSigTimeoutTime_ADCAM" SG_ 2654339199 PreviousCanNMState_FD08_VRM 0;
BA_ "GenSigTimeoutTime_SGW" SG_ 2654339199 DES_FD08_VRM 0;
BA_ "GenSigTimeoutTime_RFHM" SG_ 2654339199 DES_FD08_VRM 0;
BA_ "GenSigTimeoutTime_MPAD" SG_ 2654339199 DES_FD08_VRM 0;
BA_ "GenSigTimeoutTime_IPC" SG_ 2654339199 DES_FD08_VRM 0;
BA_ "GenSigTimeoutTime_GNMM" SG_ 2654339199 DES_FD08_VRM 0;
BA_ "GenSigTimeoutTime_EVCU2" SG_ 2654339199 DES_FD08_VRM 0;
BA_ "GenSigTimeoutTime_ESL" SG_ 2654339199 DES_FD08_VRM 0;
BA_ "GenSigTimeoutTime_ECM" SG_ 2654339199 DES_FD08_VRM 0;
BA_ "GenSigTimeoutTime_DTCM" SG_ 2654339199 DES_FD08_VRM 0;
BA_ "GenSigTimeoutTime_DMSM" SG_ 2654339199 DES_FD08_VRM 0;
BA_ "GenSigTimeoutTime_BSM" SG_ 2654339199 DES_FD08_VRM 0;
BA_ "GenSigTimeoutTime_BCM" SG_ 2654339199 DES_FD08_VRM 0;
BA_ "GenSigTimeoutTime_AGSM" SG_ 2654339199 DES_FD08_VRM 0;
BA_ "GenSigTimeoutTime_ADCAM" SG_ 2654339199 DES_FD08_VRM 0;
BA_ "GenSigTimeoutTime_SGW" SG_ 2654339199 CurrentCanNMState_FD08_VRM 0;
BA_ "GenSigTimeoutTime_RFHM" SG_ 2654339199 CurrentCanNMState_FD08_VRM 0;
BA_ "GenSigTimeoutTime_MPAD" SG_ 2654339199 CurrentCanNMState_FD08_VRM 0;
BA_ "GenSigTimeoutTime_IPC" SG_ 2654339199 CurrentCanNMState_FD08_VRM 0;
BA_ "GenSigTimeoutTime_GNMM" SG_ 2654339199 CurrentCanNMState_FD08_VRM 0;
BA_ "GenSigTimeoutTime_EVCU2" SG_ 2654339199 CurrentCanNMState_FD08_VRM 0;
BA_ "GenSigTimeoutTime_ESL" SG_ 2654339199 CurrentCanNMState_FD08_VRM 0;
BA_ "GenSigTimeoutTime_ECM" SG_ 2654339199 CurrentCanNMState_FD08_VRM 0;
BA_ "GenSigTimeoutTime_DTCM" SG_ 2654339199 CurrentCanNMState_FD08_VRM 0;
BA_ "GenSigTimeoutTime_DMSM" SG_ 2654339199 CurrentCanNMState_FD08_VRM 0;
BA_ "GenSigTimeoutTime_BSM" SG_ 2654339199 CurrentCanNMState_FD08_VRM 0;
BA_ "GenSigTimeoutTime_BCM" SG_ 2654339199 CurrentCanNMState_FD08_VRM 0;
BA_ "GenSigTimeoutTime_AGSM" SG_ 2654339199 CurrentCanNMState_FD08_VRM 0;
BA_ "GenSigTimeoutTime_ADCAM" SG_ 2654339199 CurrentCanNMState_FD08_VRM 0;
BA_ "GenSigTimeoutTime_SGW" SG_ 2654339107 WakeupSource_FD08_TBM 0;
BA_ "GenSigTimeoutTime_RFHM" SG_ 2654339107 WakeupSource_FD08_TBM 0;
BA_ "GenSigTimeoutTime_MPAD" SG_ 2654339107 WakeupSource_FD08_TBM 0;
BA_ "GenSigTimeoutTime_IPC" SG_ 2654339107 WakeupSource_FD08_TBM 0;
BA_ "GenSigTimeoutTime_GNMM" SG_ 2654339107 WakeupSource_FD08_TBM 0;
BA_ "GenSigTimeoutTime_EVCU2" SG_ 2654339107 WakeupSource_FD08_TBM 0;
BA_ "GenSigTimeoutTime_ESL" SG_ 2654339107 WakeupSource_FD08_TBM 0;
BA_ "GenSigTimeoutTime_ECM" SG_ 2654339107 WakeupSource_FD08_TBM 0;
BA_ "GenSigTimeoutTime_DTCM" SG_ 2654339107 WakeupSource_FD08_TBM 0;
BA_ "GenSigTimeoutTime_DMSM" SG_ 2654339107 WakeupSource_FD08_TBM 0;
BA_ "GenSigTimeoutTime_BSM" SG_ 2654339107 WakeupSource_FD08_TBM 0;
BA_ "GenSigTimeoutTime_BCM" SG_ 2654339107 WakeupSource_FD08_TBM 0;
BA_ "GenSigTimeoutTime_AGSM" SG_ 2654339107 WakeupSource_FD08_TBM 0;
BA_ "GenSigTimeoutTime_ADCAM" SG_ 2654339107 WakeupSource_FD08_TBM 0;
BA_ "GenSigTimeoutTime_SGW" SG_ 2654339107 PreviousCanNMState_FD08_TBM 0;
BA_ "GenSigTimeoutTime_RFHM" SG_ 2654339107 PreviousCanNMState_FD08_TBM 0;
BA_ "GenSigTimeoutTime_MPAD" SG_ 2654339107 PreviousCanNMState_FD08_TBM 0;
BA_ "GenSigTimeoutTime_IPC" SG_ 2654339107 PreviousCanNMState_FD08_TBM 0;
BA_ "GenSigTimeoutTime_GNMM" SG_ 2654339107 PreviousCanNMState_FD08_TBM 0;
BA_ "GenSigTimeoutTime_EVCU2" SG_ 2654339107 PreviousCanNMState_FD08_TBM 0;
BA_ "GenSigTimeoutTime_ESL" SG_ 2654339107 PreviousCanNMState_FD08_TBM 0;
BA_ "GenSigTimeoutTime_ECM" SG_ 2654339107 PreviousCanNMState_FD08_TBM 0;
BA_ "GenSigTimeoutTime_DTCM" SG_ 2654339107 PreviousCanNMState_FD08_TBM 0;
BA_ "GenSigTimeoutTime_DMSM" SG_ 2654339107 PreviousCanNMState_FD08_TBM 0;
BA_ "GenSigTimeoutTime_BSM" SG_ 2654339107 PreviousCanNMState_FD08_TBM 0;
BA_ "GenSigTimeoutTime_BCM" SG_ 2654339107 PreviousCanNMState_FD08_TBM 0;
BA_ "GenSigTimeoutTime_AGSM" SG_ 2654339107 PreviousCanNMState_FD08_TBM 0;
BA_ "GenSigTimeoutTime_ADCAM" SG_ 2654339107 PreviousCanNMState_FD08_TBM 0;
BA_ "GenSigTimeoutTime_MPAD" SG_ 2654339107 StayActiveSource_FD08_TBM 0;
BA_ "GenSigTimeoutTime_IPC" SG_ 2654339107 StayActiveSource_FD08_TBM 0;
BA_ "GenSigTimeoutTime_GNMM" SG_ 2654339107 StayActiveSource_FD08_TBM 0;
BA_ "GenSigTimeoutTime_EVCU2" SG_ 2654339107 StayActiveSource_FD08_TBM 0;
BA_ "GenSigTimeoutTime_ESL" SG_ 2654339107 StayActiveSource_FD08_TBM 0;
BA_ "GenSigTimeoutTime_ECM" SG_ 2654339107 StayActiveSource_FD08_TBM 0;
BA_ "GenSigTimeoutTime_DTCM" SG_ 2654339107 StayActiveSource_FD08_TBM 0;
BA_ "GenSigTimeoutTime_DMSM" SG_ 2654339107 StayActiveSource_FD08_TBM 0;
BA_ "GenSigTimeoutTime_BSM" SG_ 2654339107 StayActiveSource_FD08_TBM 0;
BA_ "GenSigTimeoutTime_BCM" SG_ 2654339107 StayActiveSource_FD08_TBM 0;
BA_ "GenSigTimeoutTime_AGSM" SG_ 2654339107 StayActiveSource_FD08_TBM 0;
BA_ "GenSigTimeoutTime_ADCAM" SG_ 2654339107 StayActiveSource_FD08_TBM 0;
BA_ "GenSigTimeoutTime_SGW" SG_ 2654339107 StayActiveSource_FD08_TBM 0;
BA_ "GenSigTimeoutTime_RFHM" SG_ 2654339107 StayActiveSource_FD08_TBM 0;
BA_ "GenSigTimeoutTime_SGW" SG_ 1460 MPFC_Big_ECU_Package 0;
BA_ "GenSigTimeoutTime_RFHM" SG_ 1460 MPFC_Big_ECU_Package 0;
BA_ "GenSigTimeoutTime_IPC" SG_ 1460 MPFC_Big_ECU_Package 0;
BA_ "GenSigTimeoutTime_GNMM" SG_ 1460 MPFC_Big_ECU_Package 0;
BA_ "GenSigTimeoutTime_EVCU2" SG_ 1460 MPFC_Big_ECU_Package 0;
BA_ "GenSigTimeoutTime_ESL" SG_ 1460 MPFC_Big_ECU_Package 0;
BA_ "GenSigTimeoutTime_ECM" SG_ 1460 MPFC_Big_ECU_Package 0;
BA_ "GenSigTimeoutTime_DTCM" SG_ 1460 MPFC_Big_ECU_Package 0;
BA_ "GenSigTimeoutTime_DMSM" SG_ 1460 MPFC_Big_ECU_Package 0;
BA_ "GenSigTimeoutTime_BSM" SG_ 1460 MPFC_Big_ECU_Package 0;
BA_ "GenSigTimeoutTime_BCM" SG_ 1460 MPFC_Big_ECU_Package 0;
BA_ "GenSigTimeoutTime_AGSM" SG_ 1460 MPFC_Big_ECU_Package 0;
BA_ "GenSigTimeoutTime_ADCAM" SG_ 1460 MPFC_Big_ECU_Package 0;
BA_ "GenSigSendType" SG_ 1460 MPFC_Big_ECU_Package 3;
BA_ "GenSigTimeoutTime_SGW" SG_ 1460 MessageCounter_FOTA_MASTER 0;
BA_ "GenSigTimeoutTime_GNMM" SG_ 1460 MessageCounter_FOTA_MASTER 0;
BA_ "GenSigTimeoutTime_ESL" SG_ 1460 MessageCounter_FOTA_MASTER 0;
BA_ "GenSigTimeoutTime_ECM" SG_ 1460 MessageCounter_FOTA_MASTER 0;
BA_ "GenSigTimeoutTime_DTCM" SG_ 1460 MessageCounter_FOTA_MASTER 0;
BA_ "GenSigTimeoutTime_DMSM" SG_ 1460 MessageCounter_FOTA_MASTER 0;
BA_ "GenSigTimeoutTime_AGSM" SG_ 1460 MessageCounter_FOTA_MASTER 0;
BA_ "GenSigTimeoutTime_SGW" SG_ 1460 CRC_FOTA_MASTER 0;
BA_ "GenSigTimeoutTime_GNMM" SG_ 1460 CRC_FOTA_MASTER 0;
BA_ "GenSigTimeoutTime_SGW" SG_ 1460 FOTA_Status 0;
BA_ "GenSigTimeoutTime_RFHM" SG_ 1460 FOTA_Status 0;
BA_ "GenSigTimeoutTime_GNMM" SG_ 1460 FOTA_Status 0;
BA_ "GenSigTimeoutTime_EVCU2" SG_ 1460 FOTA_Status 0;
BA_ "GenSigTimeoutTime_ESL" SG_ 1460 FOTA_Status 0;
BA_ "GenSigTimeoutTime_DTCM" SG_ 1460 FOTA_Status 0;
BA_ "GenSigTimeoutTime_DMSM" SG_ 1460 FOTA_Status 0;
BA_ "GenSigTimeoutTime_AGSM" SG_ 1460 FOTA_Status 0;
BA_ "GenSigSendType" SG_ 1460 FOTA_Status 3;
BA_ "GenSigTimeoutTime_SGW" SG_ 1460 Safe_State 0;
BA_ "GenSigTimeoutTime_RFHM" SG_ 1460 Safe_State 0;
BA_ "GenSigTimeoutTime_IPC" SG_ 1460 Safe_State 0;
BA_ "GenSigTimeoutTime_GNMM" SG_ 1460 Safe_State 0;
BA_ "GenSigTimeoutTime_EVCU2" SG_ 1460 Safe_State 0;
BA_ "GenSigTimeoutTime_ESL" SG_ 1460 Safe_State 0;
BA_ "GenSigTimeoutTime_ECM" SG_ 1460 Safe_State 0;
BA_ "GenSigTimeoutTime_DTCM" SG_ 1460 Safe_State 0;
BA_ "GenSigTimeoutTime_DMSM" SG_ 1460 Safe_State 0;
BA_ "GenSigTimeoutTime_BSM" SG_ 1460 Safe_State 0;
BA_ "GenSigTimeoutTime_BCM" SG_ 1460 Safe_State 0;
BA_ "GenSigTimeoutTime_AGSM" SG_ 1460 Safe_State 0;
BA_ "GenSigSendType" SG_ 1460 Safe_State 3;
BA_ "GenSigTimeoutTime_DTCM" SG_ 1460 FOTA_Purge 0;
BA_ "GenSigTimeoutTime_DMSM" SG_ 1460 FOTA_Purge 0;
BA_ "GenSigTimeoutTime_BSM" SG_ 1460 FOTA_Purge 0;
BA_ "GenSigTimeoutTime_BCM" SG_ 1460 FOTA_Purge 0;
BA_ "GenSigTimeoutTime_AGSM" SG_ 1460 FOTA_Purge 0;
BA_ "GenSigSendType" SG_ 1460 FOTA_Purge 3;
BA_ "GenSigStartValue" SG_ 1460 FOTA_Purge 1;
BA_ "GenSigTimeoutTime_SGW" SG_ 1460 FOTA_Purge 0;
BA_ "GenSigTimeoutTime_RFHM" SG_ 1460 FOTA_Purge 0;
BA_ "GenSigTimeoutTime_IPC" SG_ 1460 FOTA_Purge 0;
BA_ "GenSigTimeoutTime_GNMM" SG_ 1460 FOTA_Purge 0;
BA_ "GenSigTimeoutTime_EVCU2" SG_ 1460 FOTA_Purge 0;
BA_ "GenSigTimeoutTime_ESL" SG_ 1460 FOTA_Purge 0;
BA_ "GenSigTimeoutTime_ECM" SG_ 1460 FOTA_Purge 0;
BA_ "GenSigTimeoutTime_SGW" SG_ 1460 FOTA_Install_Type 0;
BA_ "GenSigTimeoutTime_RFHM" SG_ 1460 FOTA_Install_Type 0;
BA_ "GenSigTimeoutTime_MPAD" SG_ 1460 FOTA_Install_Type 0;
BA_ "GenSigTimeoutTime_IPC" SG_ 1460 FOTA_Install_Type 0;
BA_ "GenSigTimeoutTime_GNMM" SG_ 1460 FOTA_Install_Type 0;
BA_ "GenSigTimeoutTime_ESL" SG_ 1460 FOTA_Install_Type 0;
BA_ "GenSigTimeoutTime_DTCM" SG_ 1460 FOTA_Install_Type 0;
BA_ "GenSigTimeoutTime_DMSM" SG_ 1460 FOTA_Install_Type 0;
BA_ "GenSigTimeoutTime_BSM" SG_ 1460 FOTA_Install_Type 0;
BA_ "GenSigTimeoutTime_BCM" SG_ 1460 FOTA_Install_Type 0;
BA_ "GenSigTimeoutTime_AGSM" SG_ 1460 FOTA_Install_Type 0;
BA_ "GenSigTimeoutTime_ADCAM" SG_ 1460 FOTA_Install_Type 0;
BA_ "GenSigSendType" SG_ 1460 FOTA_Install_Type 3;
BA_ "GenSigTimeoutTime_SGW" SG_ 1460 FOTA_Installation_Status 0;
BA_ "GenSigTimeoutTime_MPAD" SG_ 1460 FOTA_Installation_Status 0;
BA_ "GenSigTimeoutTime_IPC" SG_ 1460 FOTA_Installation_Status 0;
BA_ "GenSigTimeoutTime_GNMM" SG_ 1460 FOTA_Installation_Status 0;
BA_ "GenSigTimeoutTime_ESL" SG_ 1460 FOTA_Installation_Status 0;
BA_ "GenSigTimeoutTime_ECM" SG_ 1460 FOTA_Installation_Status 0;
BA_ "GenSigTimeoutTime_DTCM" SG_ 1460 FOTA_Installation_Status 0;
BA_ "GenSigTimeoutTime_DMSM" SG_ 1460 FOTA_Installation_Status 0;
BA_ "GenSigTimeoutTime_BSM" SG_ 1460 FOTA_Installation_Status 0;
BA_ "GenSigTimeoutTime_BCM" SG_ 1460 FOTA_Installation_Status 0;
BA_ "GenSigTimeoutTime_AGSM" SG_ 1460 FOTA_Installation_Status 0;
BA_ "GenSigTimeoutTime_ADCAM" SG_ 1460 FOTA_Installation_Status 0;
BA_ "GenSigSendType" SG_ 1460 FOTA_Installation_Status 3;
BA_ "GenSigTimeoutTime_SGW" SG_ 1460 MPAD_Big_ECU_Package 0;
BA_ "GenSigTimeoutTime_RFHM" SG_ 1460 MPAD_Big_ECU_Package 0;
BA_ "GenSigTimeoutTime_IPC" SG_ 1460 MPAD_Big_ECU_Package 0;
BA_ "GenSigTimeoutTime_GNMM" SG_ 1460 MPAD_Big_ECU_Package 0;
BA_ "GenSigTimeoutTime_EVCU2" SG_ 1460 MPAD_Big_ECU_Package 0;
BA_ "GenSigTimeoutTime_ESL" SG_ 1460 MPAD_Big_ECU_Package 0;
BA_ "GenSigTimeoutTime_ECM" SG_ 1460 MPAD_Big_ECU_Package 0;
BA_ "GenSigTimeoutTime_DTCM" SG_ 1460 MPAD_Big_ECU_Package 0;
BA_ "GenSigTimeoutTime_DMSM" SG_ 1460 MPAD_Big_ECU_Package 0;
BA_ "GenSigTimeoutTime_BSM" SG_ 1460 MPAD_Big_ECU_Package 0;
BA_ "GenSigTimeoutTime_BCM" SG_ 1460 MPAD_Big_ECU_Package 0;
BA_ "GenSigTimeoutTime_AGSM" SG_ 1460 MPAD_Big_ECU_Package 0;
BA_ "GenSigTimeoutTime_ADCAM" SG_ 1460 MPAD_Big_ECU_Package 0;
BA_ "GenSigSendType" SG_ 1460 MPAD_Big_ECU_Package 3;
BA_ "GenSigTimeoutTime_SGW" SG_ 1460 ADCAM_Big_ECU_Package 0;
BA_ "GenSigTimeoutTime_RFHM" SG_ 1460 ADCAM_Big_ECU_Package 0;
BA_ "GenSigTimeoutTime_MPAD" SG_ 1460 ADCAM_Big_ECU_Package 0;
BA_ "GenSigTimeoutTime_IPC" SG_ 1460 ADCAM_Big_ECU_Package 0;
BA_ "GenSigTimeoutTime_GNMM" SG_ 1460 ADCAM_Big_ECU_Package 0;
BA_ "GenSigTimeoutTime_EVCU2" SG_ 1460 ADCAM_Big_ECU_Package 0;
BA_ "GenSigTimeoutTime_ESL" SG_ 1460 ADCAM_Big_ECU_Package 0;
BA_ "GenSigTimeoutTime_ECM" SG_ 1460 ADCAM_Big_ECU_Package 0;
BA_ "GenSigTimeoutTime_DTCM" SG_ 1460 ADCAM_Big_ECU_Package 0;
BA_ "GenSigTimeoutTime_DMSM" SG_ 1460 ADCAM_Big_ECU_Package 0;
BA_ "GenSigTimeoutTime_BSM" SG_ 1460 ADCAM_Big_ECU_Package 0;
BA_ "GenSigTimeoutTime_BCM" SG_ 1460 ADCAM_Big_ECU_Package 0;
BA_ "GenSigTimeoutTime_AGSM" SG_ 1460 ADCAM_Big_ECU_Package 0;
BA_ "GenSigSendType" SG_ 1460 ADCAM_Big_ECU_Package 3;
BA_ "GenSigTimeoutTime_ESL" SG_ 1460 CRC_FOTA_MASTER 0;
BA_ "GenSigTimeoutTime_ECM" SG_ 1460 CRC_FOTA_MASTER 0;
BA_ "GenSigTimeoutTime_DTCM" SG_ 1460 CRC_FOTA_MASTER 0;
BA_ "GenSigTimeoutTime_DMSM" SG_ 1460 CRC_FOTA_MASTER 0;
BA_ "GenSigTimeoutTime_AGSM" SG_ 1460 CRC_FOTA_MASTER 0;
BA_ "GenSigTimeoutTime_SGW" SG_ 1438 MessageCounter_DRV_MONITOR1 0;
BA_ "GenSigTimeoutTime_RFHM" SG_ 1438 MessageCounter_DRV_MONITOR1 0;
BA_ "GenSigTimeoutTime_IPC" SG_ 1438 MessageCounter_DRV_MONITOR1 0;
BA_ "GenSigTimeoutTime_GNMM" SG_ 1438 MessageCounter_DRV_MONITOR1 0;
BA_ "GenSigTimeoutTime_EVCU2" SG_ 1438 MessageCounter_DRV_MONITOR1 0;
BA_ "GenSigTimeoutTime_ESL" SG_ 1438 MessageCounter_DRV_MONITOR1 0;
BA_ "GenSigTimeoutTime_ECM" SG_ 1438 MessageCounter_DRV_MONITOR1 0;
BA_ "GenSigTimeoutTime_DTCM" SG_ 1438 MessageCounter_DRV_MONITOR1 0;
BA_ "GenSigTimeoutTime_DMSM" SG_ 1438 MessageCounter_DRV_MONITOR1 0;
BA_ "GenSigTimeoutTime_BSM" SG_ 1438 MessageCounter_DRV_MONITOR1 0;
BA_ "GenSigTimeoutTime_AGSM" SG_ 1438 MessageCounter_DRV_MONITOR1 0;
BA_ "GenSigTimeoutTime_ADCAM" SG_ 1438 MessageCounter_DRV_MONITOR1 0;
BA_ "GenSigTimeoutTime_SGW" SG_ 1438 DMSM_System_Stat 0;
BA_ "GenSigTimeoutTime_RFHM" SG_ 1438 DMSM_System_Stat 0;
BA_ "GenSigTimeoutTime_IPC" SG_ 1438 DMSM_System_Stat 0;
BA_ "GenSigTimeoutTime_GNMM" SG_ 1438 DMSM_System_Stat 0;
BA_ "GenSigTimeoutTime_EVCU2" SG_ 1438 DMSM_System_Stat 0;
BA_ "GenSigTimeoutTime_ESL" SG_ 1438 DMSM_System_Stat 0;
BA_ "GenSigTimeoutTime_ECM" SG_ 1438 DMSM_System_Stat 0;
BA_ "GenSigTimeoutTime_DTCM" SG_ 1438 DMSM_System_Stat 0;
BA_ "GenSigTimeoutTime_DMSM" SG_ 1438 DMSM_System_Stat 0;
BA_ "GenSigTimeoutTime_BSM" SG_ 1438 DMSM_System_Stat 0;
BA_ "GenSigTimeoutTime_AGSM" SG_ 1438 DMSM_System_Stat 0;
BA_ "GenSigTimeoutTime_ADCAM" SG_ 1438 DMSM_System_Stat 0;
BA_ "GenSigSendType" SG_ 1438 DMSM_System_Stat 3;
BA_ "GenSigTimeoutTime_SGW" SG_ 1438 DM_Zone_Track_Conf 0;
BA_ "GenSigTimeoutTime_RFHM" SG_ 1438 DM_Zone_Track_Conf 0;
BA_ "GenSigTimeoutTime_IPC" SG_ 1438 DM_Zone_Track_Conf 0;
BA_ "GenSigTimeoutTime_GNMM" SG_ 1438 DM_Zone_Track_Conf 0;
BA_ "GenSigTimeoutTime_EVCU2" SG_ 1438 DM_Zone_Track_Conf 0;
BA_ "GenSigTimeoutTime_ESL" SG_ 1438 DM_Zone_Track_Conf 0;
BA_ "GenSigTimeoutTime_ECM" SG_ 1438 DM_Zone_Track_Conf 0;
BA_ "GenSigTimeoutTime_DTCM" SG_ 1438 DM_Zone_Track_Conf 0;
BA_ "GenSigTimeoutTime_DMSM" SG_ 1438 DM_Zone_Track_Conf 0;
BA_ "GenSigTimeoutTime_BSM" SG_ 1438 DM_Zone_Track_Conf 0;
BA_ "GenSigTimeoutTime_AGSM" SG_ 1438 DM_Zone_Track_Conf 0;
BA_ "GenSigTimeoutTime_ADCAM" SG_ 1438 DM_Zone_Track_Conf 0;
BA_ "GenSigSendType" SG_ 1438 DM_Zone_Track_Conf 3;
BA_ "GenSigTimeoutTime_SGW" SG_ 1438 DM_Zone_Track 0;
BA_ "GenSigTimeoutTime_RFHM" SG_ 1438 DM_Zone_Track 0;
BA_ "GenSigTimeoutTime_IPC" SG_ 1438 DM_Zone_Track 0;
BA_ "GenSigTimeoutTime_GNMM" SG_ 1438 DM_Zone_Track 0;
BA_ "GenSigTimeoutTime_EVCU2" SG_ 1438 DM_Zone_Track 0;
BA_ "GenSigTimeoutTime_ESL" SG_ 1438 DM_Zone_Track 0;
BA_ "GenSigTimeoutTime_ECM" SG_ 1438 DM_Zone_Track 0;
BA_ "GenSigTimeoutTime_DTCM" SG_ 1438 DM_Zone_Track 0;
BA_ "GenSigTimeoutTime_DMSM" SG_ 1438 DM_Zone_Track 0;
BA_ "GenSigTimeoutTime_RFHM" SG_ 1438 Driver_Presence 0;
BA_ "GenSigTimeoutTime_IPC" SG_ 1438 Driver_Presence 0;
BA_ "GenSigTimeoutTime_GNMM" SG_ 1438 Driver_Presence 0;
BA_ "GenSigTimeoutTime_EVCU2" SG_ 1438 Driver_Presence 0;
BA_ "GenSigTimeoutTime_ESL" SG_ 1438 Driver_Presence 0;
BA_ "GenSigTimeoutTime_ECM" SG_ 1438 Driver_Presence 0;
BA_ "GenSigTimeoutTime_SGW" SG_ 2654339107 DES_FD08_TBM 0;
BA_ "GenSigTimeoutTime_RFHM" SG_ 2654339107 DES_FD08_TBM 0;
BA_ "GenSigTimeoutTime_MPAD" SG_ 2654339107 DES_FD08_TBM 0;
BA_ "GenSigTimeoutTime_IPC" SG_ 2654339107 DES_FD08_TBM 0;
BA_ "GenSigTimeoutTime_GNMM" SG_ 2654339107 DES_FD08_TBM 0;
BA_ "GenSigTimeoutTime_EVCU2" SG_ 2654339107 DES_FD08_TBM 0;
BA_ "GenSigTimeoutTime_ESL" SG_ 2654339107 DES_FD08_TBM 0;
BA_ "GenSigTimeoutTime_ECM" SG_ 2654339107 DES_FD08_TBM 0;
BA_ "GenSigTimeoutTime_DTCM" SG_ 2654339107 DES_FD08_TBM 0;
BA_ "GenSigTimeoutTime_DMSM" SG_ 2654339107 DES_FD08_TBM 0;
BA_ "GenSigTimeoutTime_BSM" SG_ 2654339107 DES_FD08_TBM 0;
BA_ "GenSigTimeoutTime_BCM" SG_ 2654339107 DES_FD08_TBM 0;
BA_ "GenSigTimeoutTime_AGSM" SG_ 2654339107 DES_FD08_TBM 0;
BA_ "GenSigTimeoutTime_ADCAM" SG_ 2654339107 DES_FD08_TBM 0;
BA_ "GenSigTimeoutTime_SGW" SG_ 2654339107 CurrentCanNMState_FD08_TBM 0;
BA_ "GenSigTimeoutTime_RFHM" SG_ 2654339107 CurrentCanNMState_FD08_TBM 0;
BA_ "GenSigTimeoutTime_MPAD" SG_ 2654339107 CurrentCanNMState_FD08_TBM 0;
BA_ "GenSigTimeoutTime_IPC" SG_ 2654339107 CurrentCanNMState_FD08_TBM 0;
BA_ "GenSigTimeoutTime_GNMM" SG_ 2654339107 CurrentCanNMState_FD08_TBM 0;
BA_ "GenSigTimeoutTime_EVCU2" SG_ 2654339107 CurrentCanNMState_FD08_TBM 0;
BA_ "GenSigTimeoutTime_ESL" SG_ 2654339107 CurrentCanNMState_FD08_TBM 0;
BA_ "GenSigTimeoutTime_ECM" SG_ 2654339107 CurrentCanNMState_FD08_TBM 0;
BA_ "GenSigTimeoutTime_DTCM" SG_ 2654339107 CurrentCanNMState_FD08_TBM 0;
BA_ "GenSigTimeoutTime_DMSM" SG_ 2654339107 CurrentCanNMState_FD08_TBM 0;
BA_ "GenSigTimeoutTime_BSM" SG_ 2654339107 CurrentCanNMState_FD08_TBM 0;
BA_ "GenSigTimeoutTime_BCM" SG_ 2654339107 CurrentCanNMState_FD08_TBM 0;
BA_ "GenSigTimeoutTime_AGSM" SG_ 2654339107 CurrentCanNMState_FD08_TBM 0;
BA_ "GenSigTimeoutTime_ADCAM" SG_ 2654339107 CurrentCanNMState_FD08_TBM 0;
BA_ "GenSigTimeoutTime_DTCM" SG_ 1438 Driver_Presence 0;
BA_ "GenSigTimeoutTime_DMSM" SG_ 1438 Driver_Presence 0;
BA_ "GenSigTimeoutTime_BSM" SG_ 1438 Driver_Presence 0;
BA_ "GenSigTimeoutTime_AGSM" SG_ 1438 Driver_Presence 0;
BA_ "GenSigTimeoutTime_ADCAM" SG_ 1438 Driver_Presence 0;
BA_ "GenSigSendType" SG_ 1438 Driver_Presence 3;
BA_ "GenSigTimeoutTime_SGW" SG_ 1438 MAC_DRV_MONITOR1 0;
BA_ "GenSigTimeoutTime_RFHM" SG_ 1438 MAC_DRV_MONITOR1 0;
BA_ "GenSigTimeoutTime_IPC" SG_ 1438 MAC_DRV_MONITOR1 0;
BA_ "GenSigTimeoutTime_GNMM" SG_ 1438 MAC_DRV_MONITOR1 0;
BA_ "GenSigTimeoutTime_EVCU2" SG_ 1438 MAC_DRV_MONITOR1 0;
BA_ "GenSigTimeoutTime_ESL" SG_ 1438 MAC_DRV_MONITOR1 0;
BA_ "GenSigTimeoutTime_ECM" SG_ 1438 MAC_DRV_MONITOR1 0;
BA_ "GenSigTimeoutTime_DTCM" SG_ 1438 MAC_DRV_MONITOR1 0;
BA_ "GenSigTimeoutTime_DMSM" SG_ 1438 MAC_DRV_MONITOR1 0;
BA_ "GenSigTimeoutTime_BSM" SG_ 1438 MAC_DRV_MONITOR1 0;
BA_ "GenSigTimeoutTime_AGSM" SG_ 1438 MAC_DRV_MONITOR1 0;
BA_ "GenSigTimeoutTime_ADCAM" SG_ 1438 MAC_DRV_MONITOR1 0;
BA_ "GenSigTimeoutTime_RFHM" SG_ 2654339139 PreviousCanNMState_FD03_DTCM 0;
BA_ "GenSigTimeoutTime_MPAD" SG_ 2654339139 PreviousCanNMState_FD03_DTCM 0;
BA_ "GenSigTimeoutTime_IPC" SG_ 2654339139 PreviousCanNMState_FD03_DTCM 0;
BA_ "GenSigTimeoutTime_GNMM" SG_ 2654339139 PreviousCanNMState_FD03_DTCM 0;
BA_ "GenSigTimeoutTime_EVCU2" SG_ 2654339139 PreviousCanNMState_FD03_DTCM 0;
BA_ "GenSigTimeoutTime_ESL" SG_ 2654339139 PreviousCanNMState_FD03_DTCM 0;
BA_ "GenSigTimeoutTime_ECM" SG_ 2654339139 PreviousCanNMState_FD03_DTCM 0;
BA_ "GenSigTimeoutTime_DTCM" SG_ 2654339139 PreviousCanNMState_FD03_DTCM 0;
BA_ "GenSigTimeoutTime_DMSM" SG_ 2654339139 PreviousCanNMState_FD03_DTCM 0;
BA_ "GenSigTimeoutTime_BSM" SG_ 2654339139 PreviousCanNMState_FD03_DTCM 0;
BA_ "GenSigTimeoutTime_BCM" SG_ 2654339139 PreviousCanNMState_FD03_DTCM 0;
BA_ "GenSigTimeoutTime_AGSM" SG_ 2654339139 PreviousCanNMState_FD03_DTCM 0;
BA_ "GenSigTimeoutTime_ADCAM" SG_ 2654339139 PreviousCanNMState_FD03_DTCM 0;
BA_ "GenSigTimeoutTime_RFHM" SG_ 2654339139 DES_FD03_DTCM 0;
BA_ "GenSigTimeoutTime_MPAD" SG_ 2654339139 DES_FD03_DTCM 0;
BA_ "GenSigTimeoutTime_IPC" SG_ 2654339139 DES_FD03_DTCM 0;
BA_ "GenSigTimeoutTime_GNMM" SG_ 2654339139 DES_FD03_DTCM 0;
BA_ "GenSigTimeoutTime_EVCU2" SG_ 2654339139 DES_FD03_DTCM 0;
BA_ "GenSigTimeoutTime_ESL" SG_ 2654339139 DES_FD03_DTCM 0;
BA_ "GenSigTimeoutTime_ECM" SG_ 2654339139 DES_FD03_DTCM 0;
BA_ "GenSigTimeoutTime_DTCM" SG_ 2654339139 DES_FD03_DTCM 0;
BA_ "GenSigTimeoutTime_DMSM" SG_ 2654339139 DES_FD03_DTCM 0;
BA_ "GenSigTimeoutTime_BSM" SG_ 2654339139 DES_FD03_DTCM 0;
BA_ "GenSigTimeoutTime_BCM" SG_ 2654339139 DES_FD03_DTCM 0;
BA_ "GenSigTimeoutTime_AGSM" SG_ 2654339139 DES_FD03_DTCM 0;
BA_ "GenSigTimeoutTime_ADCAM" SG_ 2654339139 DES_FD03_DTCM 0;
BA_ "GenSigTimeoutTime_RFHM" SG_ 2654339139 CurrentCanNMState_FD03_DTCM 0;
BA_ "GenSigTimeoutTime_MPAD" SG_ 2654339139 CurrentCanNMState_FD03_DTCM 0;
BA_ "GenSigTimeoutTime_IPC" SG_ 2654339139 CurrentCanNMState_FD03_DTCM 0;
BA_ "GenSigTimeoutTime_GNMM" SG_ 2654339139 CurrentCanNMState_FD03_DTCM 0;
BA_ "GenSigTimeoutTime_EVCU2" SG_ 2654339139 CurrentCanNMState_FD03_DTCM 0;
BA_ "GenSigTimeoutTime_ESL" SG_ 2654339139 CurrentCanNMState_FD03_DTCM 0;
BA_ "GenSigTimeoutTime_ECM" SG_ 2654339139 CurrentCanNMState_FD03_DTCM 0;
BA_ "GenSigTimeoutTime_DTCM" SG_ 2654339139 CurrentCanNMState_FD03_DTCM 0;
BA_ "GenSigTimeoutTime_DMSM" SG_ 2654339139 CurrentCanNMState_FD03_DTCM 0;
BA_ "GenSigTimeoutTime_BSM" SG_ 2654339139 CurrentCanNMState_FD03_DTCM 0;
BA_ "GenSigTimeoutTime_BCM" SG_ 2654339139 CurrentCanNMState_FD03_DTCM 0;
BA_ "GenSigTimeoutTime_AGSM" SG_ 2654339139 CurrentCanNMState_FD03_DTCM 0;
BA_ "GenSigTimeoutTime_ADCAM" SG_ 2654339139 CurrentCanNMState_FD03_DTCM 0;
BA_ "GenSigTimeoutTime_RFHM" SG_ 2654339225 WakeupSource_FD03_DMSM 0;
BA_ "GenSigTimeoutTime_MPAD" SG_ 2654339225 WakeupSource_FD03_DMSM 0;
BA_ "GenSigTimeoutTime_IPC" SG_ 2654339225 WakeupSource_FD03_DMSM 0;
BA_ "GenSigTimeoutTime_GNMM" SG_ 2654339225 WakeupSource_FD03_DMSM 0;
BA_ "GenSigTimeoutTime_EVCU2" SG_ 2654339225 WakeupSource_FD03_DMSM 0;
BA_ "GenSigTimeoutTime_ESL" SG_ 2654339225 WakeupSource_FD03_DMSM 0;
BA_ "GenSigTimeoutTime_ECM" SG_ 2654339225 WakeupSource_FD03_DMSM 0;
BA_ "GenSigTimeoutTime_DTCM" SG_ 2654339225 WakeupSource_FD03_DMSM 0;
BA_ "GenSigTimeoutTime_DMSM" SG_ 2654339225 WakeupSource_FD03_DMSM 0;
BA_ "GenSigTimeoutTime_BSM" SG_ 2654339225 WakeupSource_FD03_DMSM 0;
BA_ "GenSigTimeoutTime_BCM" SG_ 2654339225 WakeupSource_FD03_DMSM 0;
BA_ "GenSigTimeoutTime_AGSM" SG_ 2654339225 WakeupSource_FD03_DMSM 0;
BA_ "GenSigTimeoutTime_ADCAM" SG_ 2654339225 WakeupSource_FD03_DMSM 0;
BA_ "GenSigTimeoutTime_RFHM" SG_ 2654339225 PreviousCanNMState_FD03_DMSM 0;
BA_ "GenSigTimeoutTime_MPAD" SG_ 2654339225 PreviousCanNMState_FD03_DMSM 0;
BA_ "GenSigTimeoutTime_IPC" SG_ 2654339225 PreviousCanNMState_FD03_DMSM 0;
BA_ "GenSigTimeoutTime_GNMM" SG_ 2654339225 PreviousCanNMState_FD03_DMSM 0;
BA_ "GenSigTimeoutTime_EVCU2" SG_ 2654339225 PreviousCanNMState_FD03_DMSM 0;
BA_ "GenSigTimeoutTime_ESL" SG_ 2654339225 PreviousCanNMState_FD03_DMSM 0;
BA_ "GenSigTimeoutTime_ECM" SG_ 2654339225 PreviousCanNMState_FD03_DMSM 0;
BA_ "GenSigTimeoutTime_DTCM" SG_ 2654339225 PreviousCanNMState_FD03_DMSM 0;
BA_ "GenSigTimeoutTime_DMSM" SG_ 2654339225 PreviousCanNMState_FD03_DMSM 0;
BA_ "GenSigTimeoutTime_BSM" SG_ 2654339225 PreviousCanNMState_FD03_DMSM 0;
BA_ "GenSigTimeoutTime_BCM" SG_ 2654339225 PreviousCanNMState_FD03_DMSM 0;
BA_ "GenSigTimeoutTime_AGSM" SG_ 2654339225 PreviousCanNMState_FD03_DMSM 0;
BA_ "GenSigTimeoutTime_ADCAM" SG_ 2654339225 PreviousCanNMState_FD03_DMSM 0;
BA_ "GenSigTimeoutTime_RFHM" SG_ 2654339225 DES_FD03_DMSM 0;
BA_ "GenSigTimeoutTime_MPAD" SG_ 2654339225 DES_FD03_DMSM 0;
BA_ "GenSigTimeoutTime_IPC" SG_ 2654339225 DES_FD03_DMSM 0;
BA_ "GenSigTimeoutTime_GNMM" SG_ 2654339225 DES_FD03_DMSM 0;
BA_ "GenSigTimeoutTime_EVCU2" SG_ 2654339225 DES_FD03_DMSM 0;
BA_ "GenSigTimeoutTime_ESL" SG_ 2654339225 DES_FD03_DMSM 0;
BA_ "GenSigTimeoutTime_ECM" SG_ 2654339225 DES_FD03_DMSM 0;
BA_ "GenSigTimeoutTime_DTCM" SG_ 2654339225 DES_FD03_DMSM 0;
BA_ "GenSigTimeoutTime_DMSM" SG_ 2654339225 DES_FD03_DMSM 0;
BA_ "GenSigTimeoutTime_BSM" SG_ 2654339225 DES_FD03_DMSM 0;
BA_ "GenSigTimeoutTime_BCM" SG_ 2654339225 DES_FD03_DMSM 0;
BA_ "GenSigTimeoutTime_AGSM" SG_ 2654339225 DES_FD03_DMSM 0;
BA_ "GenSigTimeoutTime_ADCAM" SG_ 2654339225 DES_FD03_DMSM 0;
BA_ "GenSigTimeoutTime_RFHM" SG_ 2654339225 CurrentCanNMState_FD03_DMSM 0;
BA_ "GenSigTimeoutTime_MPAD" SG_ 2654339225 CurrentCanNMState_FD03_DMSM 0;
BA_ "GenSigTimeoutTime_IPC" SG_ 2654339225 CurrentCanNMState_FD03_DMSM 0;
BA_ "GenSigTimeoutTime_GNMM" SG_ 2654339225 CurrentCanNMState_FD03_DMSM 0;
BA_ "GenSigTimeoutTime_EVCU2" SG_ 2654339225 CurrentCanNMState_FD03_DMSM 0;
BA_ "GenSigTimeoutTime_ESL" SG_ 2654339225 CurrentCanNMState_FD03_DMSM 0;
BA_ "GenSigTimeoutTime_ECM" SG_ 2654339225 CurrentCanNMState_FD03_DMSM 0;
BA_ "GenSigTimeoutTime_DTCM" SG_ 2654339225 CurrentCanNMState_FD03_DMSM 0;
BA_ "GenSigTimeoutTime_DMSM" SG_ 2654339225 CurrentCanNMState_FD03_DMSM 0;
BA_ "GenSigTimeoutTime_BSM" SG_ 2654339225 CurrentCanNMState_FD03_DMSM 0;
BA_ "GenSigTimeoutTime_BCM" SG_ 2654339225 CurrentCanNMState_FD03_DMSM 0;
BA_ "GenSigTimeoutTime_AGSM" SG_ 2654339225 CurrentCanNMState_FD03_DMSM 0;
BA_ "GenSigTimeoutTime_ADCAM" SG_ 2654339225 CurrentCanNMState_FD03_DMSM 0;
BA_ "GenSigTimeoutTime_RFHM" SG_ 2654339225 GenericFailSts_FD03_DMSM 0;
BA_ "GenSigTimeoutTime_MPAD" SG_ 2654339225 GenericFailSts_FD03_DMSM 0;
BA_ "GenSigTimeoutTime_IPC" SG_ 2654339225 GenericFailSts_FD03_DMSM 0;
BA_ "GenSigTimeoutTime_GNMM" SG_ 2654339225 GenericFailSts_FD03_DMSM 0;
BA_ "GenSigTimeoutTime_EVCU2" SG_ 2654339225 GenericFailSts_FD03_DMSM 0;
BA_ "GenSigTimeoutTime_ESL" SG_ 2654339225 GenericFailSts_FD03_DMSM 0;
BA_ "GenSigTimeoutTime_ECM" SG_ 2654339225 GenericFailSts_FD03_DMSM 0;
BA_ "GenSigTimeoutTime_DTCM" SG_ 2654339225 GenericFailSts_FD03_DMSM 0;
BA_ "GenSigTimeoutTime_DMSM" SG_ 2654339225 GenericFailSts_FD03_DMSM 0;
BA_ "GenSigTimeoutTime_BSM" SG_ 2654339225 GenericFailSts_FD03_DMSM 0;
BA_ "GenSigTimeoutTime_AGSM" SG_ 2654339225 GenericFailSts_FD03_DMSM 0;
BA_ "GenSigTimeoutTime_ADCAM" SG_ 2654339225 GenericFailSts_FD03_DMSM 0;
BA_ "GenSigTimeoutTime_RFHM" SG_ 2654339225 EOL_FD03_DMSM 0;
BA_ "GenSigTimeoutTime_MPAD" SG_ 2654339225 EOL_FD03_DMSM 0;
BA_ "GenSigTimeoutTime_IPC" SG_ 2654339225 EOL_FD03_DMSM 0;
BA_ "GenSigTimeoutTime_GNMM" SG_ 2654339225 EOL_FD03_DMSM 0;
BA_ "GenSigTimeoutTime_EVCU2" SG_ 2654339225 EOL_FD03_DMSM 0;
BA_ "GenSigTimeoutTime_ESL" SG_ 2654339225 EOL_FD03_DMSM 0;
BA_ "GenSigTimeoutTime_ECM" SG_ 2654339225 EOL_FD03_DMSM 0;
BA_ "GenSigTimeoutTime_DTCM" SG_ 2654339225 EOL_FD03_DMSM 0;
BA_ "GenSigTimeoutTime_DMSM" SG_ 2654339225 EOL_FD03_DMSM 0;
BA_ "GenSigTimeoutTime_BSM" SG_ 2654339225 EOL_FD03_DMSM 0;
BA_ "GenSigTimeoutTime_AGSM" SG_ 2654339225 EOL_FD03_DMSM 0;
BA_ "GenSigTimeoutTime_ADCAM" SG_ 2654339225 EOL_FD03_DMSM 0;
BA_ "GenSigTimeoutTime_RFHM" SG_ 2654339225 CurrentFailSts_FD03_DMSM 0;
BA_ "GenSigTimeoutTime_MPAD" SG_ 2654339225 CurrentFailSts_FD03_DMSM 0;
BA_ "GenSigTimeoutTime_IPC" SG_ 2654339225 CurrentFailSts_FD03_DMSM 0;
BA_ "GenSigTimeoutTime_GNMM" SG_ 2654339225 CurrentFailSts_FD03_DMSM 0;
BA_ "GenSigTimeoutTime_EVCU2" SG_ 2654339225 CurrentFailSts_FD03_DMSM 0;
BA_ "GenSigTimeoutTime_ESL" SG_ 2654339225 CurrentFailSts_FD03_DMSM 0;
BA_ "GenSigTimeoutTime_ECM" SG_ 2654339225 CurrentFailSts_FD03_DMSM 0;
BA_ "GenSigTimeoutTime_DTCM" SG_ 2654339225 CurrentFailSts_FD03_DMSM 0;
BA_ "GenSigTimeoutTime_DMSM" SG_ 2654339225 CurrentFailSts_FD03_DMSM 0;
BA_ "GenSigTimeoutTime_BSM" SG_ 2654339225 CurrentFailSts_FD03_DMSM 0;
BA_ "GenSigTimeoutTime_AGSM" SG_ 2654339225 CurrentFailSts_FD03_DMSM 0;
BA_ "GenSigTimeoutTime_ADCAM" SG_ 2654339225 CurrentFailSts_FD03_DMSM 0;
BA_ "GenSigTimeoutTime_RFHM" SG_ 2654339225 StayActiveSource_FD03_DMSM 0;
BA_ "GenSigTimeoutTime_MPAD" SG_ 2654339225 StayActiveSource_FD03_DMSM 0;
BA_ "GenSigTimeoutTime_IPC" SG_ 2654339225 StayActiveSource_FD03_DMSM 0;
BA_ "GenSigTimeoutTime_GNMM" SG_ 2654339225 StayActiveSource_FD03_DMSM 0;
BA_ "GenSigTimeoutTime_EVCU2" SG_ 2654339225 StayActiveSource_FD03_DMSM 0;
BA_ "GenSigTimeoutTime_ESL" SG_ 2654339225 StayActiveSource_FD03_DMSM 0;
BA_ "GenSigTimeoutTime_ECM" SG_ 2654339225 StayActiveSource_FD03_DMSM 0;
BA_ "GenSigTimeoutTime_DTCM" SG_ 2654339225 StayActiveSource_FD03_DMSM 0;
BA_ "GenSigTimeoutTime_DMSM" SG_ 2654339225 StayActiveSource_FD03_DMSM 0;
BA_ "GenSigTimeoutTime_BSM" SG_ 2654339225 StayActiveSource_FD03_DMSM 0;
BA_ "GenSigTimeoutTime_BCM" SG_ 2654339225 StayActiveSource_FD03_DMSM 0;
BA_ "GenSigTimeoutTime_AGSM" SG_ 2654339225 StayActiveSource_FD03_DMSM 0;
BA_ "GenSigTimeoutTime_ADCAM" SG_ 2654339225 StayActiveSource_FD03_DMSM 0;
BA_ "GenSigTimeoutTime_RFHM" SG_ 2654339139 StayActiveSource_FD03_DTCM 0;
BA_ "GenSigTimeoutTime_MPAD" SG_ 2654339139 StayActiveSource_FD03_DTCM 0;
BA_ "GenSigTimeoutTime_IPC" SG_ 2654339139 StayActiveSource_FD03_DTCM 0;
BA_ "GenSigTimeoutTime_GNMM" SG_ 2654339139 StayActiveSource_FD03_DTCM 0;
BA_ "GenSigTimeoutTime_EVCU2" SG_ 2654339139 StayActiveSource_FD03_DTCM 0;
BA_ "GenSigTimeoutTime_ESL" SG_ 2654339139 StayActiveSource_FD03_DTCM 0;
BA_ "GenSigTimeoutTime_ECM" SG_ 2654339139 StayActiveSource_FD03_DTCM 0;
BA_ "GenSigTimeoutTime_DTCM" SG_ 2654339139 StayActiveSource_FD03_DTCM 0;
BA_ "GenSigTimeoutTime_DMSM" SG_ 2654339139 StayActiveSource_FD03_DTCM 0;
BA_ "GenSigTimeoutTime_BSM" SG_ 2654339139 StayActiveSource_FD03_DTCM 0;
BA_ "GenSigTimeoutTime_BCM" SG_ 2654339139 StayActiveSource_FD03_DTCM 0;
BA_ "GenSigTimeoutTime_AGSM" SG_ 2654339139 StayActiveSource_FD03_DTCM 0;
BA_ "GenSigTimeoutTime_ADCAM" SG_ 2654339139 StayActiveSource_FD03_DTCM 0;
BA_ "GenSigTimeoutTime_ADCAM" SG_ 2654339093 WakeupSource_FD03_ESL 0;
BA_ "GenSigTimeoutTime_SGW" SG_ 2654339108 CurrentFailSts_FD08_ETM 0;
BA_ "GenSigTimeoutTime_SGW" SG_ 2654339108 DES_FD08_ETM 0;
BA_ "GenSigTimeoutTime_RFHM" SG_ 2654339108 DES_FD08_ETM 0;
BA_ "GenSigTimeoutTime_MPAD" SG_ 2654339108 DES_FD08_ETM 0;
BA_ "GenSigTimeoutTime_IPC" SG_ 2654339108 DES_FD08_ETM 0;
BA_ "GenSigTimeoutTime_GNMM" SG_ 2654339108 DES_FD08_ETM 0;
BA_ "GenSigTimeoutTime_EVCU2" SG_ 2654339108 DES_FD08_ETM 0;
BA_ "GenSigTimeoutTime_ESL" SG_ 2654339108 DES_FD08_ETM 0;
BA_ "GenSigTimeoutTime_ECM" SG_ 2654339108 DES_FD08_ETM 0;
BA_ "GenSigTimeoutTime_DTCM" SG_ 2654339108 DES_FD08_ETM 0;
BA_ "GenSigTimeoutTime_DMSM" SG_ 2654339108 DES_FD08_ETM 0;
BA_ "GenSigTimeoutTime_BSM" SG_ 2654339108 DES_FD08_ETM 0;
BA_ "GenSigTimeoutTime_BCM" SG_ 2654339108 DES_FD08_ETM 0;
BA_ "GenSigTimeoutTime_AGSM" SG_ 2654339108 DES_FD08_ETM 0;
BA_ "GenSigTimeoutTime_ADCAM" SG_ 2654339108 DES_FD08_ETM 0;
BA_ "GenSigTimeoutTime_RFHM" SG_ 2654339216 StayActiveSource_FD03_GNMM 0;
BA_ "GenSigTimeoutTime_MPAD" SG_ 2654339216 StayActiveSource_FD03_GNMM 0;
BA_ "GenSigTimeoutTime_IPC" SG_ 2654339216 StayActiveSource_FD03_GNMM 0;
BA_ "GenSigTimeoutTime_GNMM" SG_ 2654339216 StayActiveSource_FD03_GNMM 0;
BA_ "GenSigTimeoutTime_EVCU2" SG_ 2654339216 StayActiveSource_FD03_GNMM 0;
BA_ "GenSigTimeoutTime_ESL" SG_ 2654339216 StayActiveSource_FD03_GNMM 0;
BA_ "GenSigTimeoutTime_ECM" SG_ 2654339216 StayActiveSource_FD03_GNMM 0;
BA_ "GenSigTimeoutTime_DTCM" SG_ 2654339216 StayActiveSource_FD03_GNMM 0;
BA_ "GenSigTimeoutTime_DMSM" SG_ 2654339216 StayActiveSource_FD03_GNMM 0;
BA_ "GenSigTimeoutTime_BSM" SG_ 2654339216 StayActiveSource_FD03_GNMM 0;
BA_ "GenSigTimeoutTime_BCM" SG_ 2654339216 StayActiveSource_FD03_GNMM 0;
BA_ "GenSigTimeoutTime_AGSM" SG_ 2654339216 StayActiveSource_FD03_GNMM 0;
BA_ "GenSigTimeoutTime_ADCAM" SG_ 2654339216 StayActiveSource_FD03_GNMM 0;
BA_ "GenSigTimeoutTime_RFHM" SG_ 2654339216 EOL_FD03_GNMM 0;
BA_ "GenSigTimeoutTime_MPAD" SG_ 2654339216 EOL_FD03_GNMM 0;
BA_ "GenSigTimeoutTime_IPC" SG_ 2654339216 EOL_FD03_GNMM 0;
BA_ "GenSigTimeoutTime_GNMM" SG_ 2654339216 EOL_FD03_GNMM 0;
BA_ "GenSigTimeoutTime_EVCU2" SG_ 2654339216 EOL_FD03_GNMM 0;
BA_ "GenSigTimeoutTime_ESL" SG_ 2654339216 EOL_FD03_GNMM 0;
BA_ "GenSigTimeoutTime_ECM" SG_ 2654339216 EOL_FD03_GNMM 0;
BA_ "GenSigTimeoutTime_DTCM" SG_ 2654339216 EOL_FD03_GNMM 0;
BA_ "GenSigTimeoutTime_DMSM" SG_ 2654339216 EOL_FD03_GNMM 0;
BA_ "GenSigTimeoutTime_BSM" SG_ 2654339216 EOL_FD03_GNMM 0;
BA_ "GenSigTimeoutTime_AGSM" SG_ 2654339216 EOL_FD03_GNMM 0;
BA_ "GenSigTimeoutTime_ADCAM" SG_ 2654339216 EOL_FD03_GNMM 0;
BA_ "GenSigTimeoutTime_RFHM" SG_ 2654339216 GenericFailSts_FD03_GNMM 0;
BA_ "GenSigTimeoutTime_MPAD" SG_ 2654339216 GenericFailSts_FD03_GNMM 0;
BA_ "GenSigTimeoutTime_IPC" SG_ 2654339216 GenericFailSts_FD03_GNMM 0;
BA_ "GenSigTimeoutTime_GNMM" SG_ 2654339216 GenericFailSts_FD03_GNMM 0;
BA_ "GenSigTimeoutTime_EVCU2" SG_ 2654339216 GenericFailSts_FD03_GNMM 0;
BA_ "GenSigTimeoutTime_ESL" SG_ 2654339216 GenericFailSts_FD03_GNMM 0;
BA_ "GenSigTimeoutTime_ECM" SG_ 2654339216 GenericFailSts_FD03_GNMM 0;
BA_ "GenSigTimeoutTime_DTCM" SG_ 2654339216 GenericFailSts_FD03_GNMM 0;
BA_ "GenSigTimeoutTime_DMSM" SG_ 2654339216 GenericFailSts_FD03_GNMM 0;
BA_ "GenSigTimeoutTime_BSM" SG_ 2654339216 GenericFailSts_FD03_GNMM 0;
BA_ "GenSigTimeoutTime_AGSM" SG_ 2654339216 GenericFailSts_FD03_GNMM 0;
BA_ "GenSigTimeoutTime_ADCAM" SG_ 2654339216 GenericFailSts_FD03_GNMM 0;
BA_ "GenSigTimeoutTime_RFHM" SG_ 2654339216 DES_FD03_GNMM 0;
BA_ "GenSigTimeoutTime_MPAD" SG_ 2654339216 DES_FD03_GNMM 0;
BA_ "GenSigTimeoutTime_IPC" SG_ 2654339216 DES_FD03_GNMM 0;
BA_ "GenSigTimeoutTime_GNMM" SG_ 2654339216 DES_FD03_GNMM 0;
BA_ "GenSigTimeoutTime_EVCU2" SG_ 2654339216 DES_FD03_GNMM 0;
BA_ "GenSigTimeoutTime_ESL" SG_ 2654339216 DES_FD03_GNMM 0;
BA_ "GenSigTimeoutTime_ECM" SG_ 2654339216 DES_FD03_GNMM 0;
BA_ "GenSigTimeoutTime_RFHM" SG_ 2654339216 PreviousCanNMState_FD03_GNMM 0;
BA_ "GenSigTimeoutTime_MPAD" SG_ 2654339216 PreviousCanNMState_FD03_GNMM 0;
BA_ "GenSigTimeoutTime_IPC" SG_ 2654339216 PreviousCanNMState_FD03_GNMM 0;
BA_ "GenSigTimeoutTime_GNMM" SG_ 2654339216 PreviousCanNMState_FD03_GNMM 0;
BA_ "GenSigTimeoutTime_EVCU2" SG_ 2654339216 PreviousCanNMState_FD03_GNMM 0;
BA_ "GenSigTimeoutTime_ESL" SG_ 2654339216 PreviousCanNMState_FD03_GNMM 0;
BA_ "GenSigTimeoutTime_ECM" SG_ 2654339216 PreviousCanNMState_FD03_GNMM 0;
BA_ "GenSigTimeoutTime_DTCM" SG_ 2654339216 PreviousCanNMState_FD03_GNMM 0;
BA_ "GenSigTimeoutTime_DMSM" SG_ 2654339216 PreviousCanNMState_FD03_GNMM 0;
BA_ "GenSigTimeoutTime_BSM" SG_ 2654339216 PreviousCanNMState_FD03_GNMM 0;
BA_ "GenSigTimeoutTime_BCM" SG_ 2654339216 PreviousCanNMState_FD03_GNMM 0;
BA_ "GenSigTimeoutTime_AGSM" SG_ 2654339216 PreviousCanNMState_FD03_GNMM 0;
BA_ "GenSigTimeoutTime_ADCAM" SG_ 2654339216 PreviousCanNMState_FD03_GNMM 0;
BA_ "GenSigTimeoutTime_RFHM" SG_ 2654339216 WakeupSource_FD03_GNMM 0;
BA_ "GenSigTimeoutTime_MPAD" SG_ 2654339216 WakeupSource_FD03_GNMM 0;
BA_ "GenSigTimeoutTime_IPC" SG_ 2654339216 WakeupSource_FD03_GNMM 0;
BA_ "GenSigTimeoutTime_GNMM" SG_ 2654339216 WakeupSource_FD03_GNMM 0;
BA_ "GenSigTimeoutTime_EVCU2" SG_ 2654339216 WakeupSource_FD03_GNMM 0;
BA_ "GenSigTimeoutTime_ESL" SG_ 2654339216 WakeupSource_FD03_GNMM 0;
BA_ "GenSigTimeoutTime_ECM" SG_ 2654339216 WakeupSource_FD03_GNMM 0;
BA_ "GenSigTimeoutTime_DTCM" SG_ 2654339216 WakeupSource_FD03_GNMM 0;
BA_ "GenSigTimeoutTime_DMSM" SG_ 2654339216 WakeupSource_FD03_GNMM 0;
BA_ "GenSigTimeoutTime_BSM" SG_ 2654339216 WakeupSource_FD03_GNMM 0;
BA_ "GenSigTimeoutTime_BCM" SG_ 2654339216 WakeupSource_FD03_GNMM 0;
BA_ "GenSigTimeoutTime_AGSM" SG_ 2654339216 WakeupSource_FD03_GNMM 0;
BA_ "GenSigTimeoutTime_ADCAM" SG_ 2654339216 WakeupSource_FD03_GNMM 0;
BA_ "GenSigTimeoutTime_RFHM" SG_ 2654339078 StayActiveSource_FD03_BSM 0;
BA_ "GenSigTimeoutTime_MPAD" SG_ 2654339078 StayActiveSource_FD03_BSM 0;
BA_ "GenSigTimeoutTime_IPC" SG_ 2654339078 StayActiveSource_FD03_BSM 0;
BA_ "GenSigTimeoutTime_GNMM" SG_ 2654339078 StayActiveSource_FD03_BSM 0;
BA_ "GenSigTimeoutTime_EVCU2" SG_ 2654339078 StayActiveSource_FD03_BSM 0;
BA_ "GenSigTimeoutTime_ESL" SG_ 2654339078 StayActiveSource_FD03_BSM 0;
BA_ "GenSigTimeoutTime_ECM" SG_ 2654339078 StayActiveSource_FD03_BSM 0;
BA_ "GenSigTimeoutTime_DTCM" SG_ 2654339078 StayActiveSource_FD03_BSM 0;
BA_ "GenSigTimeoutTime_DMSM" SG_ 2654339078 StayActiveSource_FD03_BSM 0;
BA_ "GenSigTimeoutTime_BSM" SG_ 2654339078 StayActiveSource_FD03_BSM 0;
BA_ "GenSigTimeoutTime_BCM" SG_ 2654339078 StayActiveSource_FD03_BSM 0;
BA_ "GenSigTimeoutTime_AGSM" SG_ 2654339078 StayActiveSource_FD03_BSM 0;
BA_ "GenSigTimeoutTime_ADCAM" SG_ 2654339078 StayActiveSource_FD03_BSM 0;
BA_ "GenSigTimeoutTime_RFHM" SG_ 2654339078 WakeupSource_FD03_BSM 0;
BA_ "GenSigTimeoutTime_MPAD" SG_ 2654339078 WakeupSource_FD03_BSM 0;
BA_ "GenSigTimeoutTime_IPC" SG_ 2654339078 WakeupSource_FD03_BSM 0;
BA_ "GenSigTimeoutTime_GNMM" SG_ 2654339078 WakeupSource_FD03_BSM 0;
BA_ "GenSigTimeoutTime_EVCU2" SG_ 2654339078 WakeupSource_FD03_BSM 0;
BA_ "GenSigTimeoutTime_ESL" SG_ 2654339078 WakeupSource_FD03_BSM 0;
BA_ "GenSigTimeoutTime_ECM" SG_ 2654339078 WakeupSource_FD03_BSM 0;
BA_ "GenSigTimeoutTime_DTCM" SG_ 2654339078 WakeupSource_FD03_BSM 0;
BA_ "GenSigTimeoutTime_DMSM" SG_ 2654339078 WakeupSource_FD03_BSM 0;
BA_ "GenSigTimeoutTime_BSM" SG_ 2654339078 WakeupSource_FD03_BSM 0;
BA_ "GenSigTimeoutTime_BCM" SG_ 2654339078 WakeupSource_FD03_BSM 0;
BA_ "GenSigTimeoutTime_AGSM" SG_ 2654339078 WakeupSource_FD03_BSM 0;
BA_ "GenSigTimeoutTime_ADCAM" SG_ 2654339078 WakeupSource_FD03_BSM 0;
BA_ "GenSigTimeoutTime_ADCAM" SG_ 2654339078 PreviousCanNMState_FD03_BSM 0;
BA_ "GenSigTimeoutTime_RFHM" SG_ 2654339078 PreviousCanNMState_FD03_BSM 0;
BA_ "GenSigTimeoutTime_MPAD" SG_ 2654339078 PreviousCanNMState_FD03_BSM 0;
BA_ "GenSigTimeoutTime_IPC" SG_ 2654339078 PreviousCanNMState_FD03_BSM 0;
BA_ "GenSigTimeoutTime_GNMM" SG_ 2654339078 PreviousCanNMState_FD03_BSM 0;
BA_ "GenSigTimeoutTime_EVCU2" SG_ 2654339078 PreviousCanNMState_FD03_BSM 0;
BA_ "GenSigTimeoutTime_ESL" SG_ 2654339078 PreviousCanNMState_FD03_BSM 0;
BA_ "GenSigTimeoutTime_ECM" SG_ 2654339078 PreviousCanNMState_FD03_BSM 0;
BA_ "GenSigTimeoutTime_DTCM" SG_ 2654339078 PreviousCanNMState_FD03_BSM 0;
BA_ "GenSigTimeoutTime_DMSM" SG_ 2654339078 PreviousCanNMState_FD03_BSM 0;
BA_ "GenSigTimeoutTime_BSM" SG_ 2654339078 PreviousCanNMState_FD03_BSM 0;
BA_ "GenSigTimeoutTime_BCM" SG_ 2654339078 PreviousCanNMState_FD03_BSM 0;
BA_ "GenSigTimeoutTime_AGSM" SG_ 2654339078 PreviousCanNMState_FD03_BSM 0;
BA_ "GenSigTimeoutTime_RFHM" SG_ 2654339139 GenericFailSts_FD03_DTCM 0;
BA_ "GenSigTimeoutTime_MPAD" SG_ 2654339139 GenericFailSts_FD03_DTCM 0;
BA_ "GenSigTimeoutTime_IPC" SG_ 2654339139 GenericFailSts_FD03_DTCM 0;
BA_ "GenSigTimeoutTime_GNMM" SG_ 2654339139 GenericFailSts_FD03_DTCM 0;
BA_ "GenSigTimeoutTime_EVCU2" SG_ 2654339139 GenericFailSts_FD03_DTCM 0;
BA_ "GenSigTimeoutTime_ESL" SG_ 2654339139 GenericFailSts_FD03_DTCM 0;
BA_ "GenSigTimeoutTime_ECM" SG_ 2654339139 GenericFailSts_FD03_DTCM 0;
BA_ "GenSigTimeoutTime_DTCM" SG_ 2654339139 GenericFailSts_FD03_DTCM 0;
BA_ "GenSigTimeoutTime_DMSM" SG_ 2654339139 GenericFailSts_FD03_DTCM 0;
BA_ "GenSigTimeoutTime_BSM" SG_ 2654339139 GenericFailSts_FD03_DTCM 0;
BA_ "GenSigTimeoutTime_AGSM" SG_ 2654339139 GenericFailSts_FD03_DTCM 0;
BA_ "GenSigTimeoutTime_ADCAM" SG_ 2654339139 GenericFailSts_FD03_DTCM 0;
BA_ "GenSigTimeoutTime_RFHM" SG_ 2654339139 EOL_FD03_DTCM 0;
BA_ "GenSigTimeoutTime_MPAD" SG_ 2654339139 EOL_FD03_DTCM 0;
BA_ "GenSigTimeoutTime_IPC" SG_ 2654339139 EOL_FD03_DTCM 0;
BA_ "GenSigTimeoutTime_GNMM" SG_ 2654339139 EOL_FD03_DTCM 0;
BA_ "GenSigTimeoutTime_EVCU2" SG_ 2654339139 EOL_FD03_DTCM 0;
BA_ "GenSigTimeoutTime_ESL" SG_ 2654339139 EOL_FD03_DTCM 0;
BA_ "GenSigTimeoutTime_ECM" SG_ 2654339139 EOL_FD03_DTCM 0;
BA_ "GenSigTimeoutTime_DTCM" SG_ 2654339139 EOL_FD03_DTCM 0;
BA_ "GenSigTimeoutTime_DMSM" SG_ 2654339139 EOL_FD03_DTCM 0;
BA_ "GenSigTimeoutTime_BSM" SG_ 2654339139 EOL_FD03_DTCM 0;
BA_ "GenSigTimeoutTime_AGSM" SG_ 2654339139 EOL_FD03_DTCM 0;
BA_ "GenSigTimeoutTime_ADCAM" SG_ 2654339139 EOL_FD03_DTCM 0;
BA_ "GenSigTimeoutTime_RFHM" SG_ 2654339139 CurrentFailSts_FD03_DTCM 0;
BA_ "GenSigTimeoutTime_MPAD" SG_ 2654339139 CurrentFailSts_FD03_DTCM 0;
BA_ "GenSigTimeoutTime_IPC" SG_ 2654339139 CurrentFailSts_FD03_DTCM 0;
BA_ "GenSigTimeoutTime_GNMM" SG_ 2654339139 CurrentFailSts_FD03_DTCM 0;
BA_ "GenSigTimeoutTime_EVCU2" SG_ 2654339139 CurrentFailSts_FD03_DTCM 0;
BA_ "GenSigTimeoutTime_ESL" SG_ 2654339139 CurrentFailSts_FD03_DTCM 0;
BA_ "GenSigTimeoutTime_ECM" SG_ 2654339139 CurrentFailSts_FD03_DTCM 0;
BA_ "GenSigTimeoutTime_DTCM" SG_ 2654339139 CurrentFailSts_FD03_DTCM 0;
BA_ "GenSigTimeoutTime_DMSM" SG_ 2654339139 CurrentFailSts_FD03_DTCM 0;
BA_ "GenSigTimeoutTime_BSM" SG_ 2654339139 CurrentFailSts_FD03_DTCM 0;
BA_ "GenSigTimeoutTime_AGSM" SG_ 2654339139 CurrentFailSts_FD03_DTCM 0;
BA_ "GenSigTimeoutTime_ADCAM" SG_ 2654339139 CurrentFailSts_FD03_DTCM 0;
BA_ "GenSigTimeoutTime_RFHM" SG_ 2654339078 GenericFailSts_FD03_BSM 0;
BA_ "GenSigTimeoutTime_MPAD" SG_ 2654339078 GenericFailSts_FD03_BSM 0;
BA_ "GenSigTimeoutTime_IPC" SG_ 2654339078 GenericFailSts_FD03_BSM 0;
BA_ "GenSigTimeoutTime_GNMM" SG_ 2654339078 GenericFailSts_FD03_BSM 0;
BA_ "GenSigTimeoutTime_EVCU2" SG_ 2654339078 GenericFailSts_FD03_BSM 0;
BA_ "GenSigTimeoutTime_ESL" SG_ 2654339078 GenericFailSts_FD03_BSM 0;
BA_ "GenSigTimeoutTime_ECM" SG_ 2654339078 GenericFailSts_FD03_BSM 0;
BA_ "GenSigTimeoutTime_DTCM" SG_ 2654339078 GenericFailSts_FD03_BSM 0;
BA_ "GenSigTimeoutTime_DMSM" SG_ 2654339078 GenericFailSts_FD03_BSM 0;
BA_ "GenSigTimeoutTime_BSM" SG_ 2654339078 GenericFailSts_FD03_BSM 0;
BA_ "GenSigTimeoutTime_AGSM" SG_ 2654339078 GenericFailSts_FD03_BSM 0;
BA_ "GenSigTimeoutTime_ADCAM" SG_ 2654339078 GenericFailSts_FD03_BSM 0;
BA_ "GenSigTimeoutTime_RFHM" SG_ 2654339078 EOL_FD03_BSM 0;
BA_ "GenSigTimeoutTime_MPAD" SG_ 2654339078 EOL_FD03_BSM 0;
BA_ "GenSigTimeoutTime_IPC" SG_ 2654339078 EOL_FD03_BSM 0;
BA_ "GenSigTimeoutTime_GNMM" SG_ 2654339078 EOL_FD03_BSM 0;
BA_ "GenSigTimeoutTime_EVCU2" SG_ 2654339078 EOL_FD03_BSM 0;
BA_ "GenSigTimeoutTime_ESL" SG_ 2654339078 EOL_FD03_BSM 0;
BA_ "GenSigTimeoutTime_ECM" SG_ 2654339078 EOL_FD03_BSM 0;
BA_ "GenSigTimeoutTime_DTCM" SG_ 2654339078 EOL_FD03_BSM 0;
BA_ "GenSigTimeoutTime_DMSM" SG_ 2654339078 EOL_FD03_BSM 0;
BA_ "GenSigTimeoutTime_BSM" SG_ 2654339078 EOL_FD03_BSM 0;
BA_ "GenSigTimeoutTime_AGSM" SG_ 2654339078 EOL_FD03_BSM 0;
BA_ "GenSigTimeoutTime_ADCAM" SG_ 2654339078 EOL_FD03_BSM 0;
BA_ "GenSigTimeoutTime_RFHM" SG_ 2654339078 DES_FD03_BSM 0;
BA_ "GenSigTimeoutTime_MPAD" SG_ 2654339078 DES_FD03_BSM 0;
BA_ "GenSigTimeoutTime_IPC" SG_ 2654339078 DES_FD03_BSM 0;
BA_ "GenSigTimeoutTime_GNMM" SG_ 2654339078 DES_FD03_BSM 0;
BA_ "GenSigTimeoutTime_EVCU2" SG_ 2654339078 DES_FD03_BSM 0;
BA_ "GenSigTimeoutTime_ESL" SG_ 2654339078 DES_FD03_BSM 0;
BA_ "GenSigTimeoutTime_SGW" SG_ 2654486672 CBV_bit0_RepeatMessageRequestBit 0;
BA_ "GenSigTimeoutTime_RFHM" SG_ 2654486672 CBV_bit0_RepeatMessageRequestBit 0;
BA_ "GenSigTimeoutTime_MPAD" SG_ 2654486672 CBV_bit0_RepeatMessageRequestBit 0;
BA_ "GenSigTimeoutTime_IPC" SG_ 2654486672 CBV_bit0_RepeatMessageRequestBit 0;
BA_ "GenSigTimeoutTime_GNMM" SG_ 2654486672 CBV_bit0_RepeatMessageRequestBit 0;
BA_ "GenSigTimeoutTime_EVCU2" SG_ 2654486672 CBV_bit0_RepeatMessageRequestBit 0;
BA_ "GenSigTimeoutTime_ESL" SG_ 2654486672 CBV_bit0_RepeatMessageRequestBit 0;
BA_ "GenSigTimeoutTime_ECM" SG_ 2654486672 CBV_bit0_RepeatMessageRequestBit 0;
BA_ "GenSigTimeoutTime_DTCM" SG_ 2654486672 CBV_bit0_RepeatMessageRequestBit 0;
BA_ "GenSigTimeoutTime_DMSM" SG_ 2654486672 CBV_bit0_RepeatMessageRequestBit 0;
BA_ "GenSigTimeoutTime_BSM" SG_ 2654486672 CBV_bit0_RepeatMessageRequestBit 0;
BA_ "GenSigTimeoutTime_BCM" SG_ 2654486672 CBV_bit0_RepeatMessageRequestBit 0;
BA_ "GenSigTimeoutTime_AGSM" SG_ 2654486672 CBV_bit0_RepeatMessageRequestBit 0;
BA_ "GenSigTimeoutTime_ADCAM" SG_ 2654486672 CBV_bit0_RepeatMessageRequestBit 0;
BA_ "GenSigTimeoutTime_SGW" SG_ 2654486672 CBV_bit1 0;
BA_ "GenSigTimeoutTime_RFHM" SG_ 2654486672 CBV_bit1 0;
BA_ "GenSigTimeoutTime_MPAD" SG_ 2654486672 CBV_bit1 0;
BA_ "GenSigTimeoutTime_IPC" SG_ 2654486672 CBV_bit1 0;
BA_ "GenSigTimeoutTime_GNMM" SG_ 2654486672 CBV_bit1 0;
BA_ "GenSigTimeoutTime_EVCU2" SG_ 2654486672 CBV_bit1 0;
BA_ "GenSigTimeoutTime_ESL" SG_ 2654486672 CBV_bit1 0;
BA_ "GenSigTimeoutTime_ECM" SG_ 2654486672 CBV_bit1 0;
BA_ "GenSigTimeoutTime_DTCM" SG_ 2654486672 CBV_bit1 0;
BA_ "GenSigTimeoutTime_DMSM" SG_ 2654486672 CBV_bit1 0;
BA_ "GenSigTimeoutTime_BSM" SG_ 2654486672 CBV_bit1 0;
BA_ "GenSigTimeoutTime_BCM" SG_ 2654486672 CBV_bit1 0;
BA_ "GenSigTimeoutTime_AGSM" SG_ 2654486672 CBV_bit1 0;
BA_ "GenSigTimeoutTime_ADCAM" SG_ 2654486672 CBV_bit1 0;
BA_ "GenSigTimeoutTime_SGW" SG_ 2654486672 CBV_bit7 0;
BA_ "GenSigTimeoutTime_RFHM" SG_ 2654486672 CBV_bit7 0;
BA_ "GenSigTimeoutTime_MPAD" SG_ 2654486672 CBV_bit7 0;
BA_ "GenSigTimeoutTime_IPC" SG_ 2654486672 CBV_bit7 0;
BA_ "GenSigTimeoutTime_GNMM" SG_ 2654486672 CBV_bit7 0;
BA_ "GenSigTimeoutTime_EVCU2" SG_ 2654486672 CBV_bit7 0;
BA_ "GenSigTimeoutTime_ESL" SG_ 2654486672 CBV_bit7 0;
BA_ "GenSigTimeoutTime_ECM" SG_ 2654486672 CBV_bit7 0;
BA_ "GenSigTimeoutTime_DTCM" SG_ 2654486672 CBV_bit7 0;
BA_ "GenSigTimeoutTime_DMSM" SG_ 2654486672 CBV_bit7 0;
BA_ "GenSigTimeoutTime_BSM" SG_ 2654486672 CBV_bit7 0;
BA_ "GenSigTimeoutTime_BCM" SG_ 2654486672 CBV_bit7 0;
BA_ "GenSigTimeoutTime_AGSM" SG_ 2654486672 CBV_bit7 0;
BA_ "GenSigTimeoutTime_ADCAM" SG_ 2654486672 CBV_bit7 0;
BA_ "GenSigTimeoutTime_SGW" SG_ 2654486672 SourceNodeIdentifier 0;
BA_ "GenSigTimeoutTime_RFHM" SG_ 2654486672 SourceNodeIdentifier 0;
BA_ "GenSigTimeoutTime_MPAD" SG_ 2654486672 SourceNodeIdentifier 0;
BA_ "GenSigTimeoutTime_IPC" SG_ 2654486672 SourceNodeIdentifier 0;
BA_ "GenSigTimeoutTime_GNMM" SG_ 2654486672 SourceNodeIdentifier 0;
BA_ "GenSigTimeoutTime_EVCU2" SG_ 2654486672 SourceNodeIdentifier 0;
BA_ "GenSigTimeoutTime_ESL" SG_ 2654486672 SourceNodeIdentifier 0;
BA_ "GenSigTimeoutTime_ECM" SG_ 2654486672 SourceNodeIdentifier 0;
BA_ "GenSigTimeoutTime_DTCM" SG_ 2654486672 SourceNodeIdentifier 0;
BA_ "GenSigTimeoutTime_DMSM" SG_ 2654486672 SourceNodeIdentifier 0;
BA_ "GenSigTimeoutTime_BSM" SG_ 2654486672 SourceNodeIdentifier 0;
BA_ "GenSigTimeoutTime_BCM" SG_ 2654486672 SourceNodeIdentifier 0;
BA_ "GenSigTimeoutTime_AGSM" SG_ 2654486672 SourceNodeIdentifier 0;
BA_ "GenSigTimeoutTime_ADCAM" SG_ 2654486672 SourceNodeIdentifier 0;
BA_ "GenSigTimeoutTime_SGW" SG_ 2654486672 CBV_bit6_PartialNtwInfBit 0;
BA_ "GenSigTimeoutTime_RFHM" SG_ 2654486672 CBV_bit6_PartialNtwInfBit 0;
BA_ "GenSigTimeoutTime_MPAD" SG_ 2654486672 CBV_bit6_PartialNtwInfBit 0;
BA_ "GenSigTimeoutTime_RFHM" SG_ 2654339075 StayActiveSource_FD03_IPC 0;
BA_ "GenSigTimeoutTime_MPAD" SG_ 2654339075 StayActiveSource_FD03_IPC 0;
BA_ "GenSigTimeoutTime_IPC" SG_ 2654339075 StayActiveSource_FD03_IPC 0;
BA_ "GenSigTimeoutTime_GNMM" SG_ 2654339075 StayActiveSource_FD03_IPC 0;
BA_ "GenSigTimeoutTime_EVCU2" SG_ 2654339075 StayActiveSource_FD03_IPC 0;
BA_ "GenSigTimeoutTime_ESL" SG_ 2654339075 StayActiveSource_FD03_IPC 0;
BA_ "GenSigTimeoutTime_ECM" SG_ 2654339075 StayActiveSource_FD03_IPC 0;
BA_ "GenSigTimeoutTime_DTCM" SG_ 2654339075 StayActiveSource_FD03_IPC 0;
BA_ "GenSigTimeoutTime_DMSM" SG_ 2654339075 StayActiveSource_FD03_IPC 0;
BA_ "GenSigTimeoutTime_BSM" SG_ 2654339075 StayActiveSource_FD03_IPC 0;
BA_ "GenSigTimeoutTime_BCM" SG_ 2654339075 StayActiveSource_FD03_IPC 0;
BA_ "GenSigTimeoutTime_AGSM" SG_ 2654339075 StayActiveSource_FD03_IPC 0;
BA_ "GenSigTimeoutTime_ADCAM" SG_ 2654339075 StayActiveSource_FD03_IPC 0;
BA_ "GenSigTimeoutTime_RFHM" SG_ 2654339075 DES_FD03_IPC 0;
BA_ "GenSigTimeoutTime_MPAD" SG_ 2654339075 DES_FD03_IPC 0;
BA_ "GenSigTimeoutTime_IPC" SG_ 2654339075 DES_FD03_IPC 0;
BA_ "GenSigTimeoutTime_GNMM" SG_ 2654339075 DES_FD03_IPC 0;
BA_ "GenSigTimeoutTime_EVCU2" SG_ 2654339075 DES_FD03_IPC 0;
BA_ "GenSigTimeoutTime_ESL" SG_ 2654339075 DES_FD03_IPC 0;
BA_ "GenSigTimeoutTime_ECM" SG_ 2654339075 DES_FD03_IPC 0;
BA_ "GenSigTimeoutTime_DTCM" SG_ 2654339075 DES_FD03_IPC 0;
BA_ "GenSigTimeoutTime_DMSM" SG_ 2654339075 DES_FD03_IPC 0;
BA_ "GenSigTimeoutTime_BSM" SG_ 2654339075 DES_FD03_IPC 0;
BA_ "GenSigTimeoutTime_BCM" SG_ 2654339075 DES_FD03_IPC 0;
BA_ "GenSigTimeoutTime_AGSM" SG_ 2654339075 DES_FD03_IPC 0;
BA_ "GenSigTimeoutTime_ADCAM" SG_ 2654339075 DES_FD03_IPC 0;
BA_ "GenSigTimeoutTime_RFHM" SG_ 2654339075 WakeupSource_FD03_IPC 0;
BA_ "GenSigTimeoutTime_MPAD" SG_ 2654339075 WakeupSource_FD03_IPC 0;
BA_ "GenSigTimeoutTime_IPC" SG_ 2654339075 WakeupSource_FD03_IPC 0;
BA_ "GenSigTimeoutTime_GNMM" SG_ 2654339075 WakeupSource_FD03_IPC 0;
BA_ "GenSigTimeoutTime_EVCU2" SG_ 2654339075 WakeupSource_FD03_IPC 0;
BA_ "GenSigTimeoutTime_ESL" SG_ 2654339075 WakeupSource_FD03_IPC 0;
BA_ "GenSigTimeoutTime_ECM" SG_ 2654339075 WakeupSource_FD03_IPC 0;
BA_ "GenSigTimeoutTime_DTCM" SG_ 2654339075 WakeupSource_FD03_IPC 0;
BA_ "GenSigTimeoutTime_DMSM" SG_ 2654339075 WakeupSource_FD03_IPC 0;
BA_ "GenSigTimeoutTime_BSM" SG_ 2654339075 WakeupSource_FD03_IPC 0;
BA_ "GenSigTimeoutTime_BCM" SG_ 2654339075 WakeupSource_FD03_IPC 0;
BA_ "GenSigTimeoutTime_AGSM" SG_ 2654339075 WakeupSource_FD03_IPC 0;
BA_ "GenSigTimeoutTime_ADCAM" SG_ 2654339075 WakeupSource_FD03_IPC 0;
BA_ "GenSigTimeoutTime_RFHM" SG_ 2654339075 PreviousCanNMState_FD03_IPC 0;
BA_ "GenSigTimeoutTime_MPAD" SG_ 2654339075 PreviousCanNMState_FD03_IPC 0;
BA_ "GenSigTimeoutTime_IPC" SG_ 2654339075 PreviousCanNMState_FD03_IPC 0;
BA_ "GenSigTimeoutTime_GNMM" SG_ 2654339075 PreviousCanNMState_FD03_IPC 0;
BA_ "GenSigTimeoutTime_EVCU2" SG_ 2654339075 PreviousCanNMState_FD03_IPC 0;
BA_ "GenSigTimeoutTime_ESL" SG_ 2654339075 PreviousCanNMState_FD03_IPC 0;
BA_ "GenSigTimeoutTime_ECM" SG_ 2654339075 PreviousCanNMState_FD03_IPC 0;
BA_ "GenSigTimeoutTime_DTCM" SG_ 2654339075 PreviousCanNMState_FD03_IPC 0;
BA_ "GenSigTimeoutTime_DMSM" SG_ 2654339075 PreviousCanNMState_FD03_IPC 0;
BA_ "GenSigTimeoutTime_BSM" SG_ 2654339075 PreviousCanNMState_FD03_IPC 0;
BA_ "GenSigTimeoutTime_BCM" SG_ 2654339075 PreviousCanNMState_FD03_IPC 0;
BA_ "GenSigTimeoutTime_AGSM" SG_ 2654339075 PreviousCanNMState_FD03_IPC 0;
BA_ "GenSigTimeoutTime_ADCAM" SG_ 2654339075 PreviousCanNMState_FD03_IPC 0;
VAL_ 2654339075 GenericFailSts_FD03_IPC 0 "No_Fail_Present" 1 "Fail_Present";
VAL_ 2654339075 EOL_FD03_IPC 0 "No_EOL_Programming" 1 "EOL_Programming";
VAL_ 2654339075 CurrentFailSts_FD03_IPC 0 "No_Fail_Present" 1 "Fail_Present";
VAL_ 2654339093 GenericFailSts_FD03_ESL 0 "No_Fail_Present" 1 "Fail_Present";
VAL_ 2654339093 EOL_FD03_ESL 0 "No_EOL_Programming" 1 "EOL_Programming";
VAL_ 2654339093 CurrentFailSts_FD03_ESL 0 "No_Fail_Present" 1 "Fail_Present";
VAL_ 2654339139 GenericFailSts_FD03_DTCM 0 "No_Fail_Present" 1 "Fail_Present";
VAL_ 2654339139 EOL_FD03_DTCM 0 "No_EOL_Programming" 1 "EOL_Programming";
VAL_ 2654339139 CurrentFailSts_FD03_DTCM 0 "No_Fail_Present" 1 "Fail_Present";
VAL_ 2654339078 GenericFailSts_FD03_BSM 0 "No_Fail_Present" 1 "Fail_Present";
VAL_ 2654339078 EOL_FD03_BSM 0 "No_EOL_Programming" 1 "EOL_Programming";
VAL_ 2654339078 DES_FD03_BSM 0 "Error_Active_state" 1 "Error_passive_warning_state" 2 "Bus_off_state" 3 "Not_used";
VAL_ 2654339078 CurrentFailSts_FD03_BSM 0 "No_Fail_Present" 1 "Fail_Present";
VAL_ 2654339199 GenericFailSts_FD08_VRM 0 "No_Fail_Present" 1 "Fail_Present";
VAL_ 2654339199 EOL_FD08_VRM 0 "No_EOL_Programming" 1 "EOL_Programming";
VAL_ 2654339199 CurrentFailSts_FD08_VRM 0 "No_Fail_Present" 1 "Fail_Present";
VAL_ 2654339107 GenericFailSts_FD08_TBM 0 "No_Fail_Present" 1 "Fail_Present";
VAL_ 2654339107 EOL_FD08_TBM 0 "No_EOL_Programming" 1 "EOL_Programming";
VAL_ 2654339107 CurrentFailSts_FD08_TBM 0 "No_Fail_Present" 1 "Fail_Present";
VAL_ 2654339108 GenericFailSts_FD08_ETM 0 "No_Fail_Present" 1 "Fail_Present";
VAL_ 2654339108 EOL_FD08_ETM 0 "No_EOL_Programming" 1 "EOL_Programming";
VAL_ 2654339108 CurrentFailSts_FD08_ETM 0 "No_Fail_Present" 1 "Fail_Present";
VAL_ 2654339172 GenericFailSts_FD08_DTV 0 "No_Fail_Present" 1 "Fail_Present";
VAL_ 2654339172 EOL_FD08_DTV 0 "No_EOL_Programming" 1 "EOL_Programming";
VAL_ 2654339172 CurrentFailSts_FD08_DTV 0 "No_Fail_Present" 1 "Fail_Present";
VAL_ 2654339216 GenericFailSts_FD03_GNMM 0 "No_Fail_Present" 1 "Fail_Present";
VAL_ 2654339216 EOL_FD03_GNMM 0 "No_EOL_Programming" 1 "EOL_Programming";
VAL_ 2654339216 CurrentFailSts_FD03_GNMM 0 "No_Fail_Present" 1 "Fail_Present";
VAL_ 2654339225 GenericFailSts_FD03_DMSM 0 "No_Fail_Present" 1 "Fail_Present";
VAL_ 2654339225 EOL_FD03_DMSM 0 "No_EOL_Programming" 1 "EOL_Programming";
VAL_ 2654339225 CurrentFailSts_FD03_DMSM 0 "No_Fail_Present" 1 "Fail_Present";
VAL_ 754 VoltBattFailStatus_2 0 "Fail_not_present" 1 "Fail_present";
VAL_ 754 RsErrIBS3_2 0 "NO_ERROR" 1 "ERROR";
VAL_ 754 IBS3_Error_Internal_2 0 "NO_ERROR" 1 "ERROR";
VAL_ 754 CurrBattFailStatus_2 0 "Fail_not_present" 1 "Fail_present";
VAL_ 1460 Safe_State 0 "Not Safe State" 1 "Safe State";
VAL_ 1460 FOTA_Status 0 "No FOTA Event" 1 "Downloading Package from Backend" 2 "Passing Images to Big Target ECUs" 3 "Waiting for HMI Acceptance" 4 "Installing FOTA Updated" 5 "Successful FOTA Update" 6 "FOTA Failure Rollback Successful" 7 "FOTA Failure Complete" 8 "Build Vehicle Library" 9 "Check Campaign Availability" 10 "Check Download Conditions" 11 "Validate Vehicle Package" 12 "Double Check Manifest" 13 "Initiate Authenticated Diagnostic session" 14 "Ready_State" 15 "Rollback";
VAL_ 1438 Driver_Presence 0 "Not_Present" 1 "Present";
VAL_ 1438 DMSM_System_Stat 0 "Standby" 1 "Temp_NA" 2 "Internal_Error" 3 "Functional";
VAL_ 1438 DM_Zone_Track 0 "Unknown" 1 "On_Road" 2 "Cluster" 3 "Left_Mirror" 4 "Right_Mirror" 5 "Radio" 6 "Rear_View_Mirror" 7 "Off_Road";
VAL_ 1438 DM_Drowsy_State 0 "Unknown" 1 "Not_Drowsy" 2 "Partially_Drowsy" 3 "Fully_Drowsy";
VAL_ 1438 DM_Drowsy_Micro 0 "False" 1 "True";
VAL_ 1438 DM_Distract_State 0 "Unknown" 1 "Not_Distracted" 2 "Partially_Distracted" 3 "Fully_Distracted";
VAL_ 1438 DM_Camera_Blind 0 "Unknown" 1 "Not_Occluded" 2 "Partial_Occluded" 3 "Feature_Not_Aval";
VAL_ 524 VehicleStandStillSts_B2 0 "True" 1 "False" 3 "SNA";
VAL_ 524 BSM2_OpStat 0 "Inactive" 1 "FullService" 2 "FailOperational" 3 "FailDegraded" 4 "Emergency" 5 "No_Function";
VAL_ 524 Brake_OpStat_Sec 0 "Inactive" 1 "FullService" 2 "FailOperational" 3 "FailDegraded" 4 "Emergency" 5 "No_Function";
VAL_ 2654339199 WakeupSource_FD08_VRM 0 "No_Wakeup";
VAL_ 2654339199 PreviousCanNMState_FD08_VRM 0 "Uninitialized State" 1 "Bus-Sleep State" 2 "Prepare-Bus State" 3 "Ready-Sleep State" 4 "Normal Operation State" 5 "Repeat Message State" 6 "Synchronize State" 7 "Offline State";
VAL_ 2654339199 DES_FD08_VRM 0 "Error_Active_state" 1 "Error_passive_warning_state" 2 "Bus_off_state" 3 "Not_used";
VAL_ 2654339199 CurrentCanNMState_FD08_VRM 0 "Uninitialized State" 1 "Bus-Sleep State" 2 "Prepare-Bus State" 3 "Ready-Sleep State" 4 "Normal Operation State" 5 "Repeat Message State" 6 "Synchronize State" 7 "Offline State";
VAL_ 2654339107 WakeupSource_FD08_TBM 0 "No_Wakeup" 1 "IGN_ON" 129 "FD1_Psv_WU" 130 "FD2_Psv_WU" 131 "FD3_Psv_WU" 132 "FD4_Psv_WU" 133 "FD5_Psv_WU" 134 "FD6_Psv_WU" 135 "FD7_Psv_WU" 136 "FD8_Psv_WU" 137 "FD9_Psv_WU" 138 "FD10_Psv_WU" 139 "FD11_Psv_WU" 140 "FD12_Psv_WU" 141 "FD13_Psv_WU" 142 "FD14_Psv_WU" 143 "FD15_Psv_WU" 144 "FD16_Psv_WU" 145 "FD17_Psv_WU" 146 "FD18_Psv_WU" 147 "FD19_Psv_WU" 148 "FD20_Psv_WU" 149 "FD21_Psv_WU" 150 "FD22_Psv_WU" 151 "FD23_Psv_WU" 152 "FD24_Psv_WU" 153 "FD25_Psv_WU" 154 "FD26_Psv_WU" 155 "FD27_Psv_WU" 156 "FD28_Psv_WU" 157 "FD29_Psv_WU" 158 "BHCAN_Psv_WU" 159 "CCAN_Psv_WU" 254 "WUSource_Not_Listed";
VAL_ 2654339107 PreviousCanNMState_FD08_TBM 0 "Uninitialized State" 1 "Bus-Sleep State" 2 "Prepare-Bus State" 3 "Ready-Sleep State" 4 "Normal Operation State" 5 "Repeat Message State" 6 "Synchronize State" 7 "Offline State";
VAL_ 2654339107 DES_FD08_TBM 0 "Error_Active_state" 1 "Error_passive_warning_state" 2 "Bus_off_state" 3 "Not_used";
VAL_ 2654339107 CurrentCanNMState_FD08_TBM 0 "Uninitialized State" 1 "Bus-Sleep State" 2 "Prepare-Bus State" 3 "Ready-Sleep State" 4 "Normal Operation State" 5 "Repeat Message State" 6 "Synchronize State" 7 "Offline State";
VAL_ 1438 DM_Eyes_Tracked 0 "False" 1 "True";
VAL_ 2654339075 WakeupSource_FD03_IPC 0 "No_Wakeup";
VAL_ 2654339075 PreviousCanNMState_FD03_IPC 0 "Uninitialized State" 1 "Bus-Sleep State" 2 "Prepare-Bus State" 3 "Ready-Sleep State" 4 "Normal Operation State" 5 "Repeat Message State" 6 "Synchronize State" 7 "Offline State";
VAL_ 2654339075 DES_FD03_IPC 0 "Error_Active_state" 1 "Error_passive_warning_state" 2 "Bus_off_state" 3 "Not_used";
VAL_ 2654339075 CurrentCanNMState_FD03_IPC 0 "Uninitialized State" 1 "Bus-Sleep State" 2 "Prepare-Bus State" 3 "Ready-Sleep State" 4 "Normal Operation State" 5 "Repeat Message State" 6 "Synchronize State" 7 "Offline State";
VAL_ 2654339216 WakeupSource_FD03_GNMM 0 "No_Wakeup" 1 "IGN_ON" 2 "HAS_St_equals_ENGAGED" 129 "FD1_Psv_WU" 130 "FD2_Psv_WU" 131 "FD3_Psv_WU" 132 "FD4_Psv_WU" 133 "FD5_Psv_WU" 134 "FD6_Psv_WU" 135 "FD7_Psv_WU" 136 "FD8_Psv_WU" 137 "FD9_Psv_WU" 138 "FD10_Psv_WU" 139 "FD11_Psv_WU" 140 "FD12_Psv_WU" 141 "FD13_Psv_WU" 142 "FD14_Psv_WU" 143 "FD15_Psv_WU" 144 "FD16_Psv_WU" 145 "FD17_Psv_WU" 146 "FD18_Psv_WU" 147 "FD19_Psv_WU" 148 "FD20_Psv_WU" 149 "FD21_Psv_WU" 150 "FD22_Psv_WU" 151 "FD23_Psv_WU" 152 "FD24_Psv_WU" 153 "FD25_Psv_WU" 154 "FD26_Psv_WU" 155 "FD27_Psv_WU" 156 "FD28_Psv_WU" 157 "FD29_Psv_WU" 158 "BHCAN_Psv_WU" 159 "CCAN_Psv_WU" 254 "WUSource_Not_Listed";
VAL_ 2654339216 PreviousCanNMState_FD03_GNMM 0 "Uninitialized State" 1 "Bus-Sleep State" 2 "Prepare-Bus State" 3 "Ready-Sleep State" 4 "Normal Operation State" 5 "Repeat Message State" 6 "Synchronize State" 7 "Offline State";
VAL_ 2654339216 DES_FD03_GNMM 0 "Error_Active_state" 1 "Error_passive_warning_state" 2 "Bus_off_state" 3 "Not_used";
VAL_ 2654339216 CurrentCanNMState_FD03_GNMM 0 "Uninitialized State" 1 "Bus-Sleep State" 2 "Prepare-Bus State" 3 "Ready-Sleep State" 4 "Normal Operation State" 5 "Repeat Message State" 6 "Synchronize State" 7 "Offline State";
VAL_ 2654339108 WakeupSource_FD08_ETM 0 "No_Wakeup" 1 "IGN_ON" 129 "FD1_Psv_WU" 130 "FD2_Psv_WU" 131 "FD3_Psv_WU" 132 "FD4_Psv_WU" 133 "FD5_Psv_WU" 134 "FD6_Psv_WU" 135 "FD7_Psv_WU" 136 "FD8_Psv_WU" 137 "FD9_Psv_WU" 138 "FD10_Psv_WU" 139 "FD11_Psv_WU" 140 "FD12_Psv_WU" 141 "FD13_Psv_WU" 142 "FD14_Psv_WU" 143 "FD15_Psv_WU" 144 "FD16_Psv_WU" 145 "FD17_Psv_WU" 146 "FD18_Psv_WU" 147 "FD19_Psv_WU" 148 "FD20_Psv_WU" 149 "FD21_Psv_WU" 150 "FD22_Psv_WU" 151 "FD23_Psv_WU" 152 "FD24_Psv_WU" 153 "FD25_Psv_WU" 154 "FD26_Psv_WU" 155 "FD27_Psv_WU" 156 "FD28_Psv_WU" 157 "FD29_Psv_WU" 158 "BHCAN_Psv_WU" 159 "CCAN_Psv_WU" 254 "WUSource_Not_Listed";
VAL_ 2654339108 PreviousCanNMState_FD08_ETM 0 "Uninitialized State" 1 "Bus-Sleep State" 2 "Prepare-Bus State" 3 "Ready-Sleep State" 4 "Normal Operation State" 5 "Repeat Message State" 6 "Synchronize State" 7 "Offline State";
VAL_ 2654339108 DES_FD08_ETM 0 "Error_Active_state" 1 "Error_passive_warning_state" 2 "Bus_off_state" 3 "Not_used";
VAL_ 2654339108 CurrentCanNMState_FD08_ETM 0 "Uninitialized State" 1 "Bus-Sleep State" 2 "Prepare-Bus State" 3 "Ready-Sleep State" 4 "Normal Operation State" 5 "Repeat Message State" 6 "Synchronize State" 7 "Offline State";
VAL_ 2654339093 WakeupSource_FD03_ESL 0 "No_Wakeup";
VAL_ 2654339093 PreviousCanNMState_FD03_ESL 0 "Uninitialized State" 1 "Bus-Sleep State" 2 "Prepare-Bus State" 3 "Ready-Sleep State" 4 "Normal Operation State" 5 "Repeat Message State" 6 "Synchronize State" 7 "Offline State";
VAL_ 2654339093 DES_FD03_ESL 0 "Error_Active_state" 1 "Error_passive_warning_state" 2 "Bus_off_state" 3 "Not_used";
VAL_ 2654339093 CurrentCanNMState_FD03_ESL 0 "Uninitialized State" 1 "Bus-Sleep State" 2 "Prepare-Bus State" 3 "Ready-Sleep State" 4 "Normal Operation State" 5 "Repeat Message State" 6 "Synchronize State" 7 "Offline State";
VAL_ 2654339172 WakeupSource_FD08_DTV 0 "No_Wakeup" 1 "IGN_ON" 129 "FD1_Psv_WU" 130 "FD2_Psv_WU" 131 "FD3_Psv_WU" 132 "FD4_Psv_WU" 133 "FD5_Psv_WU" 134 "FD6_Psv_WU" 135 "FD7_Psv_WU" 136 "FD8_Psv_WU" 137 "FD9_Psv_WU" 138 "FD10_Psv_WU" 139 "FD11_Psv_WU" 140 "FD12_Psv_WU" 141 "FD13_Psv_WU" 142 "FD14_Psv_WU" 143 "FD15_Psv_WU" 144 "FD16_Psv_WU" 145 "FD17_Psv_WU" 146 "FD18_Psv_WU" 147 "FD19_Psv_WU" 148 "FD20_Psv_WU" 149 "FD21_Psv_WU" 150 "FD22_Psv_WU" 151 "FD23_Psv_WU" 152 "FD24_Psv_WU" 153 "FD25_Psv_WU" 154 "FD26_Psv_WU" 155 "FD27_Psv_WU" 156 "FD28_Psv_WU" 157 "FD29_Psv_WU" 158 "BHCAN_Psv_WU" 159 "CCAN_Psv_WU" 254 "WUSource_Not_Listed";
VAL_ 2654339172 PreviousCanNMState_FD08_DTV 0 "Uninitialized State" 1 "Bus-Sleep State" 2 "Prepare-Bus State" 3 "Ready-Sleep State" 4 "Normal Operation State" 5 "Repeat Message State" 6 "Synchronize State" 7 "Offline State";
VAL_ 2654339172 DES_FD08_DTV 0 "Error_Active_state" 1 "Error_passive_warning_state" 2 "Bus_off_state" 3 "Not_used";
VAL_ 2654339172 CurrentCanNMState_FD08_DTV 0 "Uninitialized State" 1 "Bus-Sleep State" 2 "Prepare-Bus State" 3 "Ready-Sleep State" 4 "Normal Operation State" 5 "Repeat Message State" 6 "Synchronize State" 7 "Offline State";
VAL_ 2654339139 WakeupSource_FD03_DTCM 0 "No_Wakeup";
VAL_ 2654339139 PreviousCanNMState_FD03_DTCM 0 "Uninitialized State" 1 "Bus-Sleep State" 2 "Prepare-Bus State" 3 "Ready-Sleep State" 4 "Normal Operation State" 5 "Repeat Message State" 6 "Synchronize State" 7 "Offline State";
VAL_ 2654339139 DES_FD03_DTCM 0 "Error_Active_state" 1 "Error_passive_warning_state" 2 "Bus_off_state" 3 "Not_used";
VAL_ 2654339139 CurrentCanNMState_FD03_DTCM 0 "Uninitialized State" 1 "Bus-Sleep State" 2 "Prepare-Bus State" 3 "Ready-Sleep State" 4 "Normal Operation State" 5 "Repeat Message State" 6 "Synchronize State" 7 "Offline State";
VAL_ 2654339225 WakeupSource_FD03_DMSM 0 "No_Wakeup";
VAL_ 2654339225 PreviousCanNMState_FD03_DMSM 0 "Uninitialized State" 1 "Bus-Sleep State" 2 "Prepare-Bus State" 3 "Ready-Sleep State" 4 "Normal Operation State" 5 "Repeat Message State" 6 "Synchronize State" 7 "Offline State";
VAL_ 2654339225 DES_FD03_DMSM 0 "Error_Active_state" 1 "Error_passive_warning_state" 2 "Bus_off_state" 3 "Not_used";
VAL_ 2654339225 CurrentCanNMState_FD03_DMSM 0 "Uninitialized State" 1 "Bus-Sleep State" 2 "Prepare-Bus State" 3 "Ready-Sleep State" 4 "Normal Operation State" 5 "Repeat Message State" 6 "Synchronize State" 7 "Offline State";
VAL_ 2654339078 WakeupSource_FD03_BSM 0 "No_Wakeup" 1 "IGN_ON" 131 "FD3_Psv_WU" 254 "WUSource_Not_Listed" 255 "HW_DIA_WU";
VAL_ 2654339078 PreviousCanNMState_FD03_BSM 0 "Uninitialized State" 1 "Bus-Sleep State" 2 "Prepare-Bus State" 3 "Ready-Sleep State" 4 "Normal Operation State" 5 "Repeat Message State" 6 "Synchronize State" 7 "Offline State";
VAL_ 2654339078 CurrentCanNMState_FD03_BSM 0 "Uninitialized State" 1 "Bus-Sleep State" 2 "Prepare-Bus State" 3 "Ready-Sleep State" 4 "Normal Operation State" 5 "Repeat Message State" 6 "Synchronize State" 7 "Offline State";
VAL_ 2654486672 CBV_bit6_PartialNtwInfBit 0 "NM_PDU_contains_no_Partial_Network_request_information" 1 "NM_PDU_contains_Partial_Network_request_information";
VAL_ 2654486672 CBV_bit4_ActiveWakeupBit 0 "PassiveWakeup" 1 "ActiveWakeup";
VAL_ 2654486672 CBV_bit3_NMCoordinatorBit 0 "Start_of_synchronized_shutdown_is_not_requested_by_main_coordinator" 1 "Start_of_synchronized_shutdown_is_requested_by_main_coordinator";
VAL_ 2654486672 CBV_bit0_RepeatMessageRequestBit 0 "Repeat_Message_State_not_requested" 1 "Repeat_Message_State_requested";
VAL_ 1460 FOTA_Purge 0 "Do_Not_Purge" 1 "Purge";
VAL_ 1438 DM_Unresponsive 0 "Unknown" 1 "Unresponsive" 2 "Responsive";
VAL_ 1438 DM_Drowsy_Level 0 "Unknown" 1 "Level_1" 2 "Level_2" 3 "Level_3" 4 "Level_4" 5 "Level_5" 6 "Level_6" 7 "Level_7" 8 "Level_8" 9 "Level_9" 10 "Level_10";
VAL_ 1438 DM_Distracted_Level 0 "Unknown" 1 "Level_1" 2 "Level_2" 3 "Level_3" 4 "Level_4" 5 "Level_5" 6 "Level_6" 7 "Level_7" 8 "Level_8" 9 "Level_9" 10 "Level_10";
VAL_ 1460 MPFC_Big_ECU_Package 0 "No_Package" 1 "Package_Available";
VAL_ 1460 FOTA_Installation_Status 0 "Default" 1 "Installation_Started" 2 "Installation_Complete" 3 "Reserved";
VAL_ 257 Ft_RrTrqCoupling_ModeRq_B2 0 "FREE" 1 "HOLD" 2 "OPEN" 3 "SNA";
VAL_ 257 Ft_RrAxleCoupling_TrqRq_B2 255 "SNA";
VAL_ 1460 FOTA_Install_Type 0 "No FOTA" 1 "FOTA Now" 2 "FOTA Schedule" 3 "FOTA Cancelled";
VAL_ 2654339078 StayActiveSource_FD03_BSM 0 "CANNM_Ready_Sleep" 1 "IGN_ON" 2 "NonDefault_Diag" 4 "ING_OFF_NormSt_RptSt" 8 "EPB_Switch_Apply_Release_Request" 10 "Brake_Pedal_Pressed" 20 "Vahicle_is_Moving" 1073741824 "SASource_Not_Listed";
VAL_ 1460 MPAD_Big_ECU_Package 0 "No Package" 1 "Package Available";
VAL_ 1460 ADCAM_Big_ECU_Package 0 "No Package" 1 "Package Available";
VAL_ 1438 DM_Steering_Angle_Blockage 0 "False" 1 "True";
VAL_ 2654339107 StayActiveSource_FD08_TBM 0 "CANNM_Ready_Sleep" 1 "IGN_ON" 2 "NonDefault_Diag" 4 "ING_OFF_NormSt_RptSt" 1073741824 "SASource_Not_Listed";
VAL_ 2654339216 StayActiveSource_FD03_GNMM 0 "CANNM_Ready_Sleep" 1 "IGN_ON" 2 "NonDefault_Diag" 4 "ING_OFF_NormSt_RptSt" 8 "HAS_St_equals_ENGAGED" 1073741824 "SASource_Not_Listed";
VAL_ 2654339108 StayActiveSource_FD08_ETM 0 "CANNM_Ready_Sleep" 1 "IGN_ON" 2 "NonDefault_Diag" 4 "ING_OFF_NormSt_RptSt" 1073741824 "SASource_Not_Listed";
VAL_ 2654339172 StayActiveSource_FD08_DTV 0 "CANNM_Ready_Sleep" 1 "IGN_ON" 2 "NonDefault_Diag" 4 "ING_OFF_NormSt_RptSt" 1073741824 "SASource_Not_Listed";
SIG_GROUP_ 754 IBS3_DATA_1_2_Pkt 1 : VoltBattFailStatus_2 RsErrIBS3_2 IBS3_Error_Internal_2 CurrBattFailStatus_2 MessageCounter_IBS3DATA1_2 CRC_IBS3DATA1_2;
SIG_GROUP_ 1460 FOTA_MASTER_Pkt 1 : Safe_State FOTA_Status FOTA_Purge FOTA_Installation_Status FOTA_Install_Type MPAD_Big_ECU_Package ADCAM_Big_ECU_Package MessageCounter_FOTA_MASTER CRC_FOTA_MASTER MPFC_Big_ECU_Package;
